VERSION "HNNBNNNYNNNNNNNNNNNNNNNNNNNNNNNNNNNNNNNNNN/4/%%%/4/'%**4NNN///"

NS_ :

BS_:

BU_: AFS Airbag Allrad BAP_Tester BMS_Hybrid Bremse_MK60EC Bremse_MK70MABS Bremse_TRW_EBC450M Bremse_TRW_ESP Daempfer EPB_TRW EPB_TRW_VW411CS FLA Gateway_PQ35 Gateway_Zusatz_EGolf Getriebe_AG6 Getriebe_DQ Getriebe_DQ_Hyb Getriebe_Sele Gurtmikro_PQ35 HCA Ladegeraet_EGolf LEH_Hybrid LH_EPS_APA LH_EPS_ZF_2G LH_EPS_ZF_3G LPG_Interface_Box LWR LWS Magne_Ride Motor_Diesel Motor_EGolf Motor_Hybrid Motor_Otto PDC_PLA Quersperre_VAQ RKA_Plus SAK Waehlhebel Waehlhebel_Sele

BO_ 1160 Motor_6: 8 Motor_Diesel
 SG_ MO6_Checksum : 0|8@1+ (1,0) [0|255] "" Vector__XXX
 SG_ MO6_SollM_Getr : 8|8@1+ (0.39,0) [0|99.06] "Unit_PerCent"  Getriebe_DQ,Getriebe_DQ_Hyb,Getriebe_Sele
 SG_ MO6_Ist_Moment : 16|8@1+ (0.39,0) [0|99.06] "Unit_PerCent"  Gateway_PQ35,Getriebe_AG6,Getriebe_DQ,Getriebe_DQ_Hyb,Getriebe_Sele
 SG_ MO6_Hoeheninfo : 24|8@1+ (0.0078125,0) [0|1.984375] ""  Getriebe_DQ,Getriebe_DQ_Hyb
 SG_ MO6_GRA_Soll : 32|8@1+ (0.024,-3.984) [-3.984|2.088] "Unit_MeterPerSeconSquar"  Getriebe_AG6,Getriebe_DQ,Getriebe_DQ_Hyb
 SG_ MO6_MomIntGeEing : 40|8@1+ (0.392156862745098,0) [0|100] "Unit_PerCent"  Getriebe_DQ,Getriebe_DQ_Hyb
 SG_ MO6_FF_Mux00 m0 : 48|8@1+ (0.392156862745098,0) [0|100] "Unit_PerCent"  BMS_Hybrid,Getriebe_DQ,Getriebe_DQ_Hyb,Getriebe_Sele,LEH_Hybrid
 SG_ MO6_FF_Mux01 m1 : 48|8@1+ (0.392156862745098,0) [0|100] "Unit_PerCent"  BMS_Hybrid,Getriebe_DQ,Getriebe_DQ_Hyb,Getriebe_Sele,LEH_Hybrid
 SG_ MO6_FF_Mux02 m2 : 48|8@1+ (1,-40) [-40|215] "Unit_DegreCelsi"  BMS_Hybrid,Getriebe_DQ,Getriebe_DQ_Hyb,Getriebe_Sele,LEH_Hybrid
 SG_ MO6_FF_Mux03 m3 : 48|8@1+ (3.13725490196078,0) [0|799.999999999999] "Unit_PerCent"  BMS_Hybrid,Getriebe_DQ,Getriebe_DQ_Hyb,Getriebe_Sele,LEH_Hybrid
 SG_ MO6_FF_Mux04 m4 : 48|8@1+ (0.392156862745098,0) [0|100] "Unit_PerCent"  BMS_Hybrid,Getriebe_DQ,Getriebe_DQ_Hyb,Getriebe_Sele,LEH_Hybrid
 SG_ MO6_FF_Mux05 m5 : 48|8@1+ (1,0) [0|255] "" Vector__XXX
 SG_ MO6_FF_Mux06 m6 : 48|8@1+ (1,0) [0|255] "" Vector__XXX
 SG_ MO6_FF_Mux07 m7 : 48|8@1+ (1,0) [0|255] "" Vector__XXX
 SG_ MO6_FF_Mux08 m8 : 48|8@1+ (1,0) [0|255] "" Vector__XXX
 SG_ MO6_FF_Mux09 m9 : 48|8@1+ (1,0) [0|255] "" Vector__XXX
 SG_ MO6_FF_Mux10 m10 : 48|8@1+ (1,0) [0|255] "" Vector__XXX
 SG_ MO6_FF_Mux11 m11 : 48|8@1+ (1,0) [0|255] "" Vector__XXX
 SG_ MO6_FF_Mux12 m12 : 48|8@1+ (1,0) [0|255] "" Vector__XXX
 SG_ MO6_FF_Mux13 m13 : 48|8@1+ (1,0) [0|255] "" Vector__XXX
 SG_ MO6_FF_Mux14 m14 : 48|8@1+ (1,0) [0|255] "" Vector__XXX
 SG_ MO6_FF_Mux15 m15 : 48|8@1+ (1,0) [0|255] "" Vector__XXX
 SG_ MO6_Freigabe_GRA : 56|1@1+ (1,0) [0|1] ""  Getriebe_DQ,Getriebe_DQ_Hyb
 SG_ MO6_Schutz_Toel : 57|1@1+ (1,0) [0|1] "" Vector__XXX
 SG_ MO6_Luftpfad_akt : 58|1@1+ (1,0) [0|1] "" Vector__XXX
 SG_ MO6_RegPartikel : 59|1@1+ (1,0) [0|1] ""  Getriebe_AG6,Getriebe_DQ,Getriebe_DQ_Hyb
 SG_ MO6_Zaehler M : 60|4@1+ (1,0) [0|15] ""  BMS_Hybrid,Getriebe_DQ,Getriebe_DQ_Hyb,LEH_Hybrid

BO_ 1416 Motor_7: 8 Motor_Diesel
 SG_ MO7_LL_Solldz : 0|1@1+ (1,0) [0|1] ""  Gateway_PQ35
 SG_ MO7_Fehler_VBegr : 1|1@1+ (1,0) [0|1] ""  Gateway_PQ35
 SG_ MO7_Sta_VBegr : 2|1@1+ (1,0) [0|1] ""  Gateway_PQ35,Getriebe_DQ,Getriebe_DQ_Hyb
 SG_ MO7_Fehlereintr : 3|1@1+ (1,0) [0|1] ""  Gateway_PQ35
 SG_ MO7_StaOeltemp : 4|1@1+ (1,0) [0|1] ""  Gateway_PQ35,Getriebe_DQ,Getriebe_DQ_Hyb
 SG_ MO7_Sta_PTC : 5|3@1+ (1,0) [0|7] ""  Gateway_PQ35
 SG_ MO7_DFM : 8|8@1+ (0.4,0) [0|101.6] "Unit_PerCent"  Gateway_PQ35
 SG_ MO7_Hoeheninfo : 16|8@1+ (0.0078125,0) [0|1.984375] ""  Bremse_MK60EC,Bremse_MK70MABS,Bremse_TRW_EBC450M,Bremse_TRW_ESP,Gateway_PQ35,Getriebe_DQ,Getriebe_DQ_Hyb,Getriebe_Sele
 SG_ MO7_Gradient_Dz : 24|7@1+ (1,0) [0|126] "Unit_MinutInver"  Gateway_PQ35
 SG_ MO7_GradientVorz : 31|1@1+ (1,0) [0|1] ""  Gateway_PQ35
 SG_ MO7_Ladedruckneu : 32|8@1+ (0.02,0) [0|5.08] "Unit_Bar"  Gateway_PQ35
 SG_ MO7_GenLdResp : 40|2@1+ (3,0) [0|9] "Unit_Secon"  Gateway_PQ35
 SG_ MO7_PTC_bereit : 42|2@1+ (1,0) [0|3] ""  Gateway_PQ35
 SG_ MO7_Mot_weckfaehig : 44|1@1+ (1,0) [0|1] ""  Gateway_PQ35
 SG_ MO7_Zus_Kuehl : 45|1@1+ (1,0) [0|1] ""  Gateway_PQ35
 SG_ MO7_SleepInd : 46|1@1+ (1,0) [0|1] ""  Gateway_PQ35
 SG_ MO7_RueckLLDz : 47|1@1+ (1,0) [0|1] ""  Gateway_PQ35
 SG_ MO7_Lastabwurf : 48|2@1+ (1,0) [0|3] ""  Gateway_PQ35
 SG_ MO7_Gen_ein : 50|1@1+ (1,0) [0|1] ""  Gateway_PQ35
 SG_ MO7_Lastabw_Heiz : 51|1@1+ (1,0) [0|1] ""  Gateway_PQ35
 SG_ MO7_StaGluehk : 52|4@1+ (8,0) [0|112] "Unit_PerCent"  Gateway_PQ35
 SG_ MO7_Oeltemp : 56|8@1+ (1,-60) [-58|194] "Unit_DegreCelsi"  Gateway_PQ35,Getriebe_DQ,Getriebe_DQ_Hyb,Getriebe_Sele

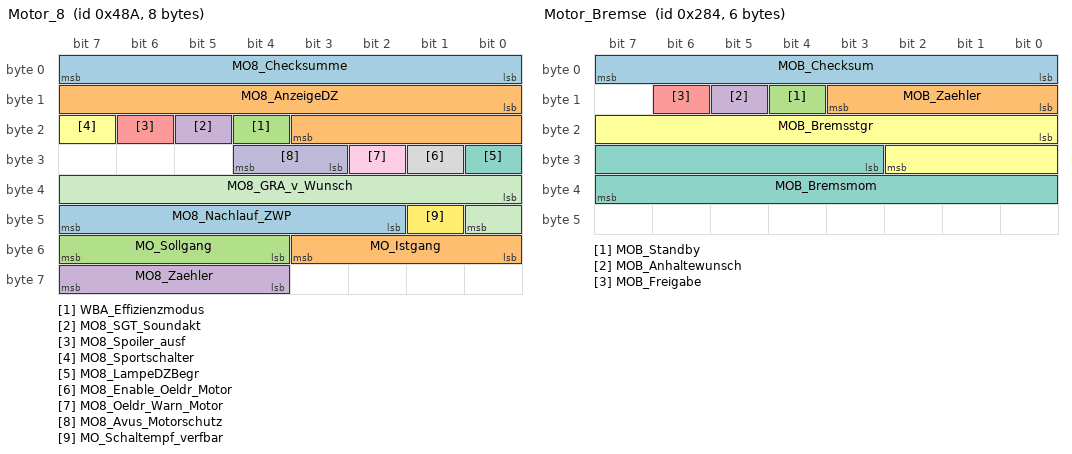
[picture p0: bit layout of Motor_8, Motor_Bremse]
BO_ 1162 Motor_8: 8 Motor_Diesel
 SG_ MO8_Checksumme : 0|8@1+ (1,0) [0|255] ""  Gateway_PQ35,Magne_Ride
 SG_ MO8_AnzeigeDZ : 8|12@1+ (3,0) [0|12282] "Unit_MinutInver"  Gateway_PQ35
 SG_ WBA_Effizienzmodus : 20|1@1+ (1,0) [0|1] ""  Gateway_PQ35
 SG_ MO8_SGT_Soundakt : 21|1@1+ (1,0) [0|1] ""  Gateway_PQ35,SAK
 SG_ MO8_Spoiler_ausf : 22|1@1+ (1,0) [0|1] ""  Gateway_PQ35
 SG_ MO8_Sportschalter : 23|1@1+ (1,0) [0|1] ""  Gateway_PQ35,Getriebe_Sele,Magne_Ride
 SG_ MO8_LampeDZBegr : 24|1@1+ (1,0) [0|1] ""  Gateway_PQ35,Getriebe_Sele
 SG_ MO8_Enable_Oeldr_Motor : 25|1@1+ (1,0) [0|1] ""  Gateway_PQ35
 SG_ MO8_Oeldr_Warn_Motor : 26|1@1+ (1,0) [0|1] ""  Gateway_PQ35
 SG_ MO8_Avus_Motorschutz : 27|2@1+ (1,0) [0|3] ""  Gateway_PQ35,Getriebe_Sele
 SG_ MO8_GRA_v_Wunsch : 32|9@1+ (1,0) [0|511] "Unit_KiloMeterPerHour"  Gateway_PQ35
 SG_ MO_Schaltempf_verfbar : 41|1@1+ (1,0) [0|1] ""  Gateway_PQ35
 SG_ MO8_Nachlauf_ZWP : 42|6@1+ (15,0) [0|945] "Unit_Secon"  Gateway_PQ35
 SG_ MO_Istgang : 48|4@1+ (1,0) [0|15] ""  Gateway_PQ35
 SG_ MO_Sollgang : 52|4@1+ (1,0) [0|15] ""  Gateway_PQ35
 SG_ MO8_Zaehler : 60|4@1+ (1,0) [0|15] ""  Gateway_PQ35,Magne_Ride

BO_ 644 Motor_Bremse: 6 Motor_Diesel
 SG_ MOB_Checksum : 0|8@1+ (1,0) [0|255] ""  Bremse_MK60EC,Bremse_TRW_EBC450M,Bremse_TRW_ESP
 SG_ MOB_Zaehler : 8|4@1+ (1,0) [0|15] ""  Bremse_MK60EC,Bremse_TRW_EBC450M,Bremse_TRW_ESP
 SG_ MOB_Standby : 12|1@1+ (1,0) [0|1] ""  Bremse_MK60EC,Bremse_TRW_EBC450M,Bremse_TRW_ESP
 SG_ MOB_Anhaltewunsch : 13|1@1+ (1,0) [0|1] ""  Bremse_TRW_EBC450M,Bremse_TRW_ESP,Getriebe_DQ
 SG_ MOB_Freigabe : 14|1@1+ (1,0) [0|1] ""  Bremse_MK60EC,Bremse_TRW_EBC450M,Bremse_TRW_ESP,Gateway_PQ35
 SG_ MOB_Bremsstgr : 16|11@1+ (0.0488519785051295,0) [0|100] "Unit_PerCent"  Bremse_TRW_EBC450M,Bremse_TRW_ESP
 SG_ MOB_Bremsmom : 27|13@1+ (4,0) [0|32760] "Unit_NewtoMeter"  Bremse_MK60EC

BO_ 1800 Motor_CNG_1: 5 Motor_Otto
 SG_ MC1_Anz_Betrieb : 0|1@1+ (1,0) [0|1] ""  Gateway_PQ35
 SG_ MC1_Schalter : 1|1@1+ (1,0) [0|1] ""  Gateway_PQ35
 SG_ MC1_akt_Betrieb : 2|1@1+ (1,0) [0|1] ""  Gateway_PQ35
 SG_ MC1_CNG_LPG M : 3|1@1+ (1,0) [0|1] ""  Gateway_PQ35
 SG_ MO_LPG_Tankstopp m1 : 4|1@1+ (1,0) [0|1] ""  Gateway_PQ35
 SG_ MO_Erdgasqualitaet : 5|3@1+ (1,0) [0|7] ""  Gateway_PQ35
 SG_ MC1_Fuellungsgrad : 8|8@1+ (0.4,0) [0|101.6] "Unit_PerCent"  Gateway_PQ35
 SG_ MC1_Verbrauch m0 : 16|15@1+ (1,0) [0|32767] "Unit_MilliGram"  Gateway_PQ35
 SG_ MC1_Verbrauch_LPG m1 : 16|15@1+ (1,0) [0|32767] "Unit_MicroLiter"  Gateway_PQ35
 SG_ MC1_Ueb_Verbr : 31|1@1+ (1,0) [0|1] ""  Gateway_PQ35
 SG_ MO_AnzeigeGasbetrieb : 32|4@1+ (1,0) [0|15] ""  Gateway_PQ35

BO_ 1408 Motor_Flexia_neu: 8 Motor_Diesel
 SG_ MFN_Zaehler M : 0|2@1+ (1,0) [0|3] ""  Bremse_TRW_EBC450M,Bremse_TRW_ESP,EPB_TRW,EPB_TRW_VW411CS,Gateway_PQ35,Gateway_Zusatz_EGolf
 SG_ MFN_Zaehler_ : 2|2@1+ (1,0) [0|3] ""  Bremse_TRW_EBC450M,Bremse_TRW_ESP,EPB_TRW,EPB_TRW_VW411CS,Gateway_PQ35,Gateway_Zusatz_EGolf
 SG_ MFN_Drive_Cycle : 4|1@1+ (1,0) [0|1] ""  BMS_Hybrid,Gateway_PQ35,Gateway_Zusatz_EGolf,Getriebe_AG6,Getriebe_DQ,Getriebe_DQ_Hyb,Getriebe_Sele,LEH_Hybrid
 SG_ MFN_Warmup_Cycle : 5|1@1+ (1,0) [0|1] ""  BMS_Hybrid,Bremse_TRW_ESP,Gateway_PQ35,Gateway_Zusatz_EGolf,Getriebe_AG6,Getriebe_DQ,Getriebe_DQ_Hyb,Getriebe_Sele,LEH_Hybrid
 SG_ MFN_NormedTrip : 6|1@1+ (1,0) [0|1] ""  BMS_Hybrid,Gateway_PQ35,Gateway_Zusatz_EGolf,Getriebe_AG6,Getriebe_DQ,Getriebe_DQ_Hyb,Getriebe_Sele,LEH_Hybrid
 SG_ MFN_Verbrenn_Typ : 7|1@1+ (1,0) [0|1] ""  Bremse_TRW_EBC450M,Bremse_TRW_ESP,EPB_TRW,EPB_TRW_VW411CS,Gateway_PQ35,Gateway_Zusatz_EGolf,Getriebe_DQ,Getriebe_DQ_Hyb
 SG_ MFN_Russindex m0 : 8|16@1+ (2E-008,0) [0|0.00131068] ""  Gateway_PQ35,Gateway_Zusatz_EGolf
 SG_ MFN_Verschl m1 : 8|16@1+ (2E-008,0) [0|0.00131068] ""  Gateway_PQ35,Gateway_Zusatz_EGolf
 SG_ MFN_Russindex_ m2 : 8|16@1+ (2E-008,0) [0|0.00131068] ""  Gateway_PQ35,Gateway_Zusatz_EGolf
 SG_ MFN_Verschl_ m3 : 8|16@1+ (2E-008,0) [0|0.00131068] ""  Gateway_PQ35,Gateway_Zusatz_EGolf
 SG_ MFN_Drz_max_Mo m0 : 24|8@1+ (100,0) [0|25500] "Unit_MinutInver"  Gateway_PQ35,Gateway_Zusatz_EGolf
 SG_ MFN_KurzzeitMW m1 : 24|8@1+ (15,-1905) [-1890|1905] "Unit_MilliLiter"  Gateway_PQ35,Gateway_Zusatz_EGolf
 SG_ MFN_Drz_max_Mo_ m2 : 24|8@1+ (100,0) [0|25500] "Unit_MinutInver"  Gateway_PQ35,Gateway_Zusatz_EGolf
 SG_ MFN_Interv_Wmin m3 : 24|7@1+ (1000,0) [0|127000] "Unit_KiloMeter"  Gateway_PQ35,Gateway_Zusatz_EGolf
 SG_ MFN_Fuell_Erk m3 : 31|1@1+ (1,0) [0|1] ""  Gateway_PQ35,Gateway_Zusatz_EGolf
 SG_ MFN_max_Moment m0 : 32|8@1+ (10,0) [0|2550] "Unit_NewtoMeter"  Gateway_PQ35,Gateway_Zusatz_EGolf
 SG_ MFN_Oelstand m1 : 32|6@1+ (1,0) [0|63] ""  Gateway_PQ35,Gateway_Zusatz_EGolf
 SG_ MFN_max_Moment_ m2 : 32|8@1+ (10,0) [0|2550] "Unit_NewtoMeter"  Gateway_PQ35,Gateway_Zusatz_EGolf
 SG_ MFN_Interv_Wmax m3 : 32|7@1+ (1000,0) [0|127000] "Unit_KiloMeter"  Gateway_PQ35,Gateway_Zusatz_EGolf
 SG_ MFN_Oelwarnung m1 : 38|1@1+ (1,0) [0|1] ""  Gateway_PQ35,Gateway_Zusatz_EGolf
 SG_ MFN_Sensorwarn m1 : 39|1@1+ (1,0) [0|1] ""  Gateway_PQ35,Gateway_Zusatz_EGolf
 SG_ MFN_MaxOelst m3 : 39|5@1+ (100,0) [0|3100] "Unit_MilliLiter"  Gateway_PQ35,Gateway_Zusatz_EGolf
 SG_ MFN_Motorleistung m0 : 40|9@1+ (1,0) [0|511] "Unit_KiloWatt"  Bremse_TRW_EBC450M,Bremse_TRW_ESP,EPB_TRW,Gateway_PQ35,Gateway_Zusatz_EGolf
 SG_ MFN_AnzMitOel m1 : 40|4@1+ (100,0) [0|1500] ""  Gateway_PQ35,Gateway_Zusatz_EGolf
 SG_ MFN_Motorleistung_ m2 : 40|9@1+ (1,0) [0|511] "Unit_KiloWatt"  Bremse_TRW_EBC450M,Bremse_TRW_ESP,EPB_TRW,Gateway_PQ35,Gateway_Zusatz_EGolf
 SG_ MFN_Max_Offset m1 : 44|4@1+ (50,0) [0|750] "Unit_MilliLiter"  Gateway_PQ35,Gateway_Zusatz_EGolf
 SG_ MFN_Anz_Mittel m3 : 44|4@1+ (500,0) [500|7500] ""  Gateway_PQ35,Gateway_Zusatz_EGolf
 SG_ MFN_Fuell_Hyst m1 : 48|4@1+ (50,0) [0|750] "Unit_MilliLiter"  Gateway_PQ35,Gateway_Zusatz_EGolf
 SG_ MFN_Interv_tmin m3 : 48|6@1+ (1,0) [0|63] "Unit_Month"  Gateway_PQ35,Gateway_Zusatz_EGolf
 SG_ MFN_Ventile m0 : 49|3@1+ (1,0) [0|7] ""  Gateway_PQ35,Gateway_Zusatz_EGolf
 SG_ MFN_Ventile_ m2 : 49|3@1+ (1,0) [0|7] ""  Gateway_PQ35,Gateway_Zusatz_EGolf
 SG_ MFN_Zylinder m0 : 52|4@1+ (1,0) [0|15] ""  EPB_TRW,Gateway_PQ35,Gateway_Zusatz_EGolf
 SG_ MFN_Offset_Nachf m1 : 52|6@1+ (10,0) [0|630] "Unit_MilliLiter"  Gateway_PQ35,Gateway_Zusatz_EGolf
 SG_ MFN_Zylinder_ m2 : 52|4@1+ (1,0) [0|15] ""  EPB_TRW,Gateway_PQ35,Gateway_Zusatz_EGolf
 SG_ MFN_Interv_tmax m3 : 54|6@1+ (1,0) [0|63] "Unit_Month"  Gateway_PQ35,Gateway_Zusatz_EGolf
 SG_ MFN_Hubraum m0 : 56|7@1+ (0.1,0) [0|12.7] "Unit_Liter"  Bremse_TRW_EBC450M,Bremse_TRW_ESP,EPB_TRW,Gateway_PQ35,Gateway_Zusatz_EGolf
 SG_ MFN_Hubraum_ m2 : 56|7@1+ (0.1,0) [0|12.7] "Unit_Liter"  Bremse_TRW_EBC450M,Bremse_TRW_ESP,EPB_TRW,Gateway_PQ35,Gateway_Zusatz_EGolf
 SG_ MFN_Tol_Oelwarn m1 : 58|6@1+ (10,0) [0|630] "Unit_MilliLiter"  Gateway_PQ35,Gateway_Zusatz_EGolf
 SG_ MFN_Str_Mittel m3 : 60|4@1+ (25,0) [25|375] "Unit_KiloMeter"  Gateway_PQ35,Gateway_Zusatz_EGolf
 SG_ MFN_Ansaugsys m0 : 63|1@1+ (1,0) [0|1] ""  Bremse_TRW_EBC450M,Bremse_TRW_ESP,Gateway_PQ35,Gateway_Zusatz_EGolf
 SG_ MFN_Ansaugsys_ m2 : 63|1@1+ (1,0) [0|1] ""  Bremse_TRW_EBC450M,Bremse_TRW_ESP,Gateway_PQ35,Gateway_Zusatz_EGolf

BO_ 1154 Motor_Hybrid_1: 8 Motor_Hybrid
 SG_ MH1_VM_Mom_oE : 0|8@1+ (0.8,-100) [-100|103.2] "Unit_PerCent"  Getriebe_DQ_Hyb
 SG_ MH1_IstStatusK0 : 8|2@1+ (1,0) [0|3] ""  Getriebe_DQ_Hyb
 SG_ MH1_Startmodus_PQ35 : 10|1@1+ (1,0) [0|1] ""  Getriebe_DQ_Hyb
 SG_ MH1_VM_aktiv : 11|1@1+ (1,0) [0|1] ""  Getriebe_DQ_Hyb
 SG_ MH1_Zielzustand_Hybrid : 12|3@1+ (1,0) [0|7] ""  Getriebe_DQ_Hyb
 SG_ MH1_Schaltverh : 15|1@1+ (1,0) [0|1] ""  Getriebe_DQ_Hyb
 SG_ MH1_VerlParam_Msum m1 : 16|2@1+ (1,0) [0|3] ""  Getriebe_DQ_Hyb
 SG_ MH1_MomVerlauf_EM m1 : 18|6@1+ (5,0) [0|315] "Unit_NewtoMeter"  Getriebe_DQ_Hyb
 SG_ MH1_E_Faktor m0 : 20|4@1+ (1,0) [0|15] ""  Getriebe_DQ_Hyb
 SG_ MH1_Drehzahl_VM : 24|16@1+ (0.25,0) [0|16256] "Unit_MinutInver"  Getriebe_DQ_Hyb
 SG_ MH1_max_ind_VM_Mom : 40|8@1+ (0.39,0) [0|99.06] "Unit_PerCent" Vector__XXX
 SG_ MH1_Startmodus_PL71 : 48|3@1+ (1,0) [0|7] "" Vector__XXX
 SG_ MH1_LowSpeedModus : 51|1@1+ (1,0) [0|1] ""  Getriebe_DQ_Hyb
 SG_ MH1_ACCGRA_aktiv M : 52|1@1+ (1,0) [0|1] ""  Getriebe_DQ_Hyb
 SG_ MH1_QB_Bremspedalwert : 55|1@1+ (1,0) [0|1] "" Vector__XXX
 SG_ MH1_Bremspedalwert : 56|8@1+ (0.4,0) [0|100] "Unit_PerCent"  Getriebe_DQ_Hyb

BO_ 399 mMotor_LPG_01: 8 Motor_Otto
 SG_ Motor_LPG_01_Reserve : 0|64@1+ (1,0) [0|1.84467440737096E+019] ""  LPG_Interface_Box

BO_ 1823 Motorslave_Istverbau: 1 Motor_Otto
 SG_ MSI_KD_Fehler : 0|1@1+ (1,0) [0|1] ""  Gateway_PQ35

BO_ 1428 Niveau_2: 8 Daempfer
 SG_ NI2_Checksum : 0|8@1+ (1,0) [0|255] ""  AFS,Gateway_PQ35,LWR
 SG_ NI2_Zaehler : 8|4@1+ (1,0) [0|15] ""  AFS,Gateway_PQ35,LWR
 SG_ NI2_Hoehenflag M : 12|1@1+ (1,0) [0|1] ""  AFS,Gateway_PQ35
 SG_ NI2_Hoehe_VL m0 : 16|8@1+ (1,-127) [-127|126] "Unit_MilliMeter"  AFS,Gateway_PQ35,LWR
 SG_ NI2_Hoehe_VL_Roh m1 : 16|8@1+ (0.4,0) [0|100] "Unit_PerCent"  AFS,Gateway_PQ35
 SG_ NI2_Hoehe_VR m0 : 24|8@1+ (1,-127) [-127|126] "Unit_MilliMeter"  AFS,Gateway_PQ35,LWR
 SG_ NI2_Hoehe_VR_Roh m1 : 24|8@1+ (0.4,0) [0|100] "Unit_PerCent"  AFS,Gateway_PQ35
 SG_ NI2_Hoehe_HL m0 : 32|8@1+ (1,-127) [-127|126] "Unit_MilliMeter"  AFS,Gateway_PQ35,LWR
 SG_ NI2_Hoehe_HL_Roh m1 : 32|8@1+ (0.4,0) [0|100] "Unit_PerCent"  AFS,Gateway_PQ35
 SG_ NI2_Hoehe_HR m0 : 40|8@1+ (1,-127) [-127|126] "Unit_MilliMeter"  AFS,Gateway_PQ35,LWR
 SG_ NI2_Hoehe_HR_Roh m1 : 40|8@1+ (0.4,0) [0|100] "Unit_PerCent"  AFS,Gateway_PQ35
 SG_ NI2_AufbBeschl_VL : 48|8@1+ (0.08,-10.08) [-10.08|10.08] "Unit_MeterPerSeconSquar"  AFS,Gateway_PQ35
 SG_ NI2_AufbBeschl_VR : 56|8@1+ (0.08,-10.08) [-10.08|10.08] "Unit_MeterPerSeconSquar"  AFS,Gateway_PQ35

BO_ 1349 Parkhilfe_3: 4 Vector__XXX
 SG_ PA3_System_codierung : 0|1@1+ (1,0) [0|1] ""  Gateway_PQ35
 SG_ PA3_Anlage_defekt : 1|1@1+ (1,0) [0|1] ""  Gateway_PQ35
 SG_ PA3_Taster_aktiviert : 2|1@1+ (1,0) [0|1] ""  Gateway_PQ35
 SG_ PA3_Rueckwaertsgang_aktiv : 3|1@1+ (1,0) [0|1] ""  Gateway_PQ35
 SG_ PA3_Geschwindigkeit_aus : 4|1@1+ (1,0) [0|1] ""  Gateway_PQ35
 SG_ PA3_Tongeber_v_defekt : 5|1@1+ (1,0) [0|1] ""  Gateway_PQ35
 SG_ PA3_Tongeber_h_defekt : 6|1@1+ (1,0) [0|1] ""  Gateway_PQ35
 SG_ PA3_Audioabsenkung_Anforderung : 7|1@1+ (1,0) [0|1] ""  Gateway_PQ35
 SG_ PA3_Eis_aus : 8|1@1+ (1,0) [0|1] ""  Gateway_PQ35
 SG_ PA3_Schlechtweg_aus : 9|1@1+ (1,0) [0|1] ""  Gateway_PQ35
 SG_ PA3_KD_Fehler : 15|1@1+ (1,0) [0|1] ""  Gateway_PQ35
 SG_ PA3_Sensor_hll_defekt : 16|1@1+ (1,0) [0|1] ""  Gateway_PQ35
 SG_ PA3_Sensor_hlm_defekt : 17|1@1+ (1,0) [0|1] ""  Gateway_PQ35
 SG_ PA3_Sensor_hrm_defekt : 18|1@1+ (1,0) [0|1] ""  Gateway_PQ35
 SG_ PA3_Sensor_hrr_defekt : 19|1@1+ (1,0) [0|1] ""  Gateway_PQ35
 SG_ PA3_Sensor_vll_defekt : 20|1@1+ (1,0) [0|1] ""  Gateway_PQ35
 SG_ PA3_Sensor_vlm_defekt : 21|1@1+ (1,0) [0|1] ""  Gateway_PQ35
 SG_ PA3_Sensor_vrm_defekt : 22|1@1+ (1,0) [0|1] ""  Gateway_PQ35
 SG_ PA3_Sensor_vrr_defekt : 23|1@1+ (1,0) [0|1] ""  Gateway_PQ35
 SG_ PA3_Bereit : 24|1@1+ (1,0) [0|1] ""  Gateway_PQ35
 SG_ PA3_Bereich_vo : 26|2@1+ (1,0) [0|3] ""  Gateway_PQ35
 SG_ PA3_Bereich_hi : 28|2@1+ (1,0) [0|3] ""  Gateway_PQ35
 SG_ PA3_Akust_aus : 30|1@1+ (1,0) [0|1] ""  Gateway_PQ35
 SG_ PA3_Aufbau_erk : 31|1@1+ (1,0) [0|1] ""  Gateway_PQ35

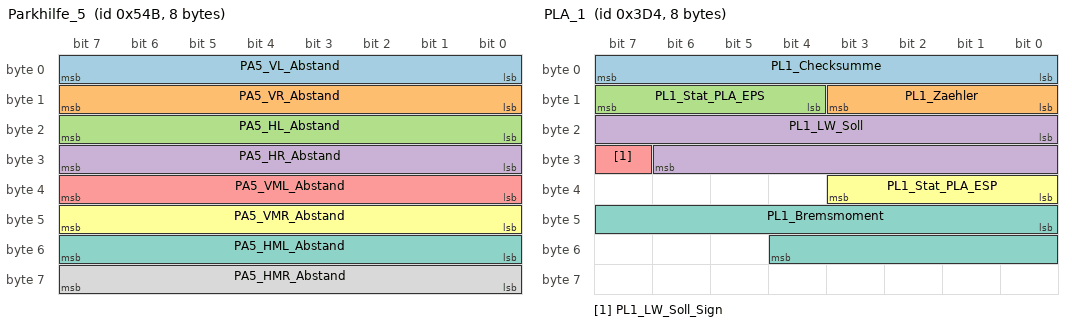
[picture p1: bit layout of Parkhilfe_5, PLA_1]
BO_ 1355 Parkhilfe_5: 8 PDC_PLA
 SG_ PA5_VL_Abstand : 0|8@1+ (1,0) [0|254] "Unit_CentiMeter"  Gateway_PQ35
 SG_ PA5_VR_Abstand : 8|8@1+ (1,0) [0|254] "Unit_CentiMeter"  Gateway_PQ35
 SG_ PA5_HL_Abstand : 16|8@1+ (1,0) [0|254] "Unit_CentiMeter"  Gateway_PQ35
 SG_ PA5_HR_Abstand : 24|8@1+ (1,0) [0|254] "Unit_CentiMeter"  Gateway_PQ35
 SG_ PA5_VML_Abstand : 32|8@1+ (1,0) [0|254] "Unit_CentiMeter"  Gateway_PQ35
 SG_ PA5_VMR_Abstand : 40|8@1+ (1,0) [0|254] "Unit_CentiMeter"  Gateway_PQ35
 SG_ PA5_HML_Abstand : 48|8@1+ (1,0) [0|254] "Unit_CentiMeter"  Gateway_PQ35
 SG_ PA5_HMR_Abstand : 56|8@1+ (1,0) [0|254] "Unit_CentiMeter"  Gateway_PQ35

BO_ 980 PLA_1: 8 PDC_PLA
 SG_ PL1_Checksumme : 0|8@1+ (1,0) [0|255] ""  Getriebe_DQ,Getriebe_DQ_Hyb,LH_EPS_APA,LH_EPS_ZF_2G,LH_EPS_ZF_3G
 SG_ PL1_Zaehler : 8|4@1+ (1,0) [0|15] ""  Bremse_TRW_EBC450M,Getriebe_DQ,Getriebe_DQ_Hyb,LH_EPS_APA,LH_EPS_ZF_2G,LH_EPS_ZF_3G
 SG_ PL1_Stat_PLA_EPS : 12|4@1+ (1,0) [0|15] ""  LH_EPS_APA,LH_EPS_ZF_2G,LH_EPS_ZF_3G
 SG_ PL1_LW_Soll : 16|15@1+ (0.04375,0) [0|1433.55625] "Unit_DegreOfArc"  LH_EPS_APA,LH_EPS_ZF_2G,LH_EPS_ZF_3G
 SG_ PL1_LW_Soll_Sign : 31|1@1+ (1,0) [0|1] ""  LH_EPS_APA,LH_EPS_ZF_2G,LH_EPS_ZF_3G
 SG_ PL1_Stat_PLA_ESP : 32|4@1+ (1,0) [0|15] ""  Bremse_MK60EC,Bremse_TRW_EBC450M,Bremse_TRW_ESP
 SG_ PL1_Bremsmoment : 40|13@1+ (4,0) [0|32760] "Unit_NewtoMeter"  Bremse_MK60EC,Bremse_TRW_EBC450M,Bremse_TRW_ESP,Getriebe_DQ,Getriebe_DQ_Hyb

BO_ 1494 PLA_Status: 5 PDC_PLA
 SG_ PLS_Anf_Anz : 0|1@1+ (1,0) [0|1] ""  Gateway_PQ35
 SG_ PLS_Akustik1 : 1|1@1+ (1,0) [0|1] ""  Gateway_PQ35
 SG_ PLS_PL_Exist : 2|1@1+ (1,0) [0|1] ""  Gateway_PQ35
 SG_ PLS_Akustik2 : 3|1@1+ (1,0) [0|1] ""  Gateway_PQ35
 SG_ PLS_Mehrzg_Aktiv : 4|1@1+ (1,0) [0|1] ""  Gateway_PQ35
 SG_ PLS_Pos_OK : 5|1@1+ (1,0) [0|1] ""  Gateway_PQ35
 SG_ PLS_PL_Seite : 6|1@1+ (1,0) [0|1] ""  Gateway_PQ35
 SG_ PLS_Lenk_Aktiv_Hinweis : 7|1@1+ (1,0) [0|1] ""  Gateway_PQ35
 SG_ PLS_Meldungen : 8|5@1+ (1,0) [0|31] ""  Gateway_PQ35
 SG_ PLS_Fahrtrichtg_Mehrzg : 13|1@1+ (1,0) [0|1] ""  Gateway_PQ35
 SG_ PLS_Text_Multiplexer : 14|2@1+ (1,0) [0|3] ""  Gateway_PQ35
 SG_ PLS_Schwellpfeil_rel : 16|4@1+ (1,0) [0|15] ""  Gateway_PQ35
 SG_ PLS_Anf_Anz_Schwellpfeil : 20|1@1+ (1,0) [0|1] ""  Gateway_PQ35
 SG_ PLS_Laengs_Querluecke : 21|1@1+ (1,0) [0|1] ""  Gateway_PQ35
 SG_ PLS_Standby : 22|1@1+ (1,0) [0|1] ""  Gateway_PQ35
 SG_ PLS_Bremssymbol : 23|1@1+ (1,0) [0|1] ""  Gateway_PQ35
 SG_ PLS_Kurze_Luecke : 24|1@1+ (1,0) [0|1] ""  Gateway_PQ35
 SG_ PLS_Schwellpfeil_abs : 25|2@1+ (1,0) [0|3] ""  Gateway_PQ35
 SG_ PLS_Akustik : 27|2@1+ (1,0) [0|3] ""  Gateway_PQ35
 SG_ PLS_Ausparken_Aktiv : 29|1@1+ (1,0) [0|1] ""  Gateway_PQ35
 SG_ PLS_Bremsleuchte : 30|1@1+ (1,0) [0|1] ""  Bremse_MK60EC,Bremse_TRW_ESP,Gateway_PQ35
 SG_ PLS_Texte : 31|7@1+ (1,0) [0|127] ""  Gateway_PQ35

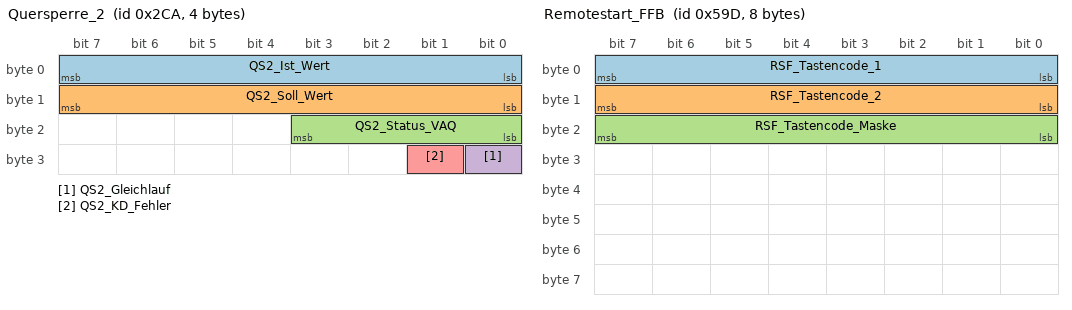
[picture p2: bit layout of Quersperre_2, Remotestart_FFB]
BO_ 714 Quersperre_2: 4 Quersperre_VAQ
 SG_ QS2_Ist_Wert : 0|8@1+ (10,0) [0|2540] "Unit_NewtoMeter"  Bremse_MK60EC
 SG_ QS2_Soll_Wert : 8|8@1+ (10,0) [0|2540] "Unit_NewtoMeter"  Bremse_MK60EC
 SG_ QS2_Status_VAQ : 16|4@1+ (1,0) [0|15] ""  Bremse_MK60EC
 SG_ QS2_Gleichlauf : 24|1@1+ (1,0) [0|1] ""  Bremse_MK60EC
 SG_ QS2_KD_Fehler : 25|1@1+ (1,0) [0|1] ""  Gateway_PQ35

BO_ 1437 Remotestart_FFB: 8 Gateway_PQ35
 SG_ RSF_Tastencode_1 : 0|8@1+ (1,0) [1|255] "Unit_None"  Motor_Diesel,Motor_Otto
 SG_ RSF_Tastencode_2 : 8|8@1+ (1,0) [1|255] "Unit_None"  Motor_Diesel,Motor_Otto
 SG_ RSF_Tastencode_Maske : 16|8@1+ (1,0) [1|255] "Unit_None"  Motor_Diesel,Motor_Otto

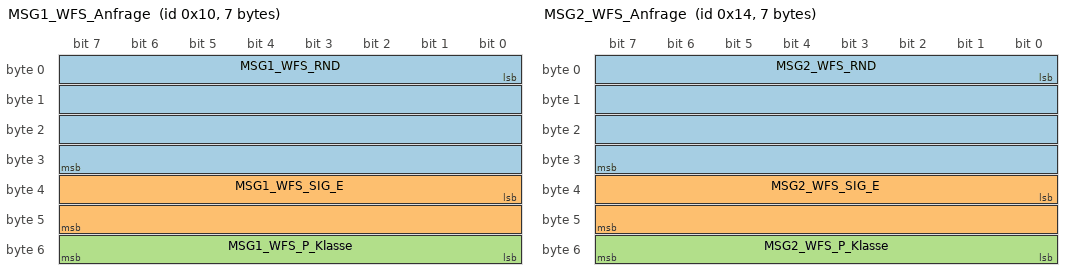
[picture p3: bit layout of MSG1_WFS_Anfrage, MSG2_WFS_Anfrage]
BO_ 16 MSG1_WFS_Anfrage: 7 Vector__XXX
 SG_ MSG1_WFS_RND : 0|32@1+ (1,0) [0|4294967295] ""  Gateway_PQ35
 SG_ MSG1_WFS_SIG_E : 32|16@1+ (1,0) [0|65535] ""  Gateway_PQ35
 SG_ MSG1_WFS_P_Klasse : 48|8@1+ (1,0) [0|255] ""  Gateway_PQ35

BO_ 20 MSG2_WFS_Anfrage: 7 Vector__XXX
 SG_ MSG2_WFS_RND : 0|32@1+ (1,0) [0|4294967295] ""  Gateway_PQ35
 SG_ MSG2_WFS_SIG_E : 32|16@1+ (1,0) [0|65535] ""  Gateway_PQ35
 SG_ MSG2_WFS_P_Klasse : 48|8@1+ (1,0) [0|255] ""  Gateway_PQ35

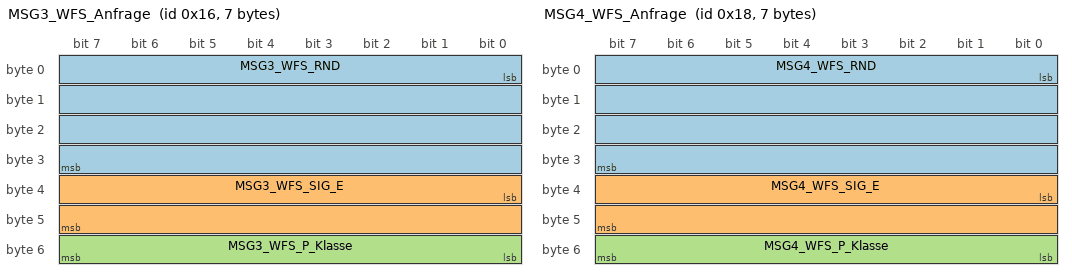
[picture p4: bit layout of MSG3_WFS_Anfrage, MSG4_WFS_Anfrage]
BO_ 22 MSG3_WFS_Anfrage: 7 Vector__XXX
 SG_ MSG3_WFS_RND : 0|32@1+ (1,0) [0|4294967295] ""  Gateway_PQ35
 SG_ MSG3_WFS_SIG_E : 32|16@1+ (1,0) [0|65535] ""  Gateway_PQ35
 SG_ MSG3_WFS_P_Klasse : 48|8@1+ (1,0) [0|255] ""  Gateway_PQ35

BO_ 24 MSG4_WFS_Anfrage: 7 Vector__XXX
 SG_ MSG4_WFS_RND : 0|32@1+ (1,0) [0|4294967295] ""  Gateway_PQ35
 SG_ MSG4_WFS_SIG_E : 32|16@1+ (1,0) [0|65535] ""  Gateway_PQ35
 SG_ MSG4_WFS_P_Klasse : 48|8@1+ (1,0) [0|255] ""  Gateway_PQ35

BO_ 1500 Soll_Verbauliste_neu: 8 Gateway_PQ35
 SG_ VL1_Motor_SG : 0|1@1+ (1,0) [0|1] ""  Bremse_TRW_EBC450M,Bremse_TRW_ESP
 SG_ VL1_Getr_SG : 1|1@1+ (1,0) [0|1] ""  Bremse_TRW_EBC450M,Bremse_TRW_ESP
 SG_ VL1_ABS : 2|1@1+ (1,0) [0|1] ""  Motor_Hybrid,Motor_Otto
 SG_ VL1_Kombi : 3|1@1+ (1,0) [0|1] "" Vector__XXX
 SG_ VL1_LSM : 4|1@1+ (1,0) [0|1] ""  Bremse_TRW_EBC450M,Bremse_TRW_ESP,Motor_Hybrid,Motor_Otto
 SG_ VL1_Airbag : 5|1@1+ (1,0) [0|1] ""  Bremse_TRW_EBC450M,Bremse_TRW_ESP,Motor_Hybrid,Motor_Otto
 SG_ VL1_Lenkhilfe : 6|1@1+ (1,0) [0|1] ""  Bremse_MK60EC
 SG_ VL1_dyn_LWR : 7|1@1+ (1,0) [0|1] "" Vector__XXX
 SG_ VL1_res_08 : 8|1@1+ (1,0) [0|1] "" Vector__XXX
 SG_ VL1_Allrad : 9|1@1+ (1,0) [0|1] ""  Bremse_MK60EC,Bremse_MK70MABS,Bremse_TRW_EBC450M,Bremse_TRW_ESP
 SG_ VL1_ADR : 10|1@1+ (1,0) [0|1] ""  Bremse_MK60EC,Bremse_TRW_EBC450M,Bremse_TRW_ESP
 SG_ VL1_ADR_getrennt : 11|1@1+ (1,0) [0|1] "" Vector__XXX
 SG_ VL1_EPB : 12|1@1+ (1,0) [0|1] "" Vector__XXX
 SG_ VL1_res_13 : 13|1@1+ (1,0) [0|1] "" Vector__XXX
 SG_ VL1_Daempfer : 14|1@1+ (1,0) [0|1] "" Vector__XXX
 SG_ VL1_Quersperre : 15|1@1+ (1,0) [0|1] "" Vector__XXX
 SG_ VL1_MotorSlave : 16|1@1+ (1,0) [0|1] "" Vector__XXX
 SG_ VL1_SWA : 17|1@1+ (1,0) [0|1] "" Vector__XXX
 SG_ VL1_HCA : 18|1@1+ (1,0) [0|1] ""  HCA
 SG_ VL1_RKA_Plus : 19|1@1+ (1,0) [0|1] "" Vector__XXX
 SG_ VL1_PLA : 20|1@1+ (1,0) [0|1] "" Vector__XXX
 SG_ VL1_WFS_KBI : 21|1@1+ (1,0) [0|1] "" Vector__XXX
 SG_ VL1_Kombi_KBI : 22|1@1+ (1,0) [0|1] "" Vector__XXX
 SG_ VL1_Soll_eq_Ist : 23|1@1+ (1,0) [0|1] ""  Bremse_MK60EC,Motor_Hybrid,Motor_Otto
 SG_ VL1_BSG_Komf : 24|1@1+ (1,0) [0|1] ""  Motor_Hybrid,Motor_Otto
 SG_ VL1_ZKE : 25|1@1+ (1,0) [0|1] "" Vector__XXX
 SG_ VL1_TSG_FT : 26|1@1+ (1,0) [0|1] "" Vector__XXX
 SG_ VL1_TSG_BT : 27|1@1+ (1,0) [0|1] "" Vector__XXX
 SG_ VL1_TSG_HL : 28|1@1+ (1,0) [0|1] "" Vector__XXX
 SG_ VL1_TSG_HR : 29|1@1+ (1,0) [0|1] "" Vector__XXX
 SG_ VL1_Memory : 30|1@1+ (1,0) [0|1] "" Vector__XXX
 SG_ VL1_Dachmodul_K : 31|1@1+ (1,0) [0|1] "" Vector__XXX
 SG_ VL1_Zentralelektrik_II : 32|1@1+ (1,0) [0|1] "" Vector__XXX
 SG_ VL1_RDK : 33|1@1+ (1,0) [0|1] "" Vector__XXX
 SG_ VL1_Lenksaeule : 34|1@1+ (1,0) [0|1] ""  Motor_Hybrid,Motor_Otto
 SG_ VL1_Gateway : 35|1@1+ (1,0) [0|1] ""  Motor_Hybrid,Motor_Otto
 SG_ VL1_Clima_Komf : 36|1@1+ (1,0) [0|1] ""  Motor_Diesel,Motor_Hybrid,Motor_Otto
 SG_ VL1_Einparkhilfe : 37|1@1+ (1,0) [0|1] "" Vector__XXX
 SG_ VL1_PTC_Heizung : 38|1@1+ (1,0) [0|1] "" Vector__XXX
 SG_ VL1_Standheiz : 39|1@1+ (1,0) [0|1] "" Vector__XXX
 SG_ VL1_Verdeck : 40|1@1+ (1,0) [0|1] "" Vector__XXX
 SG_ VL1_RSE_I : 41|1@1+ (1,0) [0|1] "" Vector__XXX
 SG_ VL1_res_42 : 42|1@1+ (1,0) [0|1] "" Vector__XXX
 SG_ VL1_MDI_I : 43|1@1+ (1,0) [0|1] "" Vector__XXX
 SG_ VL1_Anhaenger : 44|1@1+ (1,0) [0|1] ""  Bremse_TRW_EBC450M,Bremse_TRW_ESP
 SG_ VL1_Memory_BF : 45|1@1+ (1,0) [0|1] "" Vector__XXX
 SG_ VL1_Easy_Entry_VF : 46|1@1+ (1,0) [0|1] "" Vector__XXX
 SG_ VL1_Easy_Entry_VB : 47|1@1+ (1,0) [0|1] "" Vector__XXX
 SG_ VL1_Heckdeckel : 48|1@1+ (1,0) [0|1] "" Vector__XXX
 SG_ VL1_Rearview : 49|1@1+ (1,0) [0|1] "" Vector__XXX
 SG_ VL1_Sonderfzg_SG : 50|1@1+ (1,0) [0|1] "" Vector__XXX
 SG_ VL1_Tastenmodul : 51|1@1+ (1,0) [0|1] "" Vector__XXX
 SG_ VL1_Kompass : 52|1@1+ (1,0) [0|1] "" Vector__XXX
 SG_ VL1_WFS_K : 53|1@1+ (1,0) [0|1] "" Vector__XXX
 SG_ VL1_GSM_Pager : 54|1@1+ (1,0) [0|1] "" Vector__XXX
 SG_ VL1_InfoElektronik : 55|1@1+ (1,0) [0|1] "" Vector__XXX
 SG_ VL1_DSP : 56|1@1+ (1,0) [0|1] "" Vector__XXX
 SG_ VL1_DAB : 57|1@1+ (1,0) [0|1] "" Vector__XXX
 SG_ VL1_Telematik : 58|1@1+ (1,0) [0|1] "" Vector__XXX
 SG_ VL1_Navigation : 59|1@1+ (1,0) [0|1] "" Vector__XXX
 SG_ VL1_TV_Tuner : 60|1@1+ (1,0) [0|1] "" Vector__XXX
 SG_ VL1_Neigungsmodul_I : 61|1@1+ (1,0) [0|1] "" Vector__XXX
 SG_ VL1_Radio : 62|1@1+ (1,0) [0|1] "" Vector__XXX
 SG_ VL1_Telefon : 63|1@1+ (1,0) [0|1] "" Vector__XXX

BO_ 1488 Systeminfo_1: 8 Gateway_PQ35
 SG_ SY1_CAN_extern : 0|1@1+ (1,0) [0|1] "" Vector__XXX
 SG_ SY1_Diag_Ant : 1|1@1+ (1,0) [0|1] "" Vector__XXX
 SG_ SY1_Sleep_Komf : 2|1@1+ (1,0) [0|1] "" Vector__XXX
 SG_ SY1_Diag_Komf : 3|1@1+ (1,0) [0|1] "" Vector__XXX
 SG_ SY1_Sleep_Info : 4|1@1+ (1,0) [0|1] "" Vector__XXX
 SG_ SY1_Diag_Info : 5|1@1+ (1,0) [0|1] "" Vector__XXX
 SG_ SY1_CAN_Info : 6|1@1+ (1,0) [0|1] "" Vector__XXX
 SG_ SY1_Verbauinfo : 7|1@1+ (1,0) [0|1] ""  Motor_Diesel
 SG_ SY1_Fzg_Klasse : 8|4@1+ (1,0) [0|15] "" Vector__XXX
 SG_ SY1_Fzg_Marke : 12|4@1+ (1,0) [0|15] "" Vector__XXX
 SG_ SY1_Fzg_Derivat : 16|4@1+ (1,0) [0|15] ""  SAK
 SG_ SY1_Fzg_Gen : 20|4@1+ (1,0) [0|15] ""  SAK
 SG_ SY1_Fzg_Index : 24|4@1+ (1,0) [0|15] "" Vector__XXX
 SG_ SY1_Lenker : 28|1@1+ (1,0) [0|1] ""  Bremse_TRW_EBC450M,Bremse_TRW_ESP,Motor_Diesel
 SG_ SY1_Tueren : 29|1@1+ (1,0) [0|1] "" Vector__XXX
 SG_ SY1_Transportmode : 30|1@1+ (1,0) [0|1] ""  Daempfer,Motor_Diesel,Motor_EGolf,Motor_Hybrid,Motor_Otto
 SG_ SY1_Fehlereintr : 31|1@1+ (1,0) [0|1] "" Vector__XXX
 SG_ SY1_Komf_NV : 32|4@1+ (1,0) [0|9] "" Vector__XXX
 SG_ SY1_Komf_HV : 36|4@1+ (1,0) [0|9] "" Vector__XXX
 SG_ SY1_Ant_NV : 40|4@1+ (1,0) [0|9] "" Vector__XXX
 SG_ SY1_Ant_HV : 44|4@1+ (1,0) [0|9] "" Vector__XXX
 SG_ SY1_Relais_FAS_Zweig : 48|2@1+ (1,0) [0|3] ""  Bremse_TRW_EBC450M,Bremse_TRW_ESP,HCA
 SG_ SY1_ELV_Lock_Supply : 50|1@1+ (1,0) [0|1] "" Vector__XXX
 SG_ SY1_QRS_Messmodus : 51|1@1+ (1,0) [0|1] ""  Motor_Diesel,Motor_EGolf,Motor_Hybrid,Motor_Otto
 SG_ SY1_NWDF_gueltig : 54|1@1+ (1,0) [0|1] ""  AFS,FLA,LWR
 SG_ SY1_NWDF : 55|1@1+ (1,0) [0|1] ""  AFS,FLA,LWR
 SG_ SY1_Notbrems_Status : 56|1@1+ (1,0) [0|1] "" Vector__XXX

BO_ 1225 Tele_BMS: 8 BMS_Hybrid
 SG_ Tele_Data_BMS : 0|64@1+ (1,0) [0|1.84467440737096E+019] ""  Gateway_Zusatz_EGolf

BO_TX_BU_ 1160 : Motor_Diesel,Motor_EGolf,Motor_Hybrid,Motor_Otto;
BO_TX_BU_ 1416 : Motor_Diesel,Motor_EGolf,Motor_Hybrid,Motor_Otto;
BO_TX_BU_ 1162 : Motor_Diesel,Motor_EGolf,Motor_Hybrid,Motor_Otto;
BO_TX_BU_ 644 : Motor_Diesel,Motor_Otto;
BO_TX_BU_ 1408 : Motor_Diesel,Motor_EGolf,Motor_Hybrid,Motor_Otto;
BO_TX_BU_ 1428 : Daempfer,Magne_Ride;
CM_ SG_ 1160 MO6_Checksum "Prüfsumme mit Endwert 0x0, Definition im CAN Lastenheft (HS-CAN V4.2a, LS-CAN V1.42)";
CM_ SG_ 1160 MO6_SollM_Getr "Sollmoment ohne P und D Anteil des Leerlaufreglers, ohne Antiruckelfunktion und ohne Getriebeeingriff
(nicht PL71-Hybrid)
Sollmoment für Getriebe";
CM_ SG_ 1160 MO6_Ist_Moment "Istmoment ohne P und D Anteil des Leerlaufreglers, ohne Antiruckelfunktion und ohne Getriebeeingriff

Hybrid:
EM-Momente müssen berücksichtigt werden. Soll bei kleiner Dynamik und Abwesenheit langfristiger Eingriffe identisch sein zu innerem Moment oE ";
CM_ SG_ 1160 MO6_Hoeheninfo "Korrekturfaktor Höhe (1 entspricht 1013 mbar; 0,9 entspricht 1000m; 0,8 entspricht 2000m; 1,1 entspricht -1000m)
(Korrekturfaktor linear skaliert: delta Höhe 1000m entsprechen delta Druck 101,3 mbar)";
CM_ SG_ 1160 MO6_GRA_Soll "Die im Motor-SG integrierte GRA gibt hier eine 'gesteuerte' Soll-Beschleunigung aus
FEH = GRA aus
FFH = nicht erlaubt
GRA Sollbeschleunigung";
CM_ SG_ 1160 MO6_MomIntGeEing "Nur für Getriebe mit 'alter' Momentenschnittstelle:
100 % entspricht volle Verfügbarkeit aktuell vorhanden.
0 % entspricht Integral bis Limit gefüllt, erhöhender Eingriff kann aktuell nicht berücksichtigt werden oder erhöhender Eingriff ist in diesem Pr";
CM_ SG_ 1160 MO6_FF_Mux00 "Übertragung von Meßgrößen an das Getriebesteuergerät für Freeze Frame Abspeicherung bei Getriebefehlern (nur NAR)
Calculated Load Value (PID $04)";
CM_ SG_ 1160 MO6_FF_Mux01 "Übertragung von Meßgrößen an das Getriebesteuergerät für Freeze Frame Abspeicherung bei Getriebefehlern (nur NAR)
Absolute Throttle Position (PID $11)";
CM_ SG_ 1160 MO6_FF_Mux02 "Übertragung von Meßgrößen an das Getriebesteuergerät für Freeze Frame Abspeicherung bei Getriebefehlern (nur NAR)
Engine Coolant Temperature (PID $05)";
CM_ SG_ 1160 MO6_FF_Mux03 "Übertragung von Meßgrößen an das Getriebesteuergerät für Freeze Frame Abspeicherung bei Getriebefehlern (nur NAR)
Absolute Load Value (PID $43)";
CM_ SG_ 1160 MO6_FF_Mux04 "Übertragung von Meßgrößen an das Getriebesteuergerät für Freeze Frame Abspeicherung bei Getriebefehlern (nur NAR)
Accelerator Pedal Position D (PID $49)";
CM_ SG_ 1160 MO6_FF_Mux05 "Übertragung von Meßgrößen an das Getriebesteuergerät für Freeze Frame Abspeicherung bei Getriebefehlern (nur NAR)";
CM_ SG_ 1160 MO6_FF_Mux06 "Übertragung von Meßgrößen an das Getriebesteuergerät für Freeze Frame Abspeicherung bei Getriebefehlern (nur NAR)";
CM_ SG_ 1160 MO6_FF_Mux07 "Übertragung von Meßgrößen an das Getriebesteuergerät für Freeze Frame Abspeicherung bei Getriebefehlern (nur NAR)";
CM_ SG_ 1160 MO6_FF_Mux08 "Übertragung von Meßgrößen an das Getriebesteuergerät für Freeze Frame Abspeicherung bei Getriebefehlern (nur NAR)";
CM_ SG_ 1160 MO6_FF_Mux09 "Übertragung von Meßgrößen an das Getriebesteuergerät für Freeze Frame Abspeicherung bei Getriebefehlern (nur NAR)";
CM_ SG_ 1160 MO6_FF_Mux10 "Übertragung von Meßgrößen an das Getriebesteuergerät für Freeze Frame Abspeicherung bei Getriebefehlern (nur NAR)";
CM_ SG_ 1160 MO6_FF_Mux11 "Übertragung von Meßgrößen an das Getriebesteuergerät für Freeze Frame Abspeicherung bei Getriebefehlern (nur NAR)";
CM_ SG_ 1160 MO6_FF_Mux12 "Übertragung von Meßgrößen an das Getriebesteuergerät für Freeze Frame Abspeicherung bei Getriebefehlern (nur NAR)";
CM_ SG_ 1160 MO6_FF_Mux13 "Übertragung von Meßgrößen an das Getriebesteuergerät für Freeze Frame Abspeicherung bei Getriebefehlern (nur NAR)";
CM_ SG_ 1160 MO6_FF_Mux14 "Übertragung von Meßgrößen an das Getriebesteuergerät für Freeze Frame Abspeicherung bei Getriebefehlern (nur NAR)";
CM_ SG_ 1160 MO6_FF_Mux15 "Übertragung von Meßgrößen an das Getriebesteuergerät für Freeze Frame Abspeicherung bei Getriebefehlern (nur NAR)";
CM_ SG_ 1160 MO6_Freigabe_GRA "Sollbeschleunigung bzw. Bremseeingriff in Byte 5 freigegeben (zukünftig Entfall geplant)
GRA-Bremseingriff-Freigabe";
CM_ SG_ 1160 MO6_Schutz_Toel "Bei einer Töl > 150°C wird das Übertemperaturschutzbit dann gesetzt und das Getriebe schaltet vom 4. Gang in den 5. Gang bei Vmax. Bei einer Töl < 125°C wird dieses Bit zurück gesetzt und das Getriebe schaltet dann bei Vmax vom 5. Gang wieder in den 4. Ga";
CM_ SG_ 1160 MO6_Luftpfad_akt "Getriebeeingriff wird zusätzlich zum Zündungspfad auch über den Luftpfad umgesetzt (nur VW D1)
Luftpfad aktiv";
CM_ SG_ 1160 MO6_RegPartikel "Für die Partikelfilterregeneration wird das Getriebe aufgefordert, ein drehzahlintensiveres Schaltprogramm zu aktivieren (Nur EDC16C Audi D3 / Audi C6!) / VW D1/Colorado/ PQ35/46)
(Z. Zt.: Mindestdrehzahl im Getriebe appliziert; Zuk. geplant: Übertragung";
CM_ SG_ 1160 MO6_Zaehler "Botschaftszähler zur Erkennung fehlender und veraltetet Botschaften, Definition im CAN-Lastenheft";
CM_ BO_ 1416 "CAN-Antrieb 20 ms";
CM_ SG_ 1416 MO7_LL_Solldz "Leerlauf-Solldrehzahl wurde angehoben, weil BSG_Last, Byte 2, Bit 0 oder Energiemananager 1, Byte 1, Bit 0 gesetzt war oder eine Klimaanforderung vorlag
Rückmeldung Leerlauf-Solldrehzahl 1 für Lastmanagement";
CM_ SG_ 1416 MO7_Fehler_VBegr "Fehlerbit wird vom Motor-SG gesetzt, wenn dieses nicht in die Geschwindigkeits-begrenzung gehen kann, ein Fehler während der v-Begrenzung auftritt oder v > v(begr.) - v(delta)
Geschwindigkeitsbegrenzung aktivierbar";
CM_ SG_ 1416 MO7_Sta_VBegr "Motor begrenzt aktuell die Geschwindigkeit des Fahrzeugs; Reaktion auf externe oder interne Anforderung
Statusbit Geschwindigkeitsbegrenzung aktiv";
CM_ SG_ 1416 MO7_Fehlereintr "Bei gesetztem Bit ist mindestens ein Kundendienstfehler eingetragen";
CM_ SG_ 1416 MO7_StaOeltemp "n.i.O. steht für Fehlerwert, außerhalb des Meßbereichs (ungenau), nicht verbaut oder noch kein aktueller Wert
Info aus Aufbereitung der TOG-Botschaft (nicht VW D1/Colorado, aber im Touareg GP/ D1 GP)
* Initwert 1 bei nicht verbautem Sensor oder nicht ve";
CM_ SG_ 1416 MO7_Sta_PTC "Rückmeldung für das Lastmanagement, daß die PTC / Glühstifte ausgeschaltet wurden
z. Zt nur beim Diesel gefordert (nur VW)
PTC/Glühstifte ausgeschaltet";
CM_ SG_ 1416 MO7_DFM "Meßwert Tastverhältnis DFM-Signal
(Nicht Audi D3 / C6!) (bei umgesetzter neuer Generatorschnittstelle wird das Signal im Colorado GP, D1GP/BY61x und Phaeton ab MJ07 nicht mehr bedient (abhängig vom Motor-Projekt))
Klemme_DFM";
CM_ SG_ 1416 MO7_Hoeheninfo "Korrekturfaktor Höhe (1 entspricht 1013 mbar; 0,9 entspricht 1000m; 0,8 entspricht 2000m; 1,1 entspricht -1000m)
(Korrekturfaktor linear skaliert: delta Höhe 1000m entsprechen delta Druck 101,3 mbar)";
CM_ SG_ 1416 MO7_Gradient_Dz "Differenz der Motordrehzahlen n(t) - n(t-20msec) aus der CAN-Botschaft 'Motor 1'
Motordrehzahlgradient";
CM_ SG_ 1416 MO7_GradientVorz "Positiv steht für steigende Drehzahl; Negativ für fallende Drehzahl
Vorzeichen Motordrehzahlgradient";
CM_ SG_ 1416 MO7_Ladedruckneu "Zur Anzeige im Kombi (z.Zt. nur Porsche Colorado, PQ35 Bi-Turbo, Audi RS6, TT-R)
Kombi im PQ35-Bi-Turbo und Audi RS6 und TT-R interpretiert die normierten CAN-Werte (0-254) als 0-100% der Anzeigeskala
(Änderung Wertebereich für PQ35/46 mit V5.1.6 und Ne";
CM_ SG_ 1416 MO7_GenLdResp "Dient der Vermeidung der vom Generator erzeugten, mechanischen Lastsprüngen und Leerlaufschwankungen durch trägere Ausregelung. Diese Massnahme darf nur kurzfristig bzw. als Notlauf wirksam sein (nicht VW D1/Colorado und PQ35/46).
Generator_Load_Response";
CM_ SG_ 1416 MO7_PTC_bereit "Bereitschaft dreistufiges PTC !!! (im AU716 und C6 ab 22/08)
Bereitschaft PTC-Heizung
00 kein dreistufiges PTC verbaut
0x 2x 300 W PTC-Stufe soll nicht eingeschaltet werden bzw. ist defekt (Diagnose)
1x 2x 300 W PTC-Stufe soll eingeschaltet werden und";
CM_ SG_ 1416 MO7_Mot_weckfaehig "Anhand dieses Signals lernt das BSG, ob es zukünftig bei bestimmten Ereignissen (Türkontakt, Anforderung Standheizung) über das Gateway das Wecken des Antriebs-CANs initieren soll. (nicht Audi)
Motor weckfähig über CAN";
CM_ SG_ 1416 MO7_Zus_Kuehl "Zur Unterstützung der Motorkühlung fordert Motor von Klima oder Zusatzheizung die Schaltung des Heizwasserkreislauf-Bypasses an (z. Zt. nur im Colorado V10 TDI)
Zusätzliche Kühlung";
CM_ SG_ 1416 MO7_SleepInd "Die Sleep-Bereitschaft wird nach Klemme 15 aus durch Setzen dieses Bits signalisiert
NMHigh-Teilnehmer der PQ35/46 müssen das Signal nach Kl.-15 aus weiterhin bedienen oder dauerhaft auf 1 = 'Sleep bereit' setzen!";
CM_ SG_ 1416 MO7_RueckLLDz "Leerlauf-Solldrehzahl wurde aufgrund einer Lastmanagement-Anforderung (BSG_Last Byte 1, Bit 5 oder Energiemanager 1, Byte 1, Bit 1) auf die zweite Stufe angehoben
(nicht VW D1/Colorado)
Rueckmeldung_Leerlauf-Solldrehzahl 2";
CM_ SG_ 1416 MO7_Lastabwurf "Anforderung eines Lastabwurfs (für Notlauf):
Stufe 0: Keine Reduktion der Generatorspannung
Stufe 1: Generatorspannung = 13,3V
Stufe 2: Generatorspannung = 12,6V
Stufe 3: Generatorspannung = 11,8V
Anmerkung: Stufe 3 nur für äußersten Notfall!
Schalt";
CM_ SG_ 1416 MO7_Gen_ein "Einschalten des Generators nach Motorstart. Einschalten evtl. mit Load-Response.
Anmerkung: Solange der Generator ausgeschaltet ist, bleiben auch die Hochleistungsheizsysteme deaktiviert. Spätestens 5 s nach Motorstart wird der Generator zugeschaltet una";
CM_ SG_ 1416 MO7_Lastabw_Heiz "Lastabwurf der Hochleistungsheizsysteme (z.B. Abschaltung von Frontscheibenheizung, PTC-Heizung und Heckscheibenheizung nach Motorstart und im Notfall).
Anmerkung: Der Lastabwurf der Hochleistungs-heizsysteme wird auch bei reduzierter Generatorspannung d";
CM_ SG_ 1416 MO7_StaGluehk "Einschaltzustand der Gluehkerzenheizung in Prozent (nicht VW D1/Colorado)
Gluehkerzen_Brennraum";
CM_ SG_ 1416 MO7_Oeltemp "realer Meßbereich ca. -40..150 Grad
0 für nicht verbaut
Info aus Aufbereitung der TOG-Botschaft (nicht VW D1/Colorado, aber im Touareg GP/D1 GP)
Öltemperatur";
CM_ BO_ 1162 "CAN-Antrieb";
CM_ SG_ 1162 MO8_Checksumme "Prüfsumme mit Endwert 0x0, Definition im CAN Lastenheft (HS-CAN V4.2a, LS-CAN V1.42)";
CM_ SG_ 1162 MO8_AnzeigeDZ "Optimierte Anzeigedrehzahl";
CM_ SG_ 1162 WBA_Effizienzmodus "Bei Handschaltern wird  das Fahrprogramm Effizienz signalisiert. ";
CM_ SG_ 1162 MO8_SGT_Soundakt "Ansteuerung des Stellgliedtest Soundaktuator (AU716, TTNF)";
CM_ SG_ 1162 MO8_Spoiler_ausf "Spoiler ausfahren";
CM_ SG_ 1162 MO8_Sportschalter "nur AU714
Sportschalter";
CM_ SG_ 1162 MO8_LampeDZBegr "Im Audi RS/4 und AU714
Lampe Drehzahlbegrenzung";
CM_ SG_ 1162 MO8_Enable_Oeldr_Motor "Schaltet die interne Öldruckauswertung im Kombiinstrument ab und aktiviert die Auswertung des Bits 'Oeldr_Warn_Motor'";
CM_ SG_ 1162 MO8_Oeldr_Warn_Motor "Löst im Kombiinstrument die rote Prio1-Öldruckwarnung (inkl. 3xBeep) aus; die Warnauslösung erfolgt nur bei gleichzeitig gesetztem 'Enable_Oeldr_Motor'";
CM_ SG_ 1162 MO8_Avus_Motorschutz "Warntexte zum Kombi für den Fall des Avus-Notlauf. Priowarnung, kann parallel mit anderen Warnungen im Mitteldisplay angezeigt werden.";
CM_ SG_ 1162 MO8_GRA_v_Wunsch "Wunschgeschwindigkeit GRA vom Motor an Kombi zur Anzeige im Mitteldisplay (nicht AU714)";
CM_ SG_ 1162 MO_Schaltempf_verfbar "Info, ob Schaltempfehlung im Fzg. in mMotor_8 verfügbar. Statischer Wert, ändert sich für ein Fzg. nicht!";
CM_ SG_ 1162 MO8_Nachlauf_ZWP "Die Zusatzwasserpumpe soll bei Kl. 15 aus (Nachlauf) die erhöhte Temperatur im Motorraum bei Bedarf noch abführen können. (nur Audi)";
CM_ SG_ 1162 MO_Istgang "Aktueller Gang für Anzeige Hochschaltempfehlung (gültig, wenn MO_Schaltempf_verfbar = 1).

Anzeige im Kombi:
Sollgang == Istgang         ==> Anzeige Istgang
Sollgang !=   Istgang         ==> Schaltempfehlung
Sollgang == Istgang == 0 ==> keine Anzeige";
CM_ SG_ 1162 MO_Sollgang "Motor sendet den Sollgang in den der Fahrer schalten soll. Wird im Kombi als Hochschaltempfehlung hervorgehoben (gültig, wenn MO_Schaltempf_verfbar = 1).

Anzeige im Kombi:
Sollgang == Istgang         ==> Anzeige Istgang
Sollgang !=   Istgang         ";
CM_ SG_ 1162 MO8_Zaehler "Definition nach CAN-Lastenheft";
CM_ SG_ 644 MOB_Checksum "Prüfsumme mit Endwert 0x0, Definition im CAN Lastenheft (HS-CAN V4.2a, LS-CAN V1.42)";
CM_ SG_ 644 MOB_Zaehler "Freilaufender Botschaftszähler gem. CAN-Lastenheft";
CM_ SG_ 644 MOB_Standby "Veranlaßt Bremsbooster / die Bremse den Leerweg zu überfahren, bevor Bremsdruck erzeugt wird.";
CM_ SG_ 644 MOB_Anhaltewunsch "Erweiterung für ACC Follow to Stop
Anhaltewunsch";
CM_ SG_ 644 MOB_Freigabe "Anforderung Bremsstellgröße (mMotor_Bremse: Byte 4,3) bzw. Summenradbremsmoment (mMotor_Bremse: Byte 5,4) wird freigegeben (Vorhalt)
Bremslicht wird angesteuert
Freigabe Bremsanforderung";
CM_ SG_ 644 MOB_Bremsstgr "Byte 3 LSB, Byte 4(2..0) MSB
 Angeforderte (normierte) radbremsmomenten-proportionale Stellgröße (im PQ46)
Anforderung Bremsstellgröße";
CM_ SG_ 644 MOB_Bremsmom "13 Bit, in Byte 4 stehen die niederwertigsten 5 Bit, in Byte 5 die höherwertigen Bits
Alternativ zu Bremsdruckanforderung. Ältere Systeme hören nur auf Bremsdruck, neue Systeme auf Radbremsmoment (im Touareg GP, D1GP, Golf GP, T5GP)
Anforderung Summenra";
CM_ SG_ 1800 MC1_Anz_Betrieb "Kombiinstrument zeigt die Gasbetriebsart an
Motor steuert die Anzeige mit diesem Bit
Blinken der Anzeige wird durch Setzen und Löschen des Bits nachgebildet (z.B. wenn der Fahrer auf leeren Gastank schalten will)
Betriebsart für Anzeige";
CM_ SG_ 1800 MC1_Schalter "In diesem Bit wird die Schalterstellung ausgegeben (nicht für die Anzeige im Kombi !)
Anmerkung: die aktuelle Betriebsart kann von der eingestellten abweichen
Betriebsart Schalterstellung";
CM_ SG_ 1800 MC1_akt_Betrieb "Motor fährt mit Benzin oder Gas
Aktuelle Betriebsart";
CM_ SG_ 1800 MC1_CNG_LPG "0  Es gilt MC1_Verbrauch
1  Es gilt MC1_Verbrauch_LPG und MO_LPG_Tankstopp";
CM_ SG_ 1800 MO_LPG_Tankstopp "Der im LPG-SG integrierte Tankalgorithmus hat einen Tankstopp (LPG-Tank) erkannt.
";
CM_ SG_ 1800 MO_Erdgasqualitaet "Erdgas-Qualität abgestuft in 70%, 80%, 90% und 100% (bei CNG bezogen auf 100% Methan).
Berechnung erfolgt einmalig nach jeder Betankungserkennung.";
CM_ SG_ 1800 MC1_Fuellungsgrad "Gefilterter temperaturkompensierter Gasdruckwert als Prozentwert vom Maximalwert wird im Kombi als Zeiger dargestellt
Füllungsgrad Erdgas";
CM_ SG_ 1800 MC1_Verbrauch "Motor-Steuergerät interner Verbrauchszähler, der vom Kombi zyklisch ausgelesen wird, um die Gasmenge zur Verbrauchsberechnung aufzusummieren; aus diesem Zählerstand werden Momentan- und Durchschnitts-verbrauch berechnet; das Überlauf-Bit (Byte 4, Bit 7) i";
CM_ SG_ 1800 MC1_Verbrauch_LPG "Motor-Steuergerät interner Verbrauchszähler, der vom Kombi zyklisch ausgelesen wird, um die Gasmenge zur Verbrauchsberechnung aufzusummieren; aus diesem Zählerstand werden Momentan- und Durchschnitts-verbrauch berechnet; das Überlauf-Bit (Byte 4, Bit 7) i";
CM_ SG_ 1800 MC1_Ueb_Verbr "Der Motor-Steuergerät interne Verbrauchszähler ist mindestens einmal übergelaufen. Dieses Bit wird genutzt, um erkennen zu können, das das Motorsteuergerät aus dem Reset-Zustand hochläuft
Erdgasverbrauch-Überlauf";
CM_ SG_ 1800 MO_AnzeigeGasbetrieb "Anzeige des Betriebszustands bei Umschaltung zwischen Gas- und Benzinbetrieb";
CM_ SG_ 1408 MFN_Zaehler "überlaufender Botschaftszähler, die Bits 0 und 1 werden zum Multiplexen der Bytes 2..8 benutzt
(Hinweis: Im dbc-File nur wg. Nutzung als Multiplexor auf zwei Signale aufgetrennt, Bit 3..0 ist aber als ein Signal (Zähler) umzusetzen)";
CM_ SG_ 1408 MFN_Zaehler_ "überlaufender Botschaftszähler, die Bits 0 und 1 werden zum Multiplexen der Bytes 2..8 benutzt
(Hinweis: Im dbc-File nur wg. Nutzung als Multiplexor auf zwei Signale aufgetrennt, Bit 3..0 ist aber als ein Signal (Zähler) umzusetzen)";
CM_ SG_ 1408 MFN_Drive_Cycle "Driving Cycle";
CM_ SG_ 1408 MFN_Warmup_Cycle "Mit dem WarmUp Cycle wird der Verlernzähler im Gateway inkrementiert";
CM_ SG_ 1408 MFN_NormedTrip "gesetzlich definierte 'Normed Condition' erfüllt; 'General Denominator' darf erhöht werden";
CM_ SG_ 1408 MFN_Verbrenn_Typ "Unterscheidung otto oder dieselspezifische Größen
Verbrennungsart";
CM_ SG_ 1408 MFN_Russindex "Byte 1 Bit 0 = 0, d.h. bei Zählerstand 0,2,4,6,8,10,12,14 Wiederholrate 2 sec
Ist beim Dieselmotor ein von Motordrehzahl und der Einspritzmenge abhängiger Rußwert, beim Ottomotor ist der Wert 0
0000H Motor aus
FFFFH .. unplausibler/fehlerhafter Wert
R";
CM_ SG_ 1408 MFN_Verschl "Byte 1 Bit 0 = 1, d.h. bei Zählerstand 1,3,5,7,9,11,13,15 Wiederholrate 2 sec
Ist beim Dieselmotor ein von der Motordrehzahl und der Öltemperatur abhängiger Verschleißwert, beim Ottomotor ein Verbrauchsäquivalent , das von der Öltemperatur, dem Füllstand";
CM_ SG_ 1408 MFN_Russindex_ "Byte 1 Bit 0 = 0, d.h. bei Zählerstand 0,2,4,6,8,10,12,14 Wiederholrate 2 sec
Ist beim Dieselmotor ein von Motordrehzahl und der Einspritzmenge abhängiger Rußwert, beim Ottomotor ist der Wert 0
0000H Motor aus
FFFFH .. unplausibler/fehlerhafter Wert
R";
CM_ SG_ 1408 MFN_Verschl_ "Byte 1 Bit 0 = 1, d.h. bei Zählerstand 1,3,5,7,9,11,13,15 Wiederholrate 2 sec
Ist beim Dieselmotor ein von der Motordrehzahl und der Öltemperatur abhängiger Verschleißwert, beim Ottomotor ein Verbrauchsäquivalent , das von der Öltemperatur, dem Füllstand";
CM_ SG_ 1408 MFN_Drz_max_Mo "Byte 1 Bit 0 = 0, d.h. bei Zählerstand 0,2,4,6,8,10,12,14 Wiederholrate 2 sec
Drehzahl für maximales Moment";
CM_ SG_ 1408 MFN_KurzzeitMW "Byte 1 Bit 0 = 1 und Bit 1 = 0, d.h. bei Zählerstand 1,5,9,13 Wiederholrate 4 sec
gemittelte Ölstandsdifferenz (Differenz aus aktuellen Füllstandswerte und kompensierter Ölniveauschwelle) bezogen auf Ölwarnschwelle
Kurzzeitmittelwert";
CM_ SG_ 1408 MFN_Drz_max_Mo_ "Byte 1 Bit 0 = 0, d.h. bei Zählerstand 0,2,4,6,8,10,12,14 Wiederholrate 2 sec
Drehzahl für maximales Moment";
CM_ SG_ 1408 MFN_Interv_Wmin "Byte 1 Bit 0 = 1 und Bit 1 = 1, d.h. bei Zählerstand 3,7,11,15 Wiederholrate 4 sec
Minimale Kilometeranzahl bis zum Service";
CM_ SG_ 1408 MFN_Fuell_Erk "Überfüllungserkennung aktiviert nur für WIV 3.1 im Audi C6";
CM_ SG_ 1408 MFN_max_Moment "Byte 1 Bit 0 = 0, d.h. bei Zählerstand 0,2,4,6,8,10,12,14 Wiederholrate 2 sec
Maximales Drehmoment";
CM_ SG_ 1408 MFN_Oelstand "Byte 1 Bit 0 = 1 und Bit 1 = 0, d.h. bei Zählerstand 1,5,9,13 Wiederholrate 4 sec
Anzahl der in die gemittelte Ölstandsdifferenz eingeflossenen Differenzen
Ölstandszähler";
CM_ SG_ 1408 MFN_max_Moment_ "Byte 1 Bit 0 = 0, d.h. bei Zählerstand 0,2,4,6,8,10,12,14 Wiederholrate 2 sec
Maximales Drehmoment";
CM_ SG_ 1408 MFN_Interv_Wmax "Byte 1 Bit 0 = 1 und Bit 1 = 1, d.h. bei Zählerstand 3,7,11,15 Wiederholrate 4 sec
Maximale Kilometeranzahl bis zum Service";
CM_ SG_ 1408 MFN_Oelwarnung "Byte 1 Bit 0 = 1 und Bit 1 = 0, d.h. bei Zählerstand 1,5,9,13 Wiederholrate 4 sec
aktive Warnmöglichkeit vom Motor (Vorhalt)";
CM_ SG_ 1408 MFN_Sensorwarn "Byte 1 Bit 0 = 1 und Bit 1 = 0, d.h. bei Zählerstand 1,5,9,13 Wiederholrate 4 sec
Sensorwarnung bei unplausiblen oder fehlendem Signal";
CM_ SG_ 1408 MFN_MaxOelst "Byte 1 Bit 0 = 1 und Bit 1 = 1, d.h. bei Zählerstand 3,7,11,15 Wiederholrate 4 sec
Schwellwert für Maximum-Ölstand (entspricht der oberen Markierung am Peilstab) (nur für WIV 3.1 im Audi C6)";
CM_ SG_ 1408 MFN_Motorleistung "Byte 1 Bit 0 = 0, d.h. bei Zählerstand 0,2,4,6,8,10,12,14 Wiederholrate 2 sec
maximale Motorleistung (Byte 6 + MSB in Byte 7 Bit 0)";
CM_ SG_ 1408 MFN_AnzMitOel "Byte 1 Bit 0 = 1 und Bit 1 = 0, d.h. bei Zählerstand 1,5,9,13 Wiederholrate 4 sec
Geforderte Anzahl Ölstandsdifferenzen für die Auswertung des schnellen Ölfüllstandsmittelwertes (nur für WIV 3.1 im Audi C6)";
CM_ SG_ 1408 MFN_Motorleistung_ "Byte 1 Bit 0 = 0, d.h. bei Zählerstand 0,2,4,6,8,10,12,14 Wiederholrate 2 sec
maximale Motorleistung (Byte 6 + MSB in Byte 7 Bit 0)";
CM_ SG_ 1408 MFN_Max_Offset "Byte 1 Bit 0 = 1 und Bit 1 = 0, d.h. bei Zählerstand 1,5,9,13 Wiederholrate 4 sec
Offset auf den Maximum-Ölstand, ab dem Überfüllung erkannt werden soll (nur für WIV 3.1 im Audi C6)";
CM_ SG_ 1408 MFN_Anz_Mittel "Byte 1 Bit 0 = 1 und Bit 1 = 1, d.h. bei Zählerstand 3,7,11,15 Wiederholrate 4 sec
Minimale geforderte Anzahl der Ölstandsdifferenzen für Auswertung
Anzahl Mittelung / Anzahl Mittelung genauer Ölstandsmittelwert";
CM_ SG_ 1408 MFN_Fuell_Hyst "Byte 1 Bit 0 = 1 und Bit 1 = 0, d.h. bei Zählerstand 1,5,9,13 Wiederholrate 4 sec
Nach erfolgter Überfüllungserkennung muß der nachfolgende Ölstand-Kurzzeitmittelwert diese Hysterese unterschreiten, damit das Überfüllungsbit zurückgesetzt wird (nur für W";
CM_ SG_ 1408 MFN_Interv_tmin "Byte 1 Bit 0 = 1 und Bit 1 = 1, d.h. bei Zählerstand 3,7,11,15 Wiederholrate 4 sec
Minimales Zeitintervall bis zum Service";
CM_ SG_ 1408 MFN_Ventile "Byte 1 Bit 0 = 0, d.h. bei Zählerstand 0,2,4,6,8,10,12,14 Wiederholrate 2 sec
Anzahl der Ventile pro Zylinder";
CM_ SG_ 1408 MFN_Ventile_ "Byte 1 Bit 0 = 0, d.h. bei Zählerstand 0,2,4,6,8,10,12,14 Wiederholrate 2 sec
Anzahl der Ventile pro Zylinder";
CM_ SG_ 1408 MFN_Zylinder "Byte 1 Bit 0 = 0, d.h. bei Zählerstand 0,2,4,6,8,10,12,14 Wiederholrate 2 sec
Anzahl der Zylinder (1xWert bis 12 Zyl.,13 = 15 Zyl., 14 = 16 Zyl., 15 = 18 Zyl.)";
CM_ SG_ 1408 MFN_Offset_Nachf "Byte 1 Bit 0 = 1 und Bit 1 = 0, d.h. bei Zählerstand 1,5,9,13 Wiederholrate 4 sec
Offset für Nachfüllerkennung
Ölwarnschwellen-Offset";
CM_ SG_ 1408 MFN_Zylinder_ "Byte 1 Bit 0 = 0, d.h. bei Zählerstand 0,2,4,6,8,10,12,14 Wiederholrate 2 sec
Anzahl der Zylinder (1xWert bis 12 Zyl.,13 = 15 Zyl., 14 = 16 Zyl., 15 = 18 Zyl.)";
CM_ SG_ 1408 MFN_Interv_tmax "Byte 1 Bit 0 = 1 und Bit 1 = 1, d.h. bei Zählerstand 3,7,11,15 Wiederholrate 4 sec
Maximales Zeitintervall bis zum Service";
CM_ SG_ 1408 MFN_Hubraum "Byte 1 Bit 0 = 0, d.h. bei Zählerstand 0,2,4,6,8,10,12,14 Wiederholrate 2 sec
Hubraum";
CM_ SG_ 1408 MFN_Hubraum_ "Byte 1 Bit 0 = 0, d.h. bei Zählerstand 0,2,4,6,8,10,12,14 Wiederholrate 2 sec
Hubraum";
CM_ SG_ 1408 MFN_Tol_Oelwarn "Byte 1 Bit 0 = 1 und Bit 1 = 0, d.h. bei Zählerstand 1,5,9,13 Wiederholrate 4 sec
Toleranz für Ölwarnschwelle bei geringer Restlaufstrecke";
CM_ SG_ 1408 MFN_Str_Mittel "Byte 1 Bit 0 = 1 und Bit 1 = 1, d.h. bei Zählerstand 3,7,11,15 Wiederholrate 4 sec
Minimal geforderte Fahrstrecke für Ölstandsauswertung";
CM_ SG_ 1408 MFN_Ansaugsys "Byte 1 Bit 0 = 0, d.h. bei Zählerstand 0,2,4,6,8,10,12,14 Wiederholrate 2 sec
Ansaugsystem";
CM_ SG_ 1408 MFN_Ansaugsys_ "Byte 1 Bit 0 = 0, d.h. bei Zählerstand 0,2,4,6,8,10,12,14 Wiederholrate 2 sec
Ansaugsystem";
CM_ SG_ 1154 MH1_VM_Mom_oE "Verbrenner-Fahrmoment abzüglich Verbrenner-Verlustmoment. Vorzeichenbehaftet.
Für Benutzung in Getriebe-Schaltstrategie
Verbrenner-Moment ohne Eingriff";
CM_ SG_ 1154 MH1_IstStatusK0 "Status 'offen' muss eine voll geöffnete Kupplung sicherstellen.
Ist-Status K0";
CM_ SG_ 1154 MH1_Startmodus_PQ35 "Hybridsteuerung (MSG) zeigt an, auf welche Weise gestartet werden soll (nur PQ35 Hybrid)
Startmodus Impuls / Direkt PQ35";
CM_ SG_ 1154 MH1_VM_aktiv "0 = VMotor wird nicht aktiv gehalten (nVM < n_min und keine LL-Regelung aktiv)
1 = VMotor aktiv (ab der ersten Einspritzung; gilt auch für Schubbetrieb, wenn VMotor spätestens durch LL-Regelung befeuert würde)
Verwendung zur Bestimmung des Ist-Zustandes";
CM_ SG_ 1154 MH1_Zielzustand_Hybrid "Ziel - Hybrid-Betriebszustände";
CM_ SG_ 1154 MH1_Schaltverh "Schaltungen werden an den DZ-Grenzen (Nullgas-Schaltdrehzahl und Kickdown-Schaltdrehzahl) ausgeführt
Schaltverhinderung";
CM_ SG_ 1154 MH1_VerlParam_Msum "Wenn Byte 7, Bit 4 = 1 (GRA/ACC aktiv), erhalten in Abhängigkeit von den Bits 1, 0 (Byte 3) die Bits 7..2 (Byte 3) folgende Bedeutung:
Bit 1,0 =00: max. umsetzbares langfr. Rekup-Moment
Bit 1,0 =01: Knickdrehzahl d. langfr. Rekup-Kurve
Bit 1,0 =10: max";
CM_ SG_ 1154 MH1_MomVerlauf_EM "Wenn Byte 7, Bit 4 = 1 (GRA/ACC aktiv):
Momentenverlaufsinformation EM
Umrechnung:
M = 315/63 * i Nm (i = unsigned int der 6 Bits), wenn Byte 3, Bit 1,0 = 0 oder 2
N = 3150/63 * i min-1 (i = unsigned int der 6 Bits) , wenn Byte 3, Bit 1,0 = 1 oder 3";
CM_ SG_ 1154 MH1_E_Faktor "Wenn Byte 7, Bit 4 = 0 (GRA/ACC nicht aktiv): E-Faktor.
Signed Nibble (Zweierkomplement), verwendet vom GSG zur Interpolation zwischen VM-Kennfeld und dem Rekuperations-Grenzkennfeld (negative Werte des E-Faktors) bzw. dem Boost-Grenzkennfeld (positive W";
CM_ SG_ 1154 MH1_Drehzahl_VM "für OBD freeze frame
Drehzahl Verbrennungsmotor";
CM_ SG_ 1154 MH1_max_ind_VM_Mom "inneres maximal mögliches VM-Moment bei einer Drehzahl (z. B. Rauchbegrenzung oder Fehlerfall).
Verwendet von GSG bei GRA/ACC-Betrieb
Max. mögliches indiziertes VM-Moment";
CM_ SG_ 1154 MH1_Startmodus_PL71 "Hybridsteuerung (MSG) zeigt an, auf welche Weise gestartet werden soll. (nur PL71 Hybrid)
Startmodus PL71";
CM_ SG_ 1154 MH1_LowSpeedModus "MSG legt fest:
0 = klassisches Ausrollen/Anfahren mit N_mot >= N_Leerlauf_VM
1 = elektr. Ausrollen/Anfahren mit geschl. Triebstrang mit N_mot < N_Leerlauf_VM
Low-Speed-Modus";
CM_ SG_ 1154 MH1_ACCGRA_aktiv "Zeigt an, ob GRA/ACC aktiv ist.
Wird zusammen mit Byte 3 / Bits 1..0 als Selektor für die Bedeutung der Bits 7..2 (Byte 3) benutzt";
CM_ SG_ 1154 MH1_QB_Bremspedalwert "Qualifizierungsbit nach CAN-LH";
CM_ SG_ 1154 MH1_Bremspedalwert "Bremspedalwegsensor vom Motor eingelesen";
CM_ SG_ 1823 MSI_KD_Fehler "Info für Diagnose; bei gesetztem Bit befindet sich mindestens ein Kundendienstfehler im Fehlerspeicher des Motorslave";
CM_ SG_ 1428 NI2_Checksum "Prüfsumme mit Endwert 0x0, Definition im CAN Lastenheft (HS-CAN V4.2a, LS-CAN V1.42)";
CM_ SG_ 1428 NI2_Zaehler "Freilaufender Botschaftszähler";
CM_ SG_ 1428 NI2_Hoehenflag "legt fest, wie die Höhenwerte in Byte 3-6 interpretiert werden müssen";
CM_ SG_ 1428 NI2_Hoehe_VL "aktueller Höhensensorwert vorne links
0x7F entspricht NN
im Audi C6, VW D1 ungefiltertes Signal";
CM_ SG_ 1428 NI2_Hoehe_VL_Roh "aktueller Höhensensorwert vorne links, ungefiltert, Rohwert";
CM_ SG_ 1428 NI2_Hoehe_VR "aktueller Höhensensorwert vorne rechts
0x7F entspricht NN
im Audi C6, VW D1 ungefiltertes Signal";
CM_ SG_ 1428 NI2_Hoehe_VR_Roh "aktueller Höhensensorwert vorne rechts, ungefiltert, Rohwert";
CM_ SG_ 1428 NI2_Hoehe_HL "aktueller Höhensensorwert hinten links
0x7F entspricht NN
im Audi C6, VW D1 ungefiltertes Signal";
CM_ SG_ 1428 NI2_Hoehe_HL_Roh "aktueller Höhensensorwert hinten links, ungefiltert, Rohwert";
CM_ SG_ 1428 NI2_Hoehe_HR "aktueller Höhensensorwert hinten rechts
0x7F entspricht NN
im Audi C6, VW D1 ungefiltertes Signal";
CM_ SG_ 1428 NI2_Hoehe_HR_Roh "aktueller Höhensensorwert hinten rechts, ungefiltert, Rohwert";
CM_ SG_ 1428 NI2_AufbBeschl_VL "Aufbaubeschleunigung VL
(für aktive Wankstabilisierung)";
CM_ SG_ 1428 NI2_AufbBeschl_VR "Aufbaubeschleunigung VR
(für aktive Wankstabilisierung)";
CM_ SG_ 1349 PA3_System_codierung "0 = 4 Kanal PDC
1 = 8 Kanal PDC

Bei VW:
0 = hinten
1 = Vorn und Hinten

8/4-Kanal-Anlage";
CM_ SG_ 1349 PA3_Anlage_defekt "1 = PDC wurde aufgrund eines Defektes deaktiviert
Anlage defekt";
CM_ SG_ 1349 PA3_Taster_aktiviert "1 = Anlage wurde manuell ueber Einschalttaster aktiviert
Aktivierung durch Taster (Nur 8-Kanal)";
CM_ SG_ 1349 PA3_Rueckwaertsgang_aktiv "1 = Anlage wurde durch Einlegen des Rueckwaertsgangs aktiviert";
CM_ SG_ 1349 PA3_Geschwindigkeit_aus "1 = Durch Erreichen von vMax PDC wurde die PDC abgeschaltet";
CM_ SG_ 1349 PA3_Tongeber_v_defekt "1 = Tongeber Vorne ist defekt";
CM_ SG_ 1349 PA3_Tongeber_h_defekt "1 = Tongeber Hinten ist defekt";
CM_ SG_ 1349 PA3_Audioabsenkung_Anforderung "1= Anforderung an das Audiosystem fuer Absenkung der Lautstaerke";
CM_ SG_ 1349 PA3_Eis_aus "1 = Wegen erkanntem Eis auf den Sensoren wurde die PDC abgeschaltet";
CM_ SG_ 1349 PA3_Schlechtweg_aus "1 = Aufgrund von signalisierten Schlechtweginformationen wurde die PDC abgeschaltet";
CM_ SG_ 1349 PA3_KD_Fehler "1 = mindestens ein Fehler ist im Kundendienstfehlerspeicher eingetragen";
CM_ SG_ 1349 PA3_Sensor_hll_defekt "0 = Sensor OK / 1 = Sensor defekt
Sensor hinten links links defekt";
CM_ SG_ 1349 PA3_Sensor_hlm_defekt "0 = Sensor OK / 1 = Sensor defekt
Sensor hinten links mitte defekt";
CM_ SG_ 1349 PA3_Sensor_hrm_defekt "0 = Sensor OK / 1 = Sensor defekt
Sensor hinten rechts mitte defekt";
CM_ SG_ 1349 PA3_Sensor_hrr_defekt "0 = Sensor OK / 1 = Sensor defekt
Sensor hinten rechts rechts defekt";
CM_ SG_ 1349 PA3_Sensor_vll_defekt "0 = Sensor OK / 1 = Sensor defekt
Sensor vorn links links defekt";
CM_ SG_ 1349 PA3_Sensor_vlm_defekt "0 = Sensor OK / 1 = Sensor defekt
Sensor vorn links mitte defekt";
CM_ SG_ 1349 PA3_Sensor_vrm_defekt "0 = Sensor OK / 1 = Sensor defekt
Sensor vorn rechts mitte defekt";
CM_ SG_ 1349 PA3_Sensor_vrr_defekt "0 = Sensor OK / 1 = Sensor defekt
Sensor vorn rechts rechts defekt";
CM_ SG_ 1349 PA3_Bereit "1 = PDC ist Betriebsbereit und kann aktiviert werden";
CM_ SG_ 1349 PA3_Bereich_vo "0 = Initwert (Ausserhalb Gefahrenbereich)
1 = Vorwarnbereich nur NFZ
2 = Hauptwarnbereich
3 = Kollisionsbereich
Bereichserkennung vorn";
CM_ SG_ 1349 PA3_Bereich_hi "0 = Initwert (Ausserhalb Gefahrenbereich)
1 = Vorwarnbereich nur NFZ
2 = Hauptwarnbereich
3 = Kollisionsbereich
Bereichserkennung hinten";
CM_ SG_ 1349 PA3_Akust_aus "1 = Tonausgabe der ParkDistanceControll manuell abgeschaltet
Akustische Ausgabe der PDC abschalten";
CM_ SG_ 1349 PA3_Aufbau_erk "Aufbauten erkannt";
CM_ SG_ 1355 PA5_VL_Abstand "FFh = kein Hindernis im Erfassungsbereich
Abstand vorne links";
CM_ SG_ 1355 PA5_VR_Abstand "FFh = kein Hindernis im Erfassungsbereich
Abstand vorne rechts";
CM_ SG_ 1355 PA5_HL_Abstand "FFh = kein Hindernis im Erfassungsbereich
Abstand hinten links";
CM_ SG_ 1355 PA5_HR_Abstand "FFh = kein Hindernis im Erfassungsbereich
Abstand hinten rechts";
CM_ SG_ 1355 PA5_VML_Abstand "FFh = kein Hindernis im Erfassungsbereich
Abstand vorne mitte links";
CM_ SG_ 1355 PA5_VMR_Abstand "FFh = kein Hindernis im Erfassungsbereich
Abstand vorne mitte rechts";
CM_ SG_ 1355 PA5_HML_Abstand "FFh = kein Hindernis im Erfassungsbereich
Abstand hinten mitte links";
CM_ SG_ 1355 PA5_HMR_Abstand "FFh = kein Hindernis im Erfassungsbereich
Abstand hinten mitte rechts";
CM_ BO_ 980 "DLC 8 für PLA 2.0
alter DLC 4 (bis PLA 1.5)";
CM_ SG_ 980 PL1_Checksumme "Prüfsumme mit Endwert 0x0, Definition im CAN Lastenheft (HS-CAN V4.2a, LS-CAN V1.42)
Achtung! Prüfsumme wird nur über Bytes 2-4 gebildet!";
CM_ SG_ 980 PL1_Zaehler "Überlaufender Botschaftszähler, zur Lebenderkennung";
CM_ SG_ 980 PL1_Stat_PLA_EPS "16 Statuswerte (siehe LH PLA)
Status PLA EPS";
CM_ SG_ 980 PL1_LW_Soll "positiver Lenkradwinkel: nach links; negativer Lenkradwinkel: nach rechts
Solllenkwinkel";
CM_ SG_ 980 PL1_LW_Soll_Sign "Vorzeichen Solllenkwinkel";
CM_ SG_ 980 PL1_Stat_PLA_ESP "Zustand der Statusmaschine des PLA für die korrespondierende Statusmaschine in der Bremse.";
CM_ SG_ 980 PL1_Bremsmoment "Anforderung eines Summenradbremsmomentes";
CM_ BO_ 1494 "DLC 5 für PLA 2.0
alter DLC 2 (bis PLA 1.5)";
CM_ SG_ 1494 PLS_Anf_Anz "Anforderung der Anzeige entsprechender Symbolik gem. HMI-Spezifikation im Kombiinstrument in Abhängigkeit des Signals 'Parklücke links/rechts', nachdem die PLA-Funktion über Tastendruck aktiviert wurde.
Alle weiteren Signale des Bytes 1 werden nur zur An";
CM_ SG_ 1494 PLS_Akustik1 "Ausgabe bei Funktionsdeaktivierung oder Systemstörung";
CM_ SG_ 1494 PLS_PL_Exist "Anzeige entsprechender Symbolik gem. HMI-Spezifikation im Kombiinstrument";
CM_ SG_ 1494 PLS_Akustik2 "Nur Audi: Das Signal dient der akustischen Signalisierung von PLA-Fehlerinformationen";
CM_ SG_ 1494 PLS_Mehrzg_Aktiv "Anzeige der Bedienbildschirme 'Mehrzügiges Einparken'
Mehrzügiges Einparken aktiv";
CM_ SG_ 1494 PLS_Pos_OK "Anzeige der Parklückeninformationen gemäß HMI-Spezifikation.
Position Egofahrzeug";
CM_ SG_ 1494 PLS_PL_Seite "Anzeige der Parklückeninformationen gemäß HMI-Spezifikation.
Parklücke links/rechts";
CM_ SG_ 1494 PLS_Lenk_Aktiv_Hinweis "Anzeige des Symbols, das für Aktiv-Lenkung verwendet wird. Das Signal steuert den Anzeigebildschirm für den Hinweis und liegt nicht während des gesammten aktiven automatischen Lenkeigriffs an.";
CM_ SG_ 1494 PLS_Meldungen "Anzeige gemäß HMI-Spezifikation
Meldungen PLA. Textmeldung ist abhängig vom Text-Multiplexer-Bit.";
CM_ SG_ 1494 PLS_Fahrtrichtg_Mehrzg "In Kombination mit Bit 'Mehrzügiges Einparken aktiv' und Bit 'Parklücke links/rechts'
Auswahl des Bildschirms
Fahrtrichtung mehrzügig";
CM_ SG_ 1494 PLS_Text_Multiplexer "Dient als Multiplexer-Bit für zusätzliche Textmeldungen gemäß HMI-Spezifikation (PLS_Meldungen).

Anmerkung: Jeder Anzeigewunsch eines Piktogramms oder einer Meldung ist mit diesem Bit verknüpft. Bei Wert gleich 0 ist keine Anzeige einer Textmeldung mög";
CM_ SG_ 1494 PLS_Schwellpfeil_rel "Anzeige eines Schwellpfeils während Vorwärts- oder Rückwärtsfahrt in einer Parklücke, der den relativen Abstand in gewünschter Richtung bis zum tatsächlichen Wendepunkt anzeigt. Der Pfeil läuft bis zur Aufforderung zum Fahrtrichtungswechsel leer.";
CM_ SG_ 1494 PLS_Anf_Anz_Schwellpfeil "Schalter, mit dem die Anzeige eines Schwellpfeiles ein- bzw. ausgeschaltet wird.";
CM_ SG_ 1494 PLS_Laengs_Querluecke "Anzeige gemäß Auswahl der Parkfunktion für Längs- oder Querparklücke.";
CM_ SG_ 1494 PLS_Standby "Anzeige des Symbols, das für Standby-Anzeige verwendet wird. Standby-Zustand zeigt an, dass die Fzg.-Geschwindigkeit zu hoch zum Vermessen von Parklücken ist, das System sich bei Unterschreiten einer Geschwindigkeitsschwelle wieder selbständig zur Anzeige";
CM_ SG_ 1494 PLS_Bremssymbol "Dient der Anzeige zur Aufforderung, das Bremspedal getreten zu halten, solange im Stillstand die Räder eingelenkt werden.";
CM_ SG_ 1494 PLS_Kurze_Luecke "Schalter, mit dem eine kurze Lücke erkannt wird, damit die Anzeige eines Schwellpfeiles ein- bzw. ausgeschaltet wird.";
CM_ SG_ 1494 PLS_Schwellpfeil_abs "Anzeige eines Schwellpfeils während Vorwärts- oder Rückwärtsfahrt in einer Parklücke, der den absoluten Abstand in gewünschter Richtung bis zum tatsächlichen Wendepunkt anzeigt. (Pfeil läuft leer).";
CM_ SG_ 1494 PLS_Akustik "Dient der akustischen Signalisierung von PLA-Funktionsdeaktivierungen oder Funktionsstörungen";
CM_ SG_ 1494 PLS_Ausparken_Aktiv "Vorhalt für mögliche Unterscheidungen in der Anzeige. Kennzeichnet einen aktiven Ausparkvorgang und dient der Anzeige geeigneter Informationen im Kombiinstrument, die sich von der Anzeige währende des Einparkvorganges unterscheiden.";
CM_ SG_ 1494 PLS_Bremsleuchte "Bei einer durch PLA initiierten Bremsung des Fahrzeugs muss Bremsleuchte angesteuert werden. Dieses Signal ist der Befehl, die Bremsleuchte einzuschalten, an dasjenige Steuergerät, das sie schaltet.";
CM_ SG_ 1494 PLS_Texte "Anzeige gemäß HMI-Spezifikation
Nur Audi: neue Texte ersetzen Textmultiplexer und Meldungen";
CM_ SG_ 714 QS2_Ist_Wert "Aktuell eingestelltes Kupplungs-(Sperr-)Moment";
CM_ SG_ 714 QS2_Soll_Wert "Bei Fremdsteuerung durch ESP erscheint hier der Wunschsperrgrat, den die Sperre ohne ESP einstellen würde.
Im unbeeinflussten Fall sind Ist- und Sollwert identisch";
CM_ SG_ 714 QS2_Status_VAQ "Statusmaschine: VAQ Status";
CM_ SG_ 714 QS2_Gleichlauf "Dient der Qualifizierung des Ist-Sperrmoments, da dieses nicht während Gleichlauf berechnet werden kann";
CM_ SG_ 714 QS2_KD_Fehler "Bei gesetztem Bit ist mindestens ein Kundendienstfehler eingetragen";
CM_ SG_ 1437 RSF_Tastencode_1 "Übertragung des FFB-Tastencode Remotestart zum MSG, damit MSG unabhängig vom BCM den Remotestart-Befehl auswerten kann.";
CM_ SG_ 1437 RSF_Tastencode_2 "Übertragung des FFB-Tastencode Remotestart zum MSG, damit MSG unabhängig vom BCM den Remotestart-Befehl auswerten kann.";
CM_ SG_ 1437 RSF_Tastencode_Maske "Übertragung des FFB-Tastencode Remotestart zum MSG, damit MSG unabhängig vom BCM den Remotestart-Befehl auswerten kann.";
CM_ SG_ 16 MSG1_WFS_RND "Zufallszahl Anfrage";
CM_ SG_ 16 MSG1_WFS_SIG_E "Signatur Anfrage";
CM_ SG_ 16 MSG1_WFS_P_Klasse "Leistungsklasse";
CM_ SG_ 20 MSG2_WFS_RND "Zufallszahl Anfrage";
CM_ SG_ 20 MSG2_WFS_SIG_E "Signatur Anfrage";
CM_ SG_ 20 MSG2_WFS_P_Klasse "Leistungsklasse";
CM_ SG_ 22 MSG3_WFS_RND "Zufallszahl Anfrage";
CM_ SG_ 22 MSG3_WFS_SIG_E "Signatur Anfrage";
CM_ SG_ 22 MSG3_WFS_P_Klasse "Leistungsklasse";
CM_ SG_ 24 MSG4_WFS_RND "Zufallszahl Anfrage";
CM_ SG_ 24 MSG4_WFS_SIG_E "Signatur Anfrage";
CM_ SG_ 24 MSG4_WFS_P_Klasse "Leistungsklasse";
CM_ BO_ 1500 "CAN-Antrieb";
CM_ SG_ 1500 VL1_Motor_SG "immer 1! (Motorsteuergeraet immer verbaut)";
CM_ SG_ 1500 VL1_Getr_SG "Sollverbau Getriebesteuergeraet";
CM_ SG_ 1500 VL1_ABS "Sollverbau ABS fuer Schlechtweginformation";
CM_ SG_ 1500 VL1_Kombi "1 = Kombi am Antriebs-CAN verbaut";
CM_ SG_ 1500 VL1_LSM "Sollverbau Lenkwinkel";
CM_ SG_ 1500 VL1_Airbag "Airbag-Steuergerät im CAN-Antrieb-Netzwerk
Anmerkungen: Bit auf 0 heißt nicht verbaut (Sollzustand)
Initwert 'const' bedeutet, daß der kodierte Zustand gesendet wird";
CM_ SG_ 1500 VL1_Lenkhilfe "Lenkhilfe (Elektrohydraulische Servolenkung) im CAN-Antrieb-Netzwerk
Anmerkungen: Bit auf 0 heißt nicht verbaut (Sollzustand)
Initwert 'alt' bedeutet, daß der letzte erkannte Zustand gesendet wird (ggfs. 0 nach Klemme 30 Reset)
Clima_VW: Zur Unterschei";
CM_ SG_ 1500 VL1_dyn_LWR "Dynamische Leuchtweitenregulierung / AFS";
CM_ SG_ 1500 VL1_res_08 "Niveauregulierung am CAN Antrieb";
CM_ SG_ 1500 VL1_Allrad "Sollverbau Allrad
";
CM_ SG_ 1500 VL1_ADR "Sollverbau ADR-Steuergeraet";
CM_ SG_ 1500 VL1_ADR_getrennt "ADR-Sensor kann vom CAN-Antrieb abgetrennt werden:
aktueller Zustand dieses Relais wird übertragen
T5 GP mit Rekuperation / Start-Stopp: Bei einmal erkanntem Bus Off wird das Bit gesetzt u. nach 5 Sek stabilem Bus wieder zurückgesetzt.
Initwert 0: Hard";
CM_ SG_ 1500 VL1_EPB "Parkbremse am CAN-Antrieb, bzw. Bremsen-SUB-CAN";
CM_ SG_ 1500 VL1_res_13 "EZS Steuergeraet";
CM_ SG_ 1500 VL1_Daempfer "Daempfer-SG am CAN Antrieb";
CM_ SG_ 1500 VL1_Quersperre "Quersperre im CAN-Antrieb-Netzwerk";
CM_ SG_ 1500 VL1_MotorSlave "Motor Slave im CAN-Antrieb-Netzwerk";
CM_ SG_ 1500 VL1_SWA "SWA Spurwechselassistent";
CM_ SG_ 1500 VL1_HCA "LDW / Heading Control am Antriebs-CAN oder Kamera am Extended-CAN verbaut";
CM_ SG_ 1500 VL1_RKA_Plus "RKA-SG (RKA_Plus) am CAN Antrieb
oder RKA-Plus-Funktion (Senden der CAN-ID 0x443 durch die Bremse!) im Bremsen-SG umgesetzt.";
CM_ SG_ 1500 VL1_PLA "PDC / Park Lenk Assistent am Antiebsstrang";
CM_ SG_ 1500 VL1_WFS_KBI "1 = Wegfahrsperre am Kombi-CAN oder Antriebs-CAN";
CM_ SG_ 1500 VL1_Kombi_KBI "1 = Kombi am Kombi-CAN verbaut";
CM_ SG_ 1500 VL1_Soll_eq_Ist "1 = Sollverbau = Istverbau
0 = Sollverbau ungleich Istverbau";
CM_ SG_ 1500 VL1_BSG_Komf "Sollverbau BSG_Komfort bzw. ILM_Komfort";
CM_ SG_ 1500 VL1_ZKE "Sollverbau ZKE";
CM_ SG_ 1500 VL1_TSG_FT "Sollverbau TSG_FT";
CM_ SG_ 1500 VL1_TSG_BT "Sollverbau TSG_BT";
CM_ SG_ 1500 VL1_TSG_HL "Sollverbau TSG_HL, in der PQ25/T5GP elektrische Schiebetuer HL";
CM_ SG_ 1500 VL1_TSG_HR "Sollverbau TSG_HR, in der PQ25/T5GP elektrische Schiebetuer HR";
CM_ SG_ 1500 VL1_Memory "Sollverbau Memory";
CM_ SG_ 1500 VL1_Dachmodul_K "Reserviert für Dachmodul / Dachdisplay im CAN-Komfort-Netzwerk
Anmerkungen: Bit auf 0 heißt nicht verbaut (Sollzustand)
Initwert 'const' bedeutet, daß der kodierte Zustand gesendet wird";
CM_ SG_ 1500 VL1_Zentralelektrik_II "Sollverbau Zentralelektrik 2 am CAN-Komfort";
CM_ SG_ 1500 VL1_RDK "Sollverbau Reifendruck";
CM_ SG_ 1500 VL1_Lenksaeule "Sollverbau Lenksaeulenmodul/Multifunktionslenkrad";
CM_ SG_ 1500 VL1_Gateway "Sollverbau Gatewaymodul am CAN-Komfort";
CM_ SG_ 1500 VL1_Clima_Komf "Sollverbau Climasteuerung am CAN-Komfort";
CM_ SG_ 1500 VL1_Einparkhilfe "Sollverbau Einparkhilfe";
CM_ SG_ 1500 VL1_PTC_Heizung "1 = PTC-Heizung verbaut";
CM_ SG_ 1500 VL1_Standheiz "Sollverbau, Standheizung am Komfort oder Infotainment";
CM_ SG_ 1500 VL1_Verdeck "Sollverbau Verdecksteuergeraet";
CM_ SG_ 1500 VL1_RSE_I "Sollverbau Rearseatentertainment";
CM_ SG_ 1500 VL1_res_42 "Reserviert für Wischermodul im CAN-Komfort / CAN-Infotainment-Netzwerk
Anmerkungen: Bit auf 0 heißt nicht verbaut (Sollzustand)
Initwert 'const' bedeutet, daß der kodierte Zustand gesendet wird";
CM_ SG_ 1500 VL1_MDI_I "Sollverbau Mobil Device Interface";
CM_ SG_ 1500 VL1_Anhaenger "Sollverbau Anhaengermodul";
CM_ SG_ 1500 VL1_Memory_BF "Sollverbau Sitzmemory_BF";
CM_ SG_ 1500 VL1_Easy_Entry_VF "Sollverbau Easy Entry Fahrer";
CM_ SG_ 1500 VL1_Easy_Entry_VB "Easy Entry Beifahrer";
CM_ SG_ 1500 VL1_Heckdeckel "Verbau des Heckdeckel-Steuergeraetes";
CM_ SG_ 1500 VL1_Rearview "Sollverbau, Rearview am Infotainment";
CM_ SG_ 1500 VL1_Sonderfzg_SG "Sonderfahrzeug-SG";
CM_ SG_ 1500 VL1_Tastenmodul "Sollverbau 10-er Tastatur am CAN-Infotainment";
CM_ SG_ 1500 VL1_Kompass "Sollverbau Kompass am CAN-Infotainment";
CM_ SG_ 1500 VL1_WFS_K "1 = Wegfahrsperre am CAN-Komfort verbaut";
CM_ SG_ 1500 VL1_GSM_Pager "Sollverbau GSM-Pager am CAN-Infotainment";
CM_ SG_ 1500 VL1_InfoElektronik "Sollverbau Infotainment Cockpit am CAN-Komfort";
CM_ SG_ 1500 VL1_DSP "Sollverbau DSP am CAN-Infotainment";
CM_ SG_ 1500 VL1_DAB "Sollverbau auch fuer SDARS Tuner";
CM_ SG_ 1500 VL1_Telematik "Sollverbau Telematik am CAN-Infotainment";
CM_ SG_ 1500 VL1_Navigation "Sollverbau; Fuer RNS werden die BITs Radio und Navigation gesetzt (Logische Komponenten)
Navigation am CAN-Infotainment";
CM_ SG_ 1500 VL1_TV_Tuner "Sollverbau TV_Tuner am CAN-Infotainment";
CM_ SG_ 1500 VL1_Neigungsmodul_I "Sollverbau Neigungsmodul am CAN-Infotainment";
CM_ SG_ 1500 VL1_Radio "Sollverbau; Fuer RNS werden die BITs Radio und Navigation gesetzt (Logische Komponenten)
Radio am CAN-Infotainment";
CM_ SG_ 1500 VL1_Telefon "Sollverbau Telefon am CAN-Infotainment";
CM_ BO_ 1488 "CAN-Antrieb CAN-Dashboard";
CM_ SG_ 1488 SY1_CAN_extern "zweipoliger Schalter, der den CAN-Antrieb auf den Diagnosestecker legt, ist geschlossen oder es werden Nutzdaten des CAN-Antrieb auf den Diagnose-CAN gespiegelt
CAN-Extern zugeschaltet";
CM_ SG_ 1488 SY1_Diag_Ant "mindestens ein Teilnehmer hat die Diagnoseeröffnung auf dem CAN bestätigt; im PQ35/46 derzeit nicht unterstützt
CAN-Antrieb in Diagnose";
CM_ SG_ 1488 SY1_Sleep_Komf "CAN-Komfort-Netzwerk schläft";
CM_ SG_ 1488 SY1_Diag_Komf "mindestens ein Teilnehmer hat die Diagnoseeröffnung auf dem Komfort-CAN bestätigt; im PQ35/46 derzeit nicht unterstützt
CAN-Komfort in Diagnose";
CM_ SG_ 1488 SY1_Sleep_Info "CAN-Infotainment-Netzwerk schläft";
CM_ SG_ 1488 SY1_Diag_Info "mindestens ein Teilnehmer hat die Diagnoseeröffnung auf dem Infotainment-CAN bestätigt; im PQ35/46 derzeit nicht unterstützt
CAN-Infotainment in Diagnose";
CM_ SG_ 1488 SY1_CAN_Info "der CAN-Infotainment ist vom CAN-Komfort physikalisch getrennt";
CM_ SG_ 1488 SY1_Verbauinfo "ungültig bedeutet: Verbauinformation ist noch nicht vollständig: Gateway nicht kodiert";
CM_ SG_ 1488 SY1_Fzg_Klasse "bei PQ24 wird z.Zt. A0-Klasse ausgegeben
Fahrzeug-Klasse";
CM_ SG_ 1488 SY1_Fzg_Marke "Marke wird im Gateway-SG kodiert: Unkodierte PQ35-Gateway-SG geben '1' aus
Fahrzeug-Marke";
CM_ SG_ 1488 SY1_Fzg_Derivat "Achtung: Derivate, die sich im Bordnetz nicht unterscheiden, werden ggfs. zusammengefaßt
Derivat wird im Gateway-SG kodiert
Unkodierte PQ35/46-Gateway-SG geben 15d aus
0 = Kurzheck oder Multivan
1 = Stufenheck oder Nutzfzg.
2 = Variant
3 = Fliesshec";
CM_ SG_ 1488 SY1_Fzg_Gen "z.B. 5 für PQ35
Fahrzeug-Generation";
CM_ SG_ 1488 SY1_Fzg_Index "Im PQ35/46 derzeit nicht unterstützt: 15d für 'nicht bekannt' wird ausgegeben";
CM_ SG_ 1488 SY1_Lenker "Info wird im Gateway-SG kodiert
Unkodierte PQ35/46-Gateway-SG geben 0 aus";
CM_ SG_ 1488 SY1_Tueren "Info wird im Gateway-SG kodiert
Unkodierte PQ35/46-Gateway-SG geben 0 aus";
CM_ SG_ 1488 SY1_Transportmode "1 = Transportmodus aktiv, funktionale Einschränkungen bzw. Änderungen für den Fzg.-Transport";
CM_ SG_ 1488 SY1_Fehlereintr "Bei gesetztem Bit ist mindestens ein KD-Fehler unter der Gateway Adresse abgelegt";
CM_ SG_ 1488 SY1_Komf_NV "Anmerkung: das Gateway-Steuergerät erfüllt die Funktionalität dieser CAN-Version
CAN-Stand Komfort-Daten-Nebenversion";
CM_ SG_ 1488 SY1_Komf_HV "Anmerkung: das Gateway-Steuergerät erfüllt die Funktionalität dieser CAN-Version
CAN-Stand Komfort-Daten-Hauptversion";
CM_ SG_ 1488 SY1_Ant_NV "Anmerkung: das Gateway-Steuergerät erfüllt die Funktionalität dieser CAN-Version
CAN-Stand Antrieb-Daten-Nebenversion";
CM_ SG_ 1488 SY1_Ant_HV "Anmerkung: das Gateway-Steuergerät erfüllt die Funktionalität dieser CAN-Version
CAN-Stand Antrieb-Daten-Hauptversion";
CM_ SG_ 1488 SY1_Relais_FAS_Zweig "FAS-Zweig (mit ACC, SWA,...) wird vom CAN-Antrieb über ein Relais abgetrennt:
01: gewolltes Abschalten (zu schützende Kommunikation, z. B. im Hochlauf)
10: nach zweimaligem BusOff bis 'Kl. 15' aus abgetrennt
(im PQ46 und Touareg GP, D1GP/BY61x)
Hinwei";
CM_ SG_ 1488 SY1_ELV_Lock_Supply "Gateway gibt eine zusätzliche Freigabe für die ELV (elektrische Lenkradverriegelung) (z. Zt. nur PQ46)";
CM_ SG_ 1488 SY1_QRS_Messmodus "1 = Quick-Ruhestrommessmodus (früher: Fabrikmodus), Fzg geht innerhalb 1min in Ruhestrom
siehe auch Lastenheft LH_TRM_QRS";
CM_ SG_ 1488 SY1_NWDF_gueltig "Gültigkeit der Netzwerk-Diagnose Freigabe (Byte 7, Bit 7)";
CM_ SG_ 1488 SY1_NWDF "Netzwerk-Diagnose Freigabe zur zentralen Aktivierung der Netzwerkdiagnose";
CM_ SG_ 1488 SY1_Notbrems_Status "Gateway erkennt Notbremssituation (z. Zt. nur PQ46, PQ35 ab MJ07)
Notbremsstatus";
CM_ SG_ 1225 Tele_Data_BMS "Telemetriedaten von BMS für GSM-Modul (Entwicklerbotschaften)";
BA_DEF_ BO_  "GenMsgAutoGenDsp" ENUM  "No","Yes";
BA_DEF_ BO_  "GenMsgAutoGenSnd" ENUM  "No","Yes";
BA_DEF_ BO_  "GenMsgCycleTime" INT 0 65535;
BA_DEF_ BO_  "GenMsgCycleTimeFast" INT 0 65535;
BA_DEF_ BO_  "GenMsgDelayTime" INT 0 100000;
BA_DEF_ BO_  "GenMsgILSupport" ENUM  "No","Yes";
BA_DEF_ BO_  "GenMsgSendType" ENUM  "Cyclic","not_used","not_used","not_used","not_used","not_used","not_used","IfActive","NoMsgSendType";
BA_DEF_ BO_  "GenMsgStartDelayTime" INT 0 100000;
BA_DEF_ BO_  "NmMessage" ENUM  "No","Yes";
BA_DEF_ BO_  "NmhMessage" ENUM  "No","Yes";
BA_DEF_ BO_  "VAGTP20_API" HEX 0 255;
BA_DEF_ BO_  "VAGTP20_DynConnection" ENUM  "No","Yes";
BA_DEF_ BO_  "VAGTP20_DynSetup" ENUM  "No","Yes";
BA_DEF_ BO_  "VAGTP20_StatConnection" ENUM  "No","Yes";
BA_DEF_ BO_  "Timeoutzeit" INT 0 1000000;
BA_DEF_ BO_  "DiagRequest" ENUM  "No","Yes";
BA_DEF_ BO_  "DiagResponse" ENUM  "No","Yes";
BA_DEF_ BO_  "DiagState" ENUM  "No","Yes";
BA_DEF_ BO_  "GenMsgChkConstant" HEX 0 4095;
BA_DEF_ SG_  "GenSigAutoGenDsp" ENUM  "No","Yes";
BA_DEF_ SG_  "GenSigAutoGenSnd" ENUM  "No","Yes";
BA_DEF_ SG_  "GenSigEnvVarType" ENUM  "int","float","undef";
BA_DEF_ SG_  "GenSigInactiveValue" INT -2147483648 2147483647;
BA_DEF_ SG_  "GenSigSendType" ENUM  "Cyclic","OnWrite","OnWriteWithRepetition","OnChange","OnChangeWithRepetition","IfActive","IfActiveWithRepetition","NoSigSendType","OnChangeAndIfActive","OnChangeAndIfActiveWithRepetition";
BA_DEF_ SG_  "GenSigStartValue" INT -2147483648 2147483647;
BA_DEF_ SG_  "NWM-WakeupAllowed" ENUM  "No","Yes";
BA_DEF_ SG_  "GenSigFuncType" ENUM  "NoFunction","MsgCounter","CRC-8","XOR","XOR-2","DatedBit","SW-Kl15","CHK","Constant","Protocol";
BA_DEF_ SG_  "GenSigSwitchedByIgnition" ENUM  "No","Yes";
BA_DEF_ SG_  "Fehlerwert" HEX 0 2147483647;
BA_DEF_ SG_  "GenSigMissingSourceValue" HEX 0 2147483647;
BA_DEF_REL_ BU_SG_REL_  "GenSigTimeoutTime" INT 0 65535;
BA_DEF_DEF_REL_ "GenSigTimeoutTime" 0;
BA_DEF_DEF_  "GenMsgAutoGenDsp" "Yes";
BA_DEF_DEF_  "GenMsgAutoGenSnd" "Yes";
BA_DEF_DEF_  "GenMsgCycleTime" 0;
BA_DEF_DEF_  "GenMsgCycleTimeFast" 0;
BA_DEF_DEF_  "GenMsgDelayTime" 0;
BA_DEF_DEF_  "GenMsgILSupport" "No";
BA_DEF_DEF_  "GenMsgSendType" "NoMsgSendType";
BA_DEF_DEF_  "GenMsgStartDelayTime" 0;
BA_DEF_DEF_  "NmMessage" "No";
BA_DEF_DEF_  "NmhMessage" "No";
BA_DEF_DEF_  "VAGTP20_API" 0;
BA_DEF_DEF_  "VAGTP20_DynConnection" "No";
BA_DEF_DEF_  "VAGTP20_DynSetup" "No";
BA_DEF_DEF_  "VAGTP20_StatConnection" "No";
BA_DEF_DEF_  "Timeoutzeit" 0;
BA_DEF_DEF_  "DiagRequest" "No";
BA_DEF_DEF_  "DiagResponse" "No";
BA_DEF_DEF_  "DiagState" "No";
BA_DEF_DEF_  "GenMsgChkConstant" 0;
BA_DEF_DEF_  "GenSigAutoGenDsp" "No";
BA_DEF_DEF_  "GenSigAutoGenSnd" "No";
BA_DEF_DEF_  "GenSigEnvVarType" "undef";
BA_DEF_DEF_  "GenSigInactiveValue" 0;
BA_DEF_DEF_  "GenSigSendType" "NoSigSendType";
BA_DEF_DEF_  "GenSigStartValue" 0;
BA_DEF_DEF_  "NWM-WakeupAllowed" "No";
BA_DEF_DEF_  "GenSigFuncType" "NoFunction";
BA_DEF_DEF_  "GenSigSwitchedByIgnition" "Yes";
BA_DEF_DEF_  "Fehlerwert" 0;
BA_DEF_DEF_  "GenSigMissingSourceValue" 0;
BA_ "GenMsgSendType" BO_ 1160 0;
BA_ "GenMsgILSupport" BO_ 1160 1;
BA_ "GenMsgCycleTime" BO_ 1160 10;
BA_ "GenMsgSendType" BO_ 1416 0;
BA_ "GenMsgILSupport" BO_ 1416 1;
BA_ "GenMsgCycleTime" BO_ 1416 20;
BA_ "GenMsgSendType" BO_ 1162 0;
BA_ "GenMsgILSupport" BO_ 1162 1;
BA_ "GenMsgCycleTime" BO_ 1162 20;
BA_ "GenMsgSendType" BO_ 644 0;
BA_ "GenMsgILSupport" BO_ 644 1;
BA_ "GenMsgCycleTime" BO_ 644 20;
BA_ "GenMsgSendType" BO_ 1800 0;
BA_ "GenMsgILSupport" BO_ 1800 1;
BA_ "GenMsgCycleTime" BO_ 1800 200;
BA_ "GenMsgSendType" BO_ 1408 0;
BA_ "GenMsgILSupport" BO_ 1408 1;
BA_ "GenMsgCycleTime" BO_ 1408 1000;
BA_ "GenMsgSendType" BO_ 1154 0;
BA_ "GenMsgILSupport" BO_ 1154 1;
BA_ "GenMsgCycleTime" BO_ 1154 20;
BA_ "GenMsgSendType" BO_ 399 0;
BA_ "GenMsgILSupport" BO_ 399 1;
BA_ "GenMsgCycleTime" BO_ 399 10;
BA_ "GenMsgSendType" BO_ 1823 0;
BA_ "GenMsgILSupport" BO_ 1823 1;
BA_ "GenMsgCycleTime" BO_ 1823 100;
BA_ "GenMsgSendType" BO_ 1428 0;
BA_ "GenMsgILSupport" BO_ 1428 1;
BA_ "GenMsgCycleTime" BO_ 1428 25;
BA_ "GenMsgSendType" BO_ 1349 0;
BA_ "GenMsgILSupport" BO_ 1349 1;
BA_ "GenMsgDelayTime" BO_ 1349 50;
BA_ "GenMsgCycleTime" BO_ 1349 500;
BA_ "GenMsgSendType" BO_ 1355 7;
BA_ "GenMsgILSupport" BO_ 1355 1;
BA_ "GenMsgCycleTimeFast" BO_ 1355 100;
BA_ "GenMsgSendType" BO_ 980 0;
BA_ "GenMsgILSupport" BO_ 980 1;
BA_ "GenMsgCycleTime" BO_ 980 20;
BA_ "GenMsgSendType" BO_ 1494 0;
BA_ "GenMsgILSupport" BO_ 1494 1;
BA_ "GenMsgCycleTime" BO_ 1494 100;
BA_ "GenMsgSendType" BO_ 714 0;
BA_ "GenMsgILSupport" BO_ 714 1;
BA_ "GenMsgCycleTime" BO_ 714 10;
BA_ "GenMsgSendType" BO_ 1437 7;
BA_ "GenMsgILSupport" BO_ 1437 1;
BA_ "GenMsgCycleTimeFast" BO_ 1437 500;
BA_ "GenMsgSendType" BO_ 16 7;
BA_ "GenMsgSendType" BO_ 20 7;
BA_ "GenMsgSendType" BO_ 22 7;
BA_ "GenMsgSendType" BO_ 24 7;
BA_ "GenMsgSendType" BO_ 1500 0;
BA_ "GenMsgILSupport" BO_ 1500 1;
BA_ "GenMsgCycleTime" BO_ 1500 100;
BA_ "GenMsgSendType" BO_ 1488 0;
BA_ "GenMsgILSupport" BO_ 1488 1;
BA_ "GenMsgDelayTime" BO_ 1488 10;
BA_ "GenMsgCycleTime" BO_ 1488 100;
BA_ "GenMsgSendType" BO_ 1225 0;
BA_ "GenMsgCycleTime" BO_ 1225 200;
BA_ "GenSigSwitchedByIgnition" SG_ 1160 MO6_Checksum 0;
BA_ "GenSigFuncType" SG_ 1160 MO6_Checksum 4;
BA_ "GenSigSendType" SG_ 1160 MO6_Checksum 0;
BA_ "GenSigAutoGenSnd" SG_ 1160 MO6_Checksum 1;
BA_ "GenSigAutoGenDsp" SG_ 1160 MO6_Checksum 1;
BA_ "Fehlerwert" SG_ 1160 MO6_SollM_Getr 255;
BA_ "GenSigSwitchedByIgnition" SG_ 1160 MO6_SollM_Getr 0;
BA_ "GenSigSendType" SG_ 1160 MO6_SollM_Getr 0;
BA_ "GenSigAutoGenSnd" SG_ 1160 MO6_SollM_Getr 1;
BA_ "GenSigAutoGenDsp" SG_ 1160 MO6_SollM_Getr 1;
BA_ "Fehlerwert" SG_ 1160 MO6_Ist_Moment 255;
BA_ "GenSigSwitchedByIgnition" SG_ 1160 MO6_Ist_Moment 0;
BA_ "GenSigSendType" SG_ 1160 MO6_Ist_Moment 0;
BA_ "GenSigAutoGenSnd" SG_ 1160 MO6_Ist_Moment 1;
BA_ "GenSigAutoGenDsp" SG_ 1160 MO6_Ist_Moment 1;
BA_ "Fehlerwert" SG_ 1160 MO6_Hoeheninfo 255;
BA_ "GenSigSwitchedByIgnition" SG_ 1160 MO6_Hoeheninfo 0;
BA_ "GenSigSendType" SG_ 1160 MO6_Hoeheninfo 0;
BA_ "GenSigAutoGenSnd" SG_ 1160 MO6_Hoeheninfo 1;
BA_ "GenSigAutoGenDsp" SG_ 1160 MO6_Hoeheninfo 1;
BA_ "GenSigSwitchedByIgnition" SG_ 1160 MO6_GRA_Soll 0;
BA_ "GenSigStartValue" SG_ 1160 MO6_GRA_Soll 166;
BA_ "GenSigSendType" SG_ 1160 MO6_GRA_Soll 0;
BA_ "GenSigAutoGenSnd" SG_ 1160 MO6_GRA_Soll 1;
BA_ "GenSigAutoGenDsp" SG_ 1160 MO6_GRA_Soll 1;
BA_ "GenSigSwitchedByIgnition" SG_ 1160 MO6_MomIntGeEing 0;
BA_ "GenSigSendType" SG_ 1160 MO6_MomIntGeEing 0;
BA_ "GenSigAutoGenSnd" SG_ 1160 MO6_MomIntGeEing 1;
BA_ "GenSigAutoGenDsp" SG_ 1160 MO6_MomIntGeEing 1;
BA_ "GenSigSwitchedByIgnition" SG_ 1160 MO6_FF_Mux00 0;
BA_ "GenSigStartValue" SG_ 1160 MO6_FF_Mux00 255;
BA_ "GenSigAutoGenSnd" SG_ 1160 MO6_FF_Mux00 1;
BA_ "GenSigAutoGenDsp" SG_ 1160 MO6_FF_Mux00 1;
BA_ "GenSigSwitchedByIgnition" SG_ 1160 MO6_FF_Mux01 0;
BA_ "GenSigStartValue" SG_ 1160 MO6_FF_Mux01 255;
BA_ "GenSigAutoGenSnd" SG_ 1160 MO6_FF_Mux01 1;
BA_ "GenSigAutoGenDsp" SG_ 1160 MO6_FF_Mux01 1;
BA_ "GenSigSwitchedByIgnition" SG_ 1160 MO6_FF_Mux02 0;
BA_ "GenSigStartValue" SG_ 1160 MO6_FF_Mux02 255;
BA_ "GenSigAutoGenSnd" SG_ 1160 MO6_FF_Mux02 1;
BA_ "GenSigAutoGenDsp" SG_ 1160 MO6_FF_Mux02 1;
BA_ "GenSigSwitchedByIgnition" SG_ 1160 MO6_FF_Mux03 0;
BA_ "GenSigStartValue" SG_ 1160 MO6_FF_Mux03 255;
BA_ "GenSigAutoGenSnd" SG_ 1160 MO6_FF_Mux03 1;
BA_ "GenSigAutoGenDsp" SG_ 1160 MO6_FF_Mux03 1;
BA_ "GenSigSwitchedByIgnition" SG_ 1160 MO6_FF_Mux04 0;
BA_ "GenSigStartValue" SG_ 1160 MO6_FF_Mux04 255;
BA_ "GenSigAutoGenSnd" SG_ 1160 MO6_FF_Mux04 1;
BA_ "GenSigAutoGenDsp" SG_ 1160 MO6_FF_Mux04 1;
BA_ "GenSigSwitchedByIgnition" SG_ 1160 MO6_FF_Mux05 0;
BA_ "GenSigStartValue" SG_ 1160 MO6_FF_Mux05 255;
BA_ "GenSigAutoGenSnd" SG_ 1160 MO6_FF_Mux05 1;
BA_ "GenSigAutoGenDsp" SG_ 1160 MO6_FF_Mux05 1;
BA_ "GenSigSwitchedByIgnition" SG_ 1160 MO6_FF_Mux06 0;
BA_ "GenSigStartValue" SG_ 1160 MO6_FF_Mux06 255;
BA_ "GenSigAutoGenSnd" SG_ 1160 MO6_FF_Mux06 1;
BA_ "GenSigAutoGenDsp" SG_ 1160 MO6_FF_Mux06 1;
BA_ "GenSigSwitchedByIgnition" SG_ 1160 MO6_FF_Mux07 0;
BA_ "GenSigStartValue" SG_ 1160 MO6_FF_Mux07 255;
BA_ "GenSigAutoGenSnd" SG_ 1160 MO6_FF_Mux07 1;
BA_ "GenSigAutoGenDsp" SG_ 1160 MO6_FF_Mux07 1;
BA_ "GenSigSwitchedByIgnition" SG_ 1160 MO6_FF_Mux08 0;
BA_ "GenSigStartValue" SG_ 1160 MO6_FF_Mux08 255;
BA_ "GenSigAutoGenSnd" SG_ 1160 MO6_FF_Mux08 1;
BA_ "GenSigAutoGenDsp" SG_ 1160 MO6_FF_Mux08 1;
BA_ "GenSigSwitchedByIgnition" SG_ 1160 MO6_FF_Mux09 0;
BA_ "GenSigStartValue" SG_ 1160 MO6_FF_Mux09 255;
BA_ "GenSigAutoGenSnd" SG_ 1160 MO6_FF_Mux09 1;
BA_ "GenSigAutoGenDsp" SG_ 1160 MO6_FF_Mux09 1;
BA_ "GenSigSwitchedByIgnition" SG_ 1160 MO6_FF_Mux10 0;
BA_ "GenSigStartValue" SG_ 1160 MO6_FF_Mux10 255;
BA_ "GenSigAutoGenSnd" SG_ 1160 MO6_FF_Mux10 1;
BA_ "GenSigAutoGenDsp" SG_ 1160 MO6_FF_Mux10 1;
BA_ "GenSigSwitchedByIgnition" SG_ 1160 MO6_FF_Mux11 0;
BA_ "GenSigStartValue" SG_ 1160 MO6_FF_Mux11 255;
BA_ "GenSigAutoGenSnd" SG_ 1160 MO6_FF_Mux11 1;
BA_ "GenSigAutoGenDsp" SG_ 1160 MO6_FF_Mux11 1;
BA_ "GenSigSwitchedByIgnition" SG_ 1160 MO6_FF_Mux12 0;
BA_ "GenSigStartValue" SG_ 1160 MO6_FF_Mux12 255;
BA_ "GenSigAutoGenSnd" SG_ 1160 MO6_FF_Mux12 1;
BA_ "GenSigAutoGenDsp" SG_ 1160 MO6_FF_Mux12 1;
BA_ "GenSigSwitchedByIgnition" SG_ 1160 MO6_FF_Mux13 0;
BA_ "GenSigStartValue" SG_ 1160 MO6_FF_Mux13 255;
BA_ "GenSigAutoGenSnd" SG_ 1160 MO6_FF_Mux13 1;
BA_ "GenSigAutoGenDsp" SG_ 1160 MO6_FF_Mux13 1;
BA_ "GenSigSwitchedByIgnition" SG_ 1160 MO6_FF_Mux14 0;
BA_ "GenSigStartValue" SG_ 1160 MO6_FF_Mux14 255;
BA_ "GenSigAutoGenSnd" SG_ 1160 MO6_FF_Mux14 1;
BA_ "GenSigAutoGenDsp" SG_ 1160 MO6_FF_Mux14 1;
BA_ "GenSigSwitchedByIgnition" SG_ 1160 MO6_FF_Mux15 0;
BA_ "GenSigStartValue" SG_ 1160 MO6_FF_Mux15 255;
BA_ "GenSigAutoGenSnd" SG_ 1160 MO6_FF_Mux15 1;
BA_ "GenSigAutoGenDsp" SG_ 1160 MO6_FF_Mux15 1;
BA_ "GenSigSwitchedByIgnition" SG_ 1160 MO6_Freigabe_GRA 0;
BA_ "GenSigSendType" SG_ 1160 MO6_Freigabe_GRA 0;
BA_ "GenSigAutoGenSnd" SG_ 1160 MO6_Freigabe_GRA 1;
BA_ "GenSigAutoGenDsp" SG_ 1160 MO6_Freigabe_GRA 1;
BA_ "GenSigSwitchedByIgnition" SG_ 1160 MO6_Schutz_Toel 0;
BA_ "GenSigSendType" SG_ 1160 MO6_Schutz_Toel 0;
BA_ "GenSigAutoGenSnd" SG_ 1160 MO6_Schutz_Toel 1;
BA_ "GenSigAutoGenDsp" SG_ 1160 MO6_Schutz_Toel 1;
BA_ "GenSigSwitchedByIgnition" SG_ 1160 MO6_Luftpfad_akt 0;
BA_ "GenSigSendType" SG_ 1160 MO6_Luftpfad_akt 0;
BA_ "GenSigAutoGenSnd" SG_ 1160 MO6_Luftpfad_akt 1;
BA_ "GenSigAutoGenDsp" SG_ 1160 MO6_Luftpfad_akt 1;
BA_ "GenSigSwitchedByIgnition" SG_ 1160 MO6_RegPartikel 0;
BA_ "GenSigSendType" SG_ 1160 MO6_RegPartikel 0;
BA_ "GenSigAutoGenSnd" SG_ 1160 MO6_RegPartikel 1;
BA_ "GenSigAutoGenDsp" SG_ 1160 MO6_RegPartikel 1;
BA_ "GenSigSwitchedByIgnition" SG_ 1160 MO6_Zaehler 0;
BA_ "GenSigFuncType" SG_ 1160 MO6_Zaehler 1;
BA_ "GenSigSendType" SG_ 1160 MO6_Zaehler 0;
BA_ "GenSigAutoGenSnd" SG_ 1160 MO6_Zaehler 1;
BA_ "GenSigAutoGenDsp" SG_ 1160 MO6_Zaehler 1;
BA_ "GenSigSwitchedByIgnition" SG_ 1416 MO7_LL_Solldz 0;
BA_ "GenSigSendType" SG_ 1416 MO7_LL_Solldz 0;
BA_ "GenSigAutoGenSnd" SG_ 1416 MO7_LL_Solldz 1;
BA_ "GenSigAutoGenDsp" SG_ 1416 MO7_LL_Solldz 1;
BA_ "GenSigSwitchedByIgnition" SG_ 1416 MO7_Fehler_VBegr 0;
BA_ "GenSigSendType" SG_ 1416 MO7_Fehler_VBegr 0;
BA_ "GenSigAutoGenSnd" SG_ 1416 MO7_Fehler_VBegr 1;
BA_ "GenSigAutoGenDsp" SG_ 1416 MO7_Fehler_VBegr 1;
BA_ "GenSigSwitchedByIgnition" SG_ 1416 MO7_Sta_VBegr 0;
BA_ "GenSigSendType" SG_ 1416 MO7_Sta_VBegr 0;
BA_ "GenSigAutoGenSnd" SG_ 1416 MO7_Sta_VBegr 1;
BA_ "GenSigAutoGenDsp" SG_ 1416 MO7_Sta_VBegr 1;
BA_ "GenSigSwitchedByIgnition" SG_ 1416 MO7_Fehlereintr 0;
BA_ "GenSigSendType" SG_ 1416 MO7_Fehlereintr 0;
BA_ "GenSigAutoGenSnd" SG_ 1416 MO7_Fehlereintr 1;
BA_ "GenSigAutoGenDsp" SG_ 1416 MO7_Fehlereintr 1;
BA_ "GenSigSwitchedByIgnition" SG_ 1416 MO7_StaOeltemp 0;
BA_ "GenSigStartValue" SG_ 1416 MO7_StaOeltemp 1;
BA_ "GenSigSendType" SG_ 1416 MO7_StaOeltemp 0;
BA_ "GenSigAutoGenSnd" SG_ 1416 MO7_StaOeltemp 1;
BA_ "GenSigAutoGenDsp" SG_ 1416 MO7_StaOeltemp 1;
BA_ "GenSigSwitchedByIgnition" SG_ 1416 MO7_Sta_PTC 0;
BA_ "GenSigStartValue" SG_ 1416 MO7_Sta_PTC 7;
BA_ "GenSigSendType" SG_ 1416 MO7_Sta_PTC 0;
BA_ "GenSigAutoGenSnd" SG_ 1416 MO7_Sta_PTC 1;
BA_ "GenSigAutoGenDsp" SG_ 1416 MO7_Sta_PTC 1;
BA_ "Fehlerwert" SG_ 1416 MO7_DFM 255;
BA_ "GenSigSwitchedByIgnition" SG_ 1416 MO7_DFM 0;
BA_ "GenSigSendType" SG_ 1416 MO7_DFM 0;
BA_ "GenSigAutoGenSnd" SG_ 1416 MO7_DFM 1;
BA_ "GenSigAutoGenDsp" SG_ 1416 MO7_DFM 1;
BA_ "Fehlerwert" SG_ 1416 MO7_Hoeheninfo 255;
BA_ "GenSigSwitchedByIgnition" SG_ 1416 MO7_Hoeheninfo 0;
BA_ "GenSigSendType" SG_ 1416 MO7_Hoeheninfo 0;
BA_ "GenSigAutoGenSnd" SG_ 1416 MO7_Hoeheninfo 1;
BA_ "GenSigAutoGenDsp" SG_ 1416 MO7_Hoeheninfo 1;
BA_ "GenSigSwitchedByIgnition" SG_ 1416 MO7_Gradient_Dz 0;
BA_ "GenSigSendType" SG_ 1416 MO7_Gradient_Dz 0;
BA_ "GenSigAutoGenSnd" SG_ 1416 MO7_Gradient_Dz 1;
BA_ "GenSigAutoGenDsp" SG_ 1416 MO7_Gradient_Dz 1;
BA_ "GenSigSwitchedByIgnition" SG_ 1416 MO7_GradientVorz 0;
BA_ "GenSigSendType" SG_ 1416 MO7_GradientVorz 0;
BA_ "GenSigAutoGenSnd" SG_ 1416 MO7_GradientVorz 1;
BA_ "GenSigAutoGenDsp" SG_ 1416 MO7_GradientVorz 1;
BA_ "Fehlerwert" SG_ 1416 MO7_Ladedruckneu 255;
BA_ "GenSigSwitchedByIgnition" SG_ 1416 MO7_Ladedruckneu 0;
BA_ "GenSigSendType" SG_ 1416 MO7_Ladedruckneu 0;
BA_ "GenSigAutoGenSnd" SG_ 1416 MO7_Ladedruckneu 1;
BA_ "GenSigAutoGenDsp" SG_ 1416 MO7_Ladedruckneu 1;
BA_ "GenSigSwitchedByIgnition" SG_ 1416 MO7_GenLdResp 0;
BA_ "GenSigSendType" SG_ 1416 MO7_GenLdResp 0;
BA_ "GenSigAutoGenSnd" SG_ 1416 MO7_GenLdResp 1;
BA_ "GenSigAutoGenDsp" SG_ 1416 MO7_GenLdResp 1;
BA_ "GenSigSwitchedByIgnition" SG_ 1416 MO7_PTC_bereit 0;
BA_ "GenSigSendType" SG_ 1416 MO7_PTC_bereit 0;
BA_ "GenSigAutoGenSnd" SG_ 1416 MO7_PTC_bereit 1;
BA_ "GenSigAutoGenDsp" SG_ 1416 MO7_PTC_bereit 1;
BA_ "GenSigSwitchedByIgnition" SG_ 1416 MO7_Mot_weckfaehig 0;
BA_ "GenSigSendType" SG_ 1416 MO7_Mot_weckfaehig 0;
BA_ "GenSigAutoGenSnd" SG_ 1416 MO7_Mot_weckfaehig 1;
BA_ "GenSigAutoGenDsp" SG_ 1416 MO7_Mot_weckfaehig 1;
BA_ "GenSigSwitchedByIgnition" SG_ 1416 MO7_Zus_Kuehl 0;
BA_ "GenSigSendType" SG_ 1416 MO7_Zus_Kuehl 0;
BA_ "GenSigAutoGenSnd" SG_ 1416 MO7_Zus_Kuehl 1;
BA_ "GenSigAutoGenDsp" SG_ 1416 MO7_Zus_Kuehl 1;
BA_ "GenSigSwitchedByIgnition" SG_ 1416 MO7_SleepInd 0;
BA_ "GenSigSendType" SG_ 1416 MO7_SleepInd 0;
BA_ "GenSigAutoGenSnd" SG_ 1416 MO7_SleepInd 1;
BA_ "GenSigAutoGenDsp" SG_ 1416 MO7_SleepInd 1;
BA_ "GenSigSwitchedByIgnition" SG_ 1416 MO7_RueckLLDz 0;
BA_ "GenSigSendType" SG_ 1416 MO7_RueckLLDz 0;
BA_ "GenSigAutoGenSnd" SG_ 1416 MO7_RueckLLDz 1;
BA_ "GenSigAutoGenDsp" SG_ 1416 MO7_RueckLLDz 1;
BA_ "GenSigSwitchedByIgnition" SG_ 1416 MO7_Lastabwurf 0;
BA_ "GenSigSendType" SG_ 1416 MO7_Lastabwurf 0;
BA_ "GenSigAutoGenSnd" SG_ 1416 MO7_Lastabwurf 1;
BA_ "GenSigAutoGenDsp" SG_ 1416 MO7_Lastabwurf 1;
BA_ "GenSigSwitchedByIgnition" SG_ 1416 MO7_Gen_ein 0;
BA_ "GenSigSendType" SG_ 1416 MO7_Gen_ein 0;
BA_ "GenSigAutoGenSnd" SG_ 1416 MO7_Gen_ein 1;
BA_ "GenSigAutoGenDsp" SG_ 1416 MO7_Gen_ein 1;
BA_ "GenSigSwitchedByIgnition" SG_ 1416 MO7_Lastabw_Heiz 0;
BA_ "GenSigSendType" SG_ 1416 MO7_Lastabw_Heiz 0;
BA_ "GenSigAutoGenSnd" SG_ 1416 MO7_Lastabw_Heiz 1;
BA_ "GenSigAutoGenDsp" SG_ 1416 MO7_Lastabw_Heiz 1;
BA_ "Fehlerwert" SG_ 1416 MO7_StaGluehk 15;
BA_ "GenSigSwitchedByIgnition" SG_ 1416 MO7_StaGluehk 0;
BA_ "GenSigSendType" SG_ 1416 MO7_StaGluehk 0;
BA_ "GenSigAutoGenSnd" SG_ 1416 MO7_StaGluehk 1;
BA_ "GenSigAutoGenDsp" SG_ 1416 MO7_StaGluehk 1;
BA_ "Fehlerwert" SG_ 1416 MO7_Oeltemp 255;
BA_ "GenSigSwitchedByIgnition" SG_ 1416 MO7_Oeltemp 0;
BA_ "GenSigStartValue" SG_ 1416 MO7_Oeltemp 1;
BA_ "GenSigSendType" SG_ 1416 MO7_Oeltemp 0;
BA_ "GenSigAutoGenSnd" SG_ 1416 MO7_Oeltemp 1;
BA_ "GenSigAutoGenDsp" SG_ 1416 MO7_Oeltemp 1;
BA_ "GenSigSwitchedByIgnition" SG_ 1162 MO8_Checksumme 0;
BA_ "GenSigFuncType" SG_ 1162 MO8_Checksumme 4;
BA_ "GenSigSendType" SG_ 1162 MO8_Checksumme 0;
BA_ "GenSigAutoGenSnd" SG_ 1162 MO8_Checksumme 1;
BA_ "GenSigAutoGenDsp" SG_ 1162 MO8_Checksumme 1;
BA_ "Fehlerwert" SG_ 1162 MO8_AnzeigeDZ 4095;
BA_ "GenSigSwitchedByIgnition" SG_ 1162 MO8_AnzeigeDZ 0;
BA_ "GenSigSendType" SG_ 1162 MO8_AnzeigeDZ 0;
BA_ "GenSigAutoGenSnd" SG_ 1162 MO8_AnzeigeDZ 1;
BA_ "GenSigAutoGenDsp" SG_ 1162 MO8_AnzeigeDZ 1;
BA_ "GenSigSwitchedByIgnition" SG_ 1162 WBA_Effizienzmodus 0;
BA_ "GenSigSendType" SG_ 1162 WBA_Effizienzmodus 0;
BA_ "GenSigSwitchedByIgnition" SG_ 1162 MO8_SGT_Soundakt 0;
BA_ "GenSigSendType" SG_ 1162 MO8_SGT_Soundakt 0;
BA_ "GenSigAutoGenSnd" SG_ 1162 MO8_SGT_Soundakt 1;
BA_ "GenSigAutoGenDsp" SG_ 1162 MO8_SGT_Soundakt 1;
BA_ "GenSigSwitchedByIgnition" SG_ 1162 MO8_Spoiler_ausf 0;
BA_ "GenSigSendType" SG_ 1162 MO8_Spoiler_ausf 0;
BA_ "GenSigAutoGenSnd" SG_ 1162 MO8_Spoiler_ausf 1;
BA_ "GenSigAutoGenDsp" SG_ 1162 MO8_Spoiler_ausf 1;
BA_ "GenSigSwitchedByIgnition" SG_ 1162 MO8_Sportschalter 0;
BA_ "GenSigSendType" SG_ 1162 MO8_Sportschalter 0;
BA_ "GenSigAutoGenSnd" SG_ 1162 MO8_Sportschalter 1;
BA_ "GenSigAutoGenDsp" SG_ 1162 MO8_Sportschalter 1;
BA_ "GenSigSwitchedByIgnition" SG_ 1162 MO8_LampeDZBegr 0;
BA_ "GenSigSendType" SG_ 1162 MO8_LampeDZBegr 0;
BA_ "GenSigAutoGenSnd" SG_ 1162 MO8_LampeDZBegr 1;
BA_ "GenSigAutoGenDsp" SG_ 1162 MO8_LampeDZBegr 1;
BA_ "GenSigSwitchedByIgnition" SG_ 1162 MO8_Enable_Oeldr_Motor 0;
BA_ "GenSigSendType" SG_ 1162 MO8_Enable_Oeldr_Motor 0;
BA_ "GenSigAutoGenSnd" SG_ 1162 MO8_Enable_Oeldr_Motor 1;
BA_ "GenSigAutoGenDsp" SG_ 1162 MO8_Enable_Oeldr_Motor 1;
BA_ "GenSigSwitchedByIgnition" SG_ 1162 MO8_Oeldr_Warn_Motor 0;
BA_ "GenSigSendType" SG_ 1162 MO8_Oeldr_Warn_Motor 0;
BA_ "GenSigAutoGenSnd" SG_ 1162 MO8_Oeldr_Warn_Motor 1;
BA_ "GenSigAutoGenDsp" SG_ 1162 MO8_Oeldr_Warn_Motor 1;
BA_ "GenSigSwitchedByIgnition" SG_ 1162 MO8_Avus_Motorschutz 0;
BA_ "GenSigSendType" SG_ 1162 MO8_Avus_Motorschutz 0;
BA_ "GenSigAutoGenSnd" SG_ 1162 MO8_Avus_Motorschutz 1;
BA_ "GenSigAutoGenDsp" SG_ 1162 MO8_Avus_Motorschutz 1;
BA_ "GenSigSwitchedByIgnition" SG_ 1162 MO8_GRA_v_Wunsch 0;
BA_ "GenSigSendType" SG_ 1162 MO8_GRA_v_Wunsch 0;
BA_ "GenSigAutoGenSnd" SG_ 1162 MO8_GRA_v_Wunsch 1;
BA_ "GenSigAutoGenDsp" SG_ 1162 MO8_GRA_v_Wunsch 1;
BA_ "GenSigSwitchedByIgnition" SG_ 1162 MO_Schaltempf_verfbar 0;
BA_ "GenSigFuncType" SG_ 1162 MO_Schaltempf_verfbar 8;
BA_ "GenSigSendType" SG_ 1162 MO_Schaltempf_verfbar 0;
BA_ "GenSigSwitchedByIgnition" SG_ 1162 MO8_Nachlauf_ZWP 0;
BA_ "GenSigSendType" SG_ 1162 MO8_Nachlauf_ZWP 0;
BA_ "GenSigAutoGenSnd" SG_ 1162 MO8_Nachlauf_ZWP 1;
BA_ "GenSigAutoGenDsp" SG_ 1162 MO8_Nachlauf_ZWP 1;
BA_ "GenSigSwitchedByIgnition" SG_ 1162 MO_Istgang 0;
BA_ "GenSigSendType" SG_ 1162 MO_Istgang 0;
BA_ "GenSigSwitchedByIgnition" SG_ 1162 MO_Sollgang 0;
BA_ "GenSigSendType" SG_ 1162 MO_Sollgang 0;
BA_ "GenSigSwitchedByIgnition" SG_ 1162 MO8_Zaehler 0;
BA_ "GenSigFuncType" SG_ 1162 MO8_Zaehler 1;
BA_ "GenSigSendType" SG_ 1162 MO8_Zaehler 0;
BA_ "GenSigAutoGenSnd" SG_ 1162 MO8_Zaehler 1;
BA_ "GenSigAutoGenDsp" SG_ 1162 MO8_Zaehler 1;
BA_ "GenSigSwitchedByIgnition" SG_ 644 MOB_Checksum 0;
BA_ "GenSigFuncType" SG_ 644 MOB_Checksum 4;
BA_ "GenSigSendType" SG_ 644 MOB_Checksum 0;
BA_ "GenSigAutoGenSnd" SG_ 644 MOB_Checksum 1;
BA_ "GenSigAutoGenDsp" SG_ 644 MOB_Checksum 1;
BA_ "GenSigSwitchedByIgnition" SG_ 644 MOB_Zaehler 0;
BA_ "GenSigFuncType" SG_ 644 MOB_Zaehler 1;
BA_ "GenSigSendType" SG_ 644 MOB_Zaehler 0;
BA_ "GenSigAutoGenSnd" SG_ 644 MOB_Zaehler 1;
BA_ "GenSigAutoGenDsp" SG_ 644 MOB_Zaehler 1;
BA_ "GenSigSwitchedByIgnition" SG_ 644 MOB_Standby 0;
BA_ "GenSigSendType" SG_ 644 MOB_Standby 0;
BA_ "GenSigAutoGenSnd" SG_ 644 MOB_Standby 1;
BA_ "GenSigAutoGenDsp" SG_ 644 MOB_Standby 1;
BA_ "GenSigSwitchedByIgnition" SG_ 644 MOB_Anhaltewunsch 0;
BA_ "GenSigSendType" SG_ 644 MOB_Anhaltewunsch 0;
BA_ "GenSigAutoGenSnd" SG_ 644 MOB_Anhaltewunsch 1;
BA_ "GenSigAutoGenDsp" SG_ 644 MOB_Anhaltewunsch 1;
BA_ "GenSigSwitchedByIgnition" SG_ 644 MOB_Freigabe 0;
BA_ "GenSigSendType" SG_ 644 MOB_Freigabe 0;
BA_ "GenSigAutoGenSnd" SG_ 644 MOB_Freigabe 1;
BA_ "GenSigAutoGenDsp" SG_ 644 MOB_Freigabe 1;
BA_ "GenSigSwitchedByIgnition" SG_ 644 MOB_Bremsstgr 0;
BA_ "GenSigSendType" SG_ 644 MOB_Bremsstgr 0;
BA_ "GenSigAutoGenSnd" SG_ 644 MOB_Bremsstgr 1;
BA_ "GenSigAutoGenDsp" SG_ 644 MOB_Bremsstgr 1;
BA_ "Fehlerwert" SG_ 644 MOB_Bremsmom 8191;
BA_ "GenSigSwitchedByIgnition" SG_ 644 MOB_Bremsmom 0;
BA_ "GenSigSendType" SG_ 644 MOB_Bremsmom 0;
BA_ "GenSigAutoGenSnd" SG_ 644 MOB_Bremsmom 1;
BA_ "GenSigAutoGenDsp" SG_ 644 MOB_Bremsmom 1;
BA_ "GenSigSwitchedByIgnition" SG_ 1800 MC1_Anz_Betrieb 0;
BA_ "GenSigSendType" SG_ 1800 MC1_Anz_Betrieb 0;
BA_ "GenSigAutoGenSnd" SG_ 1800 MC1_Anz_Betrieb 1;
BA_ "GenSigAutoGenDsp" SG_ 1800 MC1_Anz_Betrieb 1;
BA_ "GenSigSwitchedByIgnition" SG_ 1800 MC1_Schalter 0;
BA_ "GenSigSendType" SG_ 1800 MC1_Schalter 0;
BA_ "GenSigAutoGenSnd" SG_ 1800 MC1_Schalter 1;
BA_ "GenSigAutoGenDsp" SG_ 1800 MC1_Schalter 1;
BA_ "GenSigSwitchedByIgnition" SG_ 1800 MC1_akt_Betrieb 0;
BA_ "GenSigSendType" SG_ 1800 MC1_akt_Betrieb 0;
BA_ "GenSigAutoGenSnd" SG_ 1800 MC1_akt_Betrieb 1;
BA_ "GenSigAutoGenDsp" SG_ 1800 MC1_akt_Betrieb 1;
BA_ "GenSigSwitchedByIgnition" SG_ 1800 MC1_CNG_LPG 0;
BA_ "GenSigSendType" SG_ 1800 MC1_CNG_LPG 0;
BA_ "GenSigAutoGenSnd" SG_ 1800 MC1_CNG_LPG 1;
BA_ "GenSigAutoGenDsp" SG_ 1800 MC1_CNG_LPG 1;
BA_ "GenSigSwitchedByIgnition" SG_ 1800 MO_LPG_Tankstopp 0;
BA_ "GenSigAutoGenSnd" SG_ 1800 MO_LPG_Tankstopp 1;
BA_ "GenSigAutoGenDsp" SG_ 1800 MO_LPG_Tankstopp 1;
BA_ "GenSigSwitchedByIgnition" SG_ 1800 MO_Erdgasqualitaet 0;
BA_ "GenSigSendType" SG_ 1800 MO_Erdgasqualitaet 0;
BA_ "Fehlerwert" SG_ 1800 MC1_Fuellungsgrad 255;
BA_ "GenSigSwitchedByIgnition" SG_ 1800 MC1_Fuellungsgrad 0;
BA_ "GenSigSendType" SG_ 1800 MC1_Fuellungsgrad 0;
BA_ "GenSigAutoGenSnd" SG_ 1800 MC1_Fuellungsgrad 1;
BA_ "GenSigAutoGenDsp" SG_ 1800 MC1_Fuellungsgrad 1;
BA_ "GenSigSwitchedByIgnition" SG_ 1800 MC1_Verbrauch 0;
BA_ "GenSigAutoGenSnd" SG_ 1800 MC1_Verbrauch 1;
BA_ "GenSigAutoGenDsp" SG_ 1800 MC1_Verbrauch 1;
BA_ "GenSigSwitchedByIgnition" SG_ 1800 MC1_Verbrauch_LPG 0;
BA_ "GenSigAutoGenSnd" SG_ 1800 MC1_Verbrauch_LPG 1;
BA_ "GenSigAutoGenDsp" SG_ 1800 MC1_Verbrauch_LPG 1;
BA_ "GenSigSwitchedByIgnition" SG_ 1800 MC1_Ueb_Verbr 0;
BA_ "GenSigSendType" SG_ 1800 MC1_Ueb_Verbr 0;
BA_ "GenSigAutoGenSnd" SG_ 1800 MC1_Ueb_Verbr 1;
BA_ "GenSigAutoGenDsp" SG_ 1800 MC1_Ueb_Verbr 1;
BA_ "GenSigSwitchedByIgnition" SG_ 1800 MO_AnzeigeGasbetrieb 0;
BA_ "GenSigSendType" SG_ 1800 MO_AnzeigeGasbetrieb 0;
BA_ "GenSigSwitchedByIgnition" SG_ 1408 MFN_Zaehler 0;
BA_ "GenSigSendType" SG_ 1408 MFN_Zaehler 0;
BA_ "GenSigAutoGenSnd" SG_ 1408 MFN_Zaehler 1;
BA_ "GenSigAutoGenDsp" SG_ 1408 MFN_Zaehler 1;
BA_ "GenSigSwitchedByIgnition" SG_ 1408 MFN_Zaehler_ 0;
BA_ "GenSigSendType" SG_ 1408 MFN_Zaehler_ 0;
BA_ "GenSigAutoGenSnd" SG_ 1408 MFN_Zaehler_ 1;
BA_ "GenSigAutoGenDsp" SG_ 1408 MFN_Zaehler_ 1;
BA_ "GenSigSwitchedByIgnition" SG_ 1408 MFN_Drive_Cycle 0;
BA_ "GenSigSendType" SG_ 1408 MFN_Drive_Cycle 0;
BA_ "GenSigAutoGenSnd" SG_ 1408 MFN_Drive_Cycle 1;
BA_ "GenSigAutoGenDsp" SG_ 1408 MFN_Drive_Cycle 1;
BA_ "GenSigSwitchedByIgnition" SG_ 1408 MFN_Warmup_Cycle 0;
BA_ "GenSigSendType" SG_ 1408 MFN_Warmup_Cycle 0;
BA_ "GenSigAutoGenSnd" SG_ 1408 MFN_Warmup_Cycle 1;
BA_ "GenSigAutoGenDsp" SG_ 1408 MFN_Warmup_Cycle 1;
BA_ "GenSigSwitchedByIgnition" SG_ 1408 MFN_NormedTrip 0;
BA_ "GenSigSendType" SG_ 1408 MFN_NormedTrip 0;
BA_ "GenSigAutoGenSnd" SG_ 1408 MFN_NormedTrip 1;
BA_ "GenSigAutoGenDsp" SG_ 1408 MFN_NormedTrip 1;
BA_ "GenSigSwitchedByIgnition" SG_ 1408 MFN_Verbrenn_Typ 0;
BA_ "GenSigSendType" SG_ 1408 MFN_Verbrenn_Typ 0;
BA_ "GenSigAutoGenSnd" SG_ 1408 MFN_Verbrenn_Typ 1;
BA_ "GenSigAutoGenDsp" SG_ 1408 MFN_Verbrenn_Typ 1;
BA_ "Fehlerwert" SG_ 1408 MFN_Russindex 65535;
BA_ "GenSigSwitchedByIgnition" SG_ 1408 MFN_Russindex 0;
BA_ "GenSigAutoGenSnd" SG_ 1408 MFN_Russindex 1;
BA_ "GenSigAutoGenDsp" SG_ 1408 MFN_Russindex 1;
BA_ "Fehlerwert" SG_ 1408 MFN_Verschl 65535;
BA_ "GenSigSwitchedByIgnition" SG_ 1408 MFN_Verschl 0;
BA_ "GenSigAutoGenSnd" SG_ 1408 MFN_Verschl 1;
BA_ "GenSigAutoGenDsp" SG_ 1408 MFN_Verschl 1;
BA_ "Fehlerwert" SG_ 1408 MFN_Russindex_ 65535;
BA_ "GenSigSwitchedByIgnition" SG_ 1408 MFN_Russindex_ 0;
BA_ "GenSigAutoGenSnd" SG_ 1408 MFN_Russindex_ 1;
BA_ "GenSigAutoGenDsp" SG_ 1408 MFN_Russindex_ 1;
BA_ "Fehlerwert" SG_ 1408 MFN_Verschl_ 65535;
BA_ "GenSigSwitchedByIgnition" SG_ 1408 MFN_Verschl_ 0;
BA_ "GenSigAutoGenSnd" SG_ 1408 MFN_Verschl_ 1;
BA_ "GenSigAutoGenDsp" SG_ 1408 MFN_Verschl_ 1;
BA_ "GenSigSwitchedByIgnition" SG_ 1408 MFN_Drz_max_Mo 0;
BA_ "GenSigAutoGenSnd" SG_ 1408 MFN_Drz_max_Mo 1;
BA_ "GenSigAutoGenDsp" SG_ 1408 MFN_Drz_max_Mo 1;
BA_ "Fehlerwert" SG_ 1408 MFN_KurzzeitMW 255;
BA_ "GenSigSwitchedByIgnition" SG_ 1408 MFN_KurzzeitMW 0;
BA_ "GenSigAutoGenSnd" SG_ 1408 MFN_KurzzeitMW 1;
BA_ "GenSigAutoGenDsp" SG_ 1408 MFN_KurzzeitMW 1;
BA_ "GenSigSwitchedByIgnition" SG_ 1408 MFN_Drz_max_Mo_ 0;
BA_ "GenSigAutoGenSnd" SG_ 1408 MFN_Drz_max_Mo_ 1;
BA_ "GenSigAutoGenDsp" SG_ 1408 MFN_Drz_max_Mo_ 1;
BA_ "GenSigSwitchedByIgnition" SG_ 1408 MFN_Interv_Wmin 0;
BA_ "GenSigAutoGenSnd" SG_ 1408 MFN_Interv_Wmin 1;
BA_ "GenSigAutoGenDsp" SG_ 1408 MFN_Interv_Wmin 1;
BA_ "GenSigSwitchedByIgnition" SG_ 1408 MFN_Fuell_Erk 0;
BA_ "GenSigAutoGenSnd" SG_ 1408 MFN_Fuell_Erk 1;
BA_ "GenSigAutoGenDsp" SG_ 1408 MFN_Fuell_Erk 1;
BA_ "GenSigSwitchedByIgnition" SG_ 1408 MFN_max_Moment 0;
BA_ "GenSigAutoGenSnd" SG_ 1408 MFN_max_Moment 1;
BA_ "GenSigAutoGenDsp" SG_ 1408 MFN_max_Moment 1;
BA_ "GenSigSwitchedByIgnition" SG_ 1408 MFN_Oelstand 0;
BA_ "GenSigAutoGenSnd" SG_ 1408 MFN_Oelstand 1;
BA_ "GenSigAutoGenDsp" SG_ 1408 MFN_Oelstand 1;
BA_ "GenSigSwitchedByIgnition" SG_ 1408 MFN_max_Moment_ 0;
BA_ "GenSigAutoGenSnd" SG_ 1408 MFN_max_Moment_ 1;
BA_ "GenSigAutoGenDsp" SG_ 1408 MFN_max_Moment_ 1;
BA_ "GenSigSwitchedByIgnition" SG_ 1408 MFN_Interv_Wmax 0;
BA_ "GenSigAutoGenSnd" SG_ 1408 MFN_Interv_Wmax 1;
BA_ "GenSigAutoGenDsp" SG_ 1408 MFN_Interv_Wmax 1;
BA_ "GenSigSwitchedByIgnition" SG_ 1408 MFN_Oelwarnung 0;
BA_ "GenSigAutoGenSnd" SG_ 1408 MFN_Oelwarnung 1;
BA_ "GenSigAutoGenDsp" SG_ 1408 MFN_Oelwarnung 1;
BA_ "GenSigSwitchedByIgnition" SG_ 1408 MFN_Sensorwarn 0;
BA_ "GenSigAutoGenSnd" SG_ 1408 MFN_Sensorwarn 1;
BA_ "GenSigAutoGenDsp" SG_ 1408 MFN_Sensorwarn 1;
BA_ "GenSigSwitchedByIgnition" SG_ 1408 MFN_MaxOelst 0;
BA_ "GenSigAutoGenSnd" SG_ 1408 MFN_MaxOelst 1;
BA_ "GenSigAutoGenDsp" SG_ 1408 MFN_MaxOelst 1;
BA_ "GenSigSwitchedByIgnition" SG_ 1408 MFN_Motorleistung 0;
BA_ "GenSigAutoGenSnd" SG_ 1408 MFN_Motorleistung 1;
BA_ "GenSigAutoGenDsp" SG_ 1408 MFN_Motorleistung 1;
BA_ "GenSigSwitchedByIgnition" SG_ 1408 MFN_AnzMitOel 0;
BA_ "GenSigAutoGenSnd" SG_ 1408 MFN_AnzMitOel 1;
BA_ "GenSigAutoGenDsp" SG_ 1408 MFN_AnzMitOel 1;
BA_ "GenSigSwitchedByIgnition" SG_ 1408 MFN_Motorleistung_ 0;
BA_ "GenSigAutoGenSnd" SG_ 1408 MFN_Motorleistung_ 1;
BA_ "GenSigAutoGenDsp" SG_ 1408 MFN_Motorleistung_ 1;
BA_ "GenSigSwitchedByIgnition" SG_ 1408 MFN_Max_Offset 0;
BA_ "GenSigAutoGenSnd" SG_ 1408 MFN_Max_Offset 1;
BA_ "GenSigAutoGenDsp" SG_ 1408 MFN_Max_Offset 1;
BA_ "GenSigSwitchedByIgnition" SG_ 1408 MFN_Anz_Mittel 0;
BA_ "GenSigAutoGenSnd" SG_ 1408 MFN_Anz_Mittel 1;
BA_ "GenSigAutoGenDsp" SG_ 1408 MFN_Anz_Mittel 1;
BA_ "GenSigSwitchedByIgnition" SG_ 1408 MFN_Fuell_Hyst 0;
BA_ "GenSigAutoGenSnd" SG_ 1408 MFN_Fuell_Hyst 1;
BA_ "GenSigAutoGenDsp" SG_ 1408 MFN_Fuell_Hyst 1;
BA_ "GenSigSwitchedByIgnition" SG_ 1408 MFN_Interv_tmin 0;
BA_ "GenSigAutoGenSnd" SG_ 1408 MFN_Interv_tmin 1;
BA_ "GenSigAutoGenDsp" SG_ 1408 MFN_Interv_tmin 1;
BA_ "GenSigSwitchedByIgnition" SG_ 1408 MFN_Ventile 0;
BA_ "GenSigAutoGenSnd" SG_ 1408 MFN_Ventile 1;
BA_ "GenSigAutoGenDsp" SG_ 1408 MFN_Ventile 1;
BA_ "GenSigSwitchedByIgnition" SG_ 1408 MFN_Ventile_ 0;
BA_ "GenSigAutoGenSnd" SG_ 1408 MFN_Ventile_ 1;
BA_ "GenSigAutoGenDsp" SG_ 1408 MFN_Ventile_ 1;
BA_ "GenSigSwitchedByIgnition" SG_ 1408 MFN_Zylinder 0;
BA_ "GenSigAutoGenSnd" SG_ 1408 MFN_Zylinder 1;
BA_ "GenSigAutoGenDsp" SG_ 1408 MFN_Zylinder 1;
BA_ "GenSigSwitchedByIgnition" SG_ 1408 MFN_Offset_Nachf 0;
BA_ "GenSigAutoGenSnd" SG_ 1408 MFN_Offset_Nachf 1;
BA_ "GenSigAutoGenDsp" SG_ 1408 MFN_Offset_Nachf 1;
BA_ "GenSigSwitchedByIgnition" SG_ 1408 MFN_Zylinder_ 0;
BA_ "GenSigAutoGenSnd" SG_ 1408 MFN_Zylinder_ 1;
BA_ "GenSigAutoGenDsp" SG_ 1408 MFN_Zylinder_ 1;
BA_ "GenSigSwitchedByIgnition" SG_ 1408 MFN_Interv_tmax 0;
BA_ "GenSigAutoGenSnd" SG_ 1408 MFN_Interv_tmax 1;
BA_ "GenSigAutoGenDsp" SG_ 1408 MFN_Interv_tmax 1;
BA_ "GenSigSwitchedByIgnition" SG_ 1408 MFN_Hubraum 0;
BA_ "GenSigAutoGenSnd" SG_ 1408 MFN_Hubraum 1;
BA_ "GenSigAutoGenDsp" SG_ 1408 MFN_Hubraum 1;
BA_ "GenSigSwitchedByIgnition" SG_ 1408 MFN_Hubraum_ 0;
BA_ "GenSigAutoGenSnd" SG_ 1408 MFN_Hubraum_ 1;
BA_ "GenSigAutoGenDsp" SG_ 1408 MFN_Hubraum_ 1;
BA_ "GenSigSwitchedByIgnition" SG_ 1408 MFN_Tol_Oelwarn 0;
BA_ "GenSigAutoGenSnd" SG_ 1408 MFN_Tol_Oelwarn 1;
BA_ "GenSigAutoGenDsp" SG_ 1408 MFN_Tol_Oelwarn 1;
BA_ "GenSigSwitchedByIgnition" SG_ 1408 MFN_Str_Mittel 0;
BA_ "GenSigAutoGenSnd" SG_ 1408 MFN_Str_Mittel 1;
BA_ "GenSigAutoGenDsp" SG_ 1408 MFN_Str_Mittel 1;
BA_ "GenSigSwitchedByIgnition" SG_ 1408 MFN_Ansaugsys 0;
BA_ "GenSigAutoGenSnd" SG_ 1408 MFN_Ansaugsys 1;
BA_ "GenSigAutoGenDsp" SG_ 1408 MFN_Ansaugsys 1;
BA_ "GenSigSwitchedByIgnition" SG_ 1408 MFN_Ansaugsys_ 0;
BA_ "GenSigAutoGenSnd" SG_ 1408 MFN_Ansaugsys_ 1;
BA_ "GenSigAutoGenDsp" SG_ 1408 MFN_Ansaugsys_ 1;
BA_ "Fehlerwert" SG_ 1154 MH1_VM_Mom_oE 255;
BA_ "GenSigSwitchedByIgnition" SG_ 1154 MH1_VM_Mom_oE 0;
BA_ "GenSigStartValue" SG_ 1154 MH1_VM_Mom_oE 125;
BA_ "GenSigSendType" SG_ 1154 MH1_VM_Mom_oE 0;
BA_ "GenSigAutoGenSnd" SG_ 1154 MH1_VM_Mom_oE 1;
BA_ "GenSigAutoGenDsp" SG_ 1154 MH1_VM_Mom_oE 1;
BA_ "Fehlerwert" SG_ 1154 MH1_IstStatusK0 3;
BA_ "GenSigSendType" SG_ 1154 MH1_IstStatusK0 0;
BA_ "GenSigAutoGenSnd" SG_ 1154 MH1_IstStatusK0 1;
BA_ "GenSigAutoGenDsp" SG_ 1154 MH1_IstStatusK0 1;
BA_ "GenSigSendType" SG_ 1154 MH1_Startmodus_PQ35 0;
BA_ "GenSigAutoGenSnd" SG_ 1154 MH1_Startmodus_PQ35 1;
BA_ "GenSigAutoGenDsp" SG_ 1154 MH1_Startmodus_PQ35 1;
BA_ "GenSigSendType" SG_ 1154 MH1_VM_aktiv 0;
BA_ "GenSigAutoGenSnd" SG_ 1154 MH1_VM_aktiv 1;
BA_ "GenSigAutoGenDsp" SG_ 1154 MH1_VM_aktiv 1;
BA_ "Fehlerwert" SG_ 1154 MH1_Zielzustand_Hybrid 7;
BA_ "GenSigSendType" SG_ 1154 MH1_Zielzustand_Hybrid 0;
BA_ "GenSigAutoGenSnd" SG_ 1154 MH1_Zielzustand_Hybrid 1;
BA_ "GenSigAutoGenDsp" SG_ 1154 MH1_Zielzustand_Hybrid 1;
BA_ "GenSigSendType" SG_ 1154 MH1_Schaltverh 0;
BA_ "GenSigAutoGenSnd" SG_ 1154 MH1_Schaltverh 1;
BA_ "GenSigAutoGenDsp" SG_ 1154 MH1_Schaltverh 1;
BA_ "GenSigAutoGenSnd" SG_ 1154 MH1_VerlParam_Msum 1;
BA_ "GenSigAutoGenDsp" SG_ 1154 MH1_VerlParam_Msum 1;
BA_ "GenSigAutoGenSnd" SG_ 1154 MH1_MomVerlauf_EM 1;
BA_ "GenSigAutoGenDsp" SG_ 1154 MH1_MomVerlauf_EM 1;
BA_ "GenSigAutoGenSnd" SG_ 1154 MH1_E_Faktor 1;
BA_ "GenSigAutoGenDsp" SG_ 1154 MH1_E_Faktor 1;
BA_ "Fehlerwert" SG_ 1154 MH1_Drehzahl_VM 65280;
BA_ "GenSigSendType" SG_ 1154 MH1_Drehzahl_VM 0;
BA_ "GenSigAutoGenSnd" SG_ 1154 MH1_Drehzahl_VM 1;
BA_ "GenSigAutoGenDsp" SG_ 1154 MH1_Drehzahl_VM 1;
BA_ "Fehlerwert" SG_ 1154 MH1_max_ind_VM_Mom 255;
BA_ "GenSigStartValue" SG_ 1154 MH1_max_ind_VM_Mom 254;
BA_ "GenSigSendType" SG_ 1154 MH1_max_ind_VM_Mom 0;
BA_ "GenSigAutoGenSnd" SG_ 1154 MH1_max_ind_VM_Mom 1;
BA_ "GenSigAutoGenDsp" SG_ 1154 MH1_max_ind_VM_Mom 1;
BA_ "GenSigSendType" SG_ 1154 MH1_Startmodus_PL71 0;
BA_ "GenSigAutoGenSnd" SG_ 1154 MH1_Startmodus_PL71 1;
BA_ "GenSigAutoGenDsp" SG_ 1154 MH1_Startmodus_PL71 1;
BA_ "GenSigSendType" SG_ 1154 MH1_LowSpeedModus 0;
BA_ "GenSigAutoGenSnd" SG_ 1154 MH1_LowSpeedModus 1;
BA_ "GenSigAutoGenDsp" SG_ 1154 MH1_LowSpeedModus 1;
BA_ "GenSigSendType" SG_ 1154 MH1_ACCGRA_aktiv 0;
BA_ "GenSigAutoGenSnd" SG_ 1154 MH1_ACCGRA_aktiv 1;
BA_ "GenSigAutoGenDsp" SG_ 1154 MH1_ACCGRA_aktiv 1;
BA_ "GenSigStartValue" SG_ 1154 MH1_QB_Bremspedalwert 1;
BA_ "GenSigSendType" SG_ 1154 MH1_QB_Bremspedalwert 0;
BA_ "GenSigAutoGenSnd" SG_ 1154 MH1_QB_Bremspedalwert 1;
BA_ "GenSigAutoGenDsp" SG_ 1154 MH1_QB_Bremspedalwert 1;
BA_ "Fehlerwert" SG_ 1154 MH1_Bremspedalwert 255;
BA_ "GenSigSendType" SG_ 1154 MH1_Bremspedalwert 0;
BA_ "GenSigAutoGenSnd" SG_ 1154 MH1_Bremspedalwert 1;
BA_ "GenSigAutoGenDsp" SG_ 1154 MH1_Bremspedalwert 1;
BA_ "GenSigSwitchedByIgnition" SG_ 399 Motor_LPG_01_Reserve 0;
BA_ "GenSigSendType" SG_ 399 Motor_LPG_01_Reserve 0;
BA_ "GenSigSwitchedByIgnition" SG_ 1823 MSI_KD_Fehler 0;
BA_ "GenSigSendType" SG_ 1823 MSI_KD_Fehler 0;
BA_ "GenSigAutoGenSnd" SG_ 1823 MSI_KD_Fehler 1;
BA_ "GenSigAutoGenDsp" SG_ 1823 MSI_KD_Fehler 1;
BA_ "GenSigFuncType" SG_ 1428 NI2_Checksum 4;
BA_ "GenSigSendType" SG_ 1428 NI2_Checksum 0;
BA_ "GenSigAutoGenSnd" SG_ 1428 NI2_Checksum 1;
BA_ "GenSigAutoGenDsp" SG_ 1428 NI2_Checksum 1;
BA_ "GenSigFuncType" SG_ 1428 NI2_Zaehler 1;
BA_ "GenSigSendType" SG_ 1428 NI2_Zaehler 0;
BA_ "GenSigAutoGenSnd" SG_ 1428 NI2_Zaehler 1;
BA_ "GenSigAutoGenDsp" SG_ 1428 NI2_Zaehler 1;
BA_ "GenSigSendType" SG_ 1428 NI2_Hoehenflag 0;
BA_ "GenSigAutoGenSnd" SG_ 1428 NI2_Hoehenflag 1;
BA_ "GenSigAutoGenDsp" SG_ 1428 NI2_Hoehenflag 1;
BA_ "Fehlerwert" SG_ 1428 NI2_Hoehe_VL 255;
BA_ "GenSigAutoGenSnd" SG_ 1428 NI2_Hoehe_VL 1;
BA_ "GenSigAutoGenDsp" SG_ 1428 NI2_Hoehe_VL 1;
BA_ "Fehlerwert" SG_ 1428 NI2_Hoehe_VL_Roh 255;
BA_ "GenSigStartValue" SG_ 1428 NI2_Hoehe_VL_Roh 254;
BA_ "GenSigAutoGenSnd" SG_ 1428 NI2_Hoehe_VL_Roh 1;
BA_ "GenSigAutoGenDsp" SG_ 1428 NI2_Hoehe_VL_Roh 1;
BA_ "Fehlerwert" SG_ 1428 NI2_Hoehe_VR 255;
BA_ "GenSigAutoGenSnd" SG_ 1428 NI2_Hoehe_VR 1;
BA_ "GenSigAutoGenDsp" SG_ 1428 NI2_Hoehe_VR 1;
BA_ "Fehlerwert" SG_ 1428 NI2_Hoehe_VR_Roh 255;
BA_ "GenSigStartValue" SG_ 1428 NI2_Hoehe_VR_Roh 254;
BA_ "GenSigAutoGenSnd" SG_ 1428 NI2_Hoehe_VR_Roh 1;
BA_ "GenSigAutoGenDsp" SG_ 1428 NI2_Hoehe_VR_Roh 1;
BA_ "Fehlerwert" SG_ 1428 NI2_Hoehe_HL 255;
BA_ "GenSigAutoGenSnd" SG_ 1428 NI2_Hoehe_HL 1;
BA_ "GenSigAutoGenDsp" SG_ 1428 NI2_Hoehe_HL 1;
BA_ "Fehlerwert" SG_ 1428 NI2_Hoehe_HL_Roh 255;
BA_ "GenSigStartValue" SG_ 1428 NI2_Hoehe_HL_Roh 254;
BA_ "GenSigAutoGenSnd" SG_ 1428 NI2_Hoehe_HL_Roh 1;
BA_ "GenSigAutoGenDsp" SG_ 1428 NI2_Hoehe_HL_Roh 1;
BA_ "Fehlerwert" SG_ 1428 NI2_Hoehe_HR 255;
BA_ "GenSigAutoGenSnd" SG_ 1428 NI2_Hoehe_HR 1;
BA_ "GenSigAutoGenDsp" SG_ 1428 NI2_Hoehe_HR 1;
BA_ "Fehlerwert" SG_ 1428 NI2_Hoehe_HR_Roh 255;
BA_ "GenSigStartValue" SG_ 1428 NI2_Hoehe_HR_Roh 254;
BA_ "GenSigAutoGenSnd" SG_ 1428 NI2_Hoehe_HR_Roh 1;
BA_ "GenSigAutoGenDsp" SG_ 1428 NI2_Hoehe_HR_Roh 1;
BA_ "Fehlerwert" SG_ 1428 NI2_AufbBeschl_VL 255;
BA_ "GenSigAutoGenSnd" SG_ 1428 NI2_AufbBeschl_VL 1;
BA_ "GenSigAutoGenDsp" SG_ 1428 NI2_AufbBeschl_VL 1;
BA_ "Fehlerwert" SG_ 1428 NI2_AufbBeschl_VR 255;
BA_ "GenSigAutoGenSnd" SG_ 1428 NI2_AufbBeschl_VR 1;
BA_ "GenSigAutoGenDsp" SG_ 1428 NI2_AufbBeschl_VR 1;
BA_ "GenSigSwitchedByIgnition" SG_ 1349 PA3_System_codierung 0;
BA_ "GenSigSendType" SG_ 1349 PA3_System_codierung 3;
BA_ "GenSigAutoGenSnd" SG_ 1349 PA3_System_codierung 1;
BA_ "GenSigAutoGenDsp" SG_ 1349 PA3_System_codierung 1;
BA_ "GenSigSwitchedByIgnition" SG_ 1349 PA3_Anlage_defekt 0;
BA_ "GenSigSendType" SG_ 1349 PA3_Anlage_defekt 3;
BA_ "GenSigAutoGenSnd" SG_ 1349 PA3_Anlage_defekt 1;
BA_ "GenSigAutoGenDsp" SG_ 1349 PA3_Anlage_defekt 1;
BA_ "GenSigSwitchedByIgnition" SG_ 1349 PA3_Taster_aktiviert 0;
BA_ "GenSigSendType" SG_ 1349 PA3_Taster_aktiviert 3;
BA_ "GenSigAutoGenSnd" SG_ 1349 PA3_Taster_aktiviert 1;
BA_ "GenSigAutoGenDsp" SG_ 1349 PA3_Taster_aktiviert 1;
BA_ "GenSigSwitchedByIgnition" SG_ 1349 PA3_Rueckwaertsgang_aktiv 0;
BA_ "GenSigSendType" SG_ 1349 PA3_Rueckwaertsgang_aktiv 3;
BA_ "GenSigAutoGenSnd" SG_ 1349 PA3_Rueckwaertsgang_aktiv 1;
BA_ "GenSigAutoGenDsp" SG_ 1349 PA3_Rueckwaertsgang_aktiv 1;
BA_ "GenSigSwitchedByIgnition" SG_ 1349 PA3_Geschwindigkeit_aus 0;
BA_ "GenSigSendType" SG_ 1349 PA3_Geschwindigkeit_aus 3;
BA_ "GenSigAutoGenSnd" SG_ 1349 PA3_Geschwindigkeit_aus 1;
BA_ "GenSigAutoGenDsp" SG_ 1349 PA3_Geschwindigkeit_aus 1;
BA_ "GenSigSwitchedByIgnition" SG_ 1349 PA3_Tongeber_v_defekt 0;
BA_ "GenSigSendType" SG_ 1349 PA3_Tongeber_v_defekt 3;
BA_ "GenSigAutoGenSnd" SG_ 1349 PA3_Tongeber_v_defekt 1;
BA_ "GenSigAutoGenDsp" SG_ 1349 PA3_Tongeber_v_defekt 1;
BA_ "GenSigSwitchedByIgnition" SG_ 1349 PA3_Tongeber_h_defekt 0;
BA_ "GenSigSendType" SG_ 1349 PA3_Tongeber_h_defekt 3;
BA_ "GenSigAutoGenSnd" SG_ 1349 PA3_Tongeber_h_defekt 1;
BA_ "GenSigAutoGenDsp" SG_ 1349 PA3_Tongeber_h_defekt 1;
BA_ "GenSigSwitchedByIgnition" SG_ 1349 PA3_Audioabsenkung_Anforderung 0;
BA_ "GenSigSendType" SG_ 1349 PA3_Audioabsenkung_Anforderung 3;
BA_ "GenSigAutoGenSnd" SG_ 1349 PA3_Audioabsenkung_Anforderung 1;
BA_ "GenSigAutoGenDsp" SG_ 1349 PA3_Audioabsenkung_Anforderung 1;
BA_ "GenSigSwitchedByIgnition" SG_ 1349 PA3_Eis_aus 0;
BA_ "GenSigSendType" SG_ 1349 PA3_Eis_aus 3;
BA_ "GenSigAutoGenSnd" SG_ 1349 PA3_Eis_aus 1;
BA_ "GenSigAutoGenDsp" SG_ 1349 PA3_Eis_aus 1;
BA_ "GenSigSwitchedByIgnition" SG_ 1349 PA3_Schlechtweg_aus 0;
BA_ "GenSigSendType" SG_ 1349 PA3_Schlechtweg_aus 3;
BA_ "GenSigAutoGenSnd" SG_ 1349 PA3_Schlechtweg_aus 1;
BA_ "GenSigAutoGenDsp" SG_ 1349 PA3_Schlechtweg_aus 1;
BA_ "GenSigSwitchedByIgnition" SG_ 1349 PA3_KD_Fehler 0;
BA_ "GenSigSendType" SG_ 1349 PA3_KD_Fehler 3;
BA_ "GenSigAutoGenSnd" SG_ 1349 PA3_KD_Fehler 1;
BA_ "GenSigAutoGenDsp" SG_ 1349 PA3_KD_Fehler 1;
BA_ "GenSigSwitchedByIgnition" SG_ 1349 PA3_Sensor_hll_defekt 0;
BA_ "GenSigSendType" SG_ 1349 PA3_Sensor_hll_defekt 3;
BA_ "GenSigAutoGenSnd" SG_ 1349 PA3_Sensor_hll_defekt 1;
BA_ "GenSigAutoGenDsp" SG_ 1349 PA3_Sensor_hll_defekt 1;
BA_ "GenSigSwitchedByIgnition" SG_ 1349 PA3_Sensor_hlm_defekt 0;
BA_ "GenSigSendType" SG_ 1349 PA3_Sensor_hlm_defekt 3;
BA_ "GenSigAutoGenSnd" SG_ 1349 PA3_Sensor_hlm_defekt 1;
BA_ "GenSigAutoGenDsp" SG_ 1349 PA3_Sensor_hlm_defekt 1;
BA_ "GenSigSwitchedByIgnition" SG_ 1349 PA3_Sensor_hrm_defekt 0;
BA_ "GenSigSendType" SG_ 1349 PA3_Sensor_hrm_defekt 3;
BA_ "GenSigAutoGenSnd" SG_ 1349 PA3_Sensor_hrm_defekt 1;
BA_ "GenSigAutoGenDsp" SG_ 1349 PA3_Sensor_hrm_defekt 1;
BA_ "GenSigSwitchedByIgnition" SG_ 1349 PA3_Sensor_hrr_defekt 0;
BA_ "GenSigSendType" SG_ 1349 PA3_Sensor_hrr_defekt 3;
BA_ "GenSigAutoGenSnd" SG_ 1349 PA3_Sensor_hrr_defekt 1;
BA_ "GenSigAutoGenDsp" SG_ 1349 PA3_Sensor_hrr_defekt 1;
BA_ "GenSigSwitchedByIgnition" SG_ 1349 PA3_Sensor_vll_defekt 0;
BA_ "GenSigSendType" SG_ 1349 PA3_Sensor_vll_defekt 3;
BA_ "GenSigAutoGenSnd" SG_ 1349 PA3_Sensor_vll_defekt 1;
BA_ "GenSigAutoGenDsp" SG_ 1349 PA3_Sensor_vll_defekt 1;
BA_ "GenSigSwitchedByIgnition" SG_ 1349 PA3_Sensor_vlm_defekt 0;
BA_ "GenSigSendType" SG_ 1349 PA3_Sensor_vlm_defekt 3;
BA_ "GenSigAutoGenSnd" SG_ 1349 PA3_Sensor_vlm_defekt 1;
BA_ "GenSigAutoGenDsp" SG_ 1349 PA3_Sensor_vlm_defekt 1;
BA_ "GenSigSwitchedByIgnition" SG_ 1349 PA3_Sensor_vrm_defekt 0;
BA_ "GenSigSendType" SG_ 1349 PA3_Sensor_vrm_defekt 3;
BA_ "GenSigAutoGenSnd" SG_ 1349 PA3_Sensor_vrm_defekt 1;
BA_ "GenSigAutoGenDsp" SG_ 1349 PA3_Sensor_vrm_defekt 1;
BA_ "GenSigSwitchedByIgnition" SG_ 1349 PA3_Sensor_vrr_defekt 0;
BA_ "GenSigSendType" SG_ 1349 PA3_Sensor_vrr_defekt 3;
BA_ "GenSigAutoGenSnd" SG_ 1349 PA3_Sensor_vrr_defekt 1;
BA_ "GenSigAutoGenDsp" SG_ 1349 PA3_Sensor_vrr_defekt 1;
BA_ "GenSigSwitchedByIgnition" SG_ 1349 PA3_Bereit 0;
BA_ "GenSigSendType" SG_ 1349 PA3_Bereit 3;
BA_ "GenSigAutoGenSnd" SG_ 1349 PA3_Bereit 1;
BA_ "GenSigAutoGenDsp" SG_ 1349 PA3_Bereit 1;
BA_ "GenSigSwitchedByIgnition" SG_ 1349 PA3_Bereich_vo 0;
BA_ "GenSigSendType" SG_ 1349 PA3_Bereich_vo 3;
BA_ "GenSigAutoGenSnd" SG_ 1349 PA3_Bereich_vo 1;
BA_ "GenSigAutoGenDsp" SG_ 1349 PA3_Bereich_vo 1;
BA_ "GenSigSwitchedByIgnition" SG_ 1349 PA3_Bereich_hi 0;
BA_ "GenSigSendType" SG_ 1349 PA3_Bereich_hi 3;
BA_ "GenSigAutoGenSnd" SG_ 1349 PA3_Bereich_hi 1;
BA_ "GenSigAutoGenDsp" SG_ 1349 PA3_Bereich_hi 1;
BA_ "GenSigSwitchedByIgnition" SG_ 1349 PA3_Akust_aus 0;
BA_ "GenSigSendType" SG_ 1349 PA3_Akust_aus 3;
BA_ "GenSigAutoGenSnd" SG_ 1349 PA3_Akust_aus 1;
BA_ "GenSigAutoGenDsp" SG_ 1349 PA3_Akust_aus 1;
BA_ "GenSigSwitchedByIgnition" SG_ 1349 PA3_Aufbau_erk 0;
BA_ "GenSigSendType" SG_ 1349 PA3_Aufbau_erk 3;
BA_ "GenSigAutoGenSnd" SG_ 1349 PA3_Aufbau_erk 1;
BA_ "GenSigAutoGenDsp" SG_ 1349 PA3_Aufbau_erk 1;
BA_ "GenSigStartValue" SG_ 1355 PA5_VL_Abstand 255;
BA_ "GenSigSendType" SG_ 1355 PA5_VL_Abstand 5;
BA_ "GenSigInactiveValue" SG_ 1355 PA5_VL_Abstand 255;
BA_ "GenSigAutoGenSnd" SG_ 1355 PA5_VL_Abstand 1;
BA_ "GenSigAutoGenDsp" SG_ 1355 PA5_VL_Abstand 1;
BA_ "GenSigStartValue" SG_ 1355 PA5_VR_Abstand 255;
BA_ "GenSigSendType" SG_ 1355 PA5_VR_Abstand 5;
BA_ "GenSigInactiveValue" SG_ 1355 PA5_VR_Abstand 255;
BA_ "GenSigAutoGenSnd" SG_ 1355 PA5_VR_Abstand 1;
BA_ "GenSigAutoGenDsp" SG_ 1355 PA5_VR_Abstand 1;
BA_ "GenSigStartValue" SG_ 1355 PA5_HL_Abstand 255;
BA_ "GenSigSendType" SG_ 1355 PA5_HL_Abstand 5;
BA_ "GenSigInactiveValue" SG_ 1355 PA5_HL_Abstand 255;
BA_ "GenSigAutoGenSnd" SG_ 1355 PA5_HL_Abstand 1;
BA_ "GenSigAutoGenDsp" SG_ 1355 PA5_HL_Abstand 1;
BA_ "GenSigStartValue" SG_ 1355 PA5_HR_Abstand 255;
BA_ "GenSigSendType" SG_ 1355 PA5_HR_Abstand 5;
BA_ "GenSigInactiveValue" SG_ 1355 PA5_HR_Abstand 255;
BA_ "GenSigAutoGenSnd" SG_ 1355 PA5_HR_Abstand 1;
BA_ "GenSigAutoGenDsp" SG_ 1355 PA5_HR_Abstand 1;
BA_ "GenSigStartValue" SG_ 1355 PA5_VML_Abstand 255;
BA_ "GenSigSendType" SG_ 1355 PA5_VML_Abstand 5;
BA_ "GenSigInactiveValue" SG_ 1355 PA5_VML_Abstand 255;
BA_ "GenSigAutoGenSnd" SG_ 1355 PA5_VML_Abstand 1;
BA_ "GenSigAutoGenDsp" SG_ 1355 PA5_VML_Abstand 1;
BA_ "GenSigStartValue" SG_ 1355 PA5_VMR_Abstand 255;
BA_ "GenSigSendType" SG_ 1355 PA5_VMR_Abstand 5;
BA_ "GenSigInactiveValue" SG_ 1355 PA5_VMR_Abstand 255;
BA_ "GenSigAutoGenSnd" SG_ 1355 PA5_VMR_Abstand 1;
BA_ "GenSigAutoGenDsp" SG_ 1355 PA5_VMR_Abstand 1;
BA_ "GenSigStartValue" SG_ 1355 PA5_HML_Abstand 255;
BA_ "GenSigSendType" SG_ 1355 PA5_HML_Abstand 5;
BA_ "GenSigInactiveValue" SG_ 1355 PA5_HML_Abstand 255;
BA_ "GenSigAutoGenSnd" SG_ 1355 PA5_HML_Abstand 1;
BA_ "GenSigAutoGenDsp" SG_ 1355 PA5_HML_Abstand 1;
BA_ "GenSigStartValue" SG_ 1355 PA5_HMR_Abstand 255;
BA_ "GenSigSendType" SG_ 1355 PA5_HMR_Abstand 5;
BA_ "GenSigInactiveValue" SG_ 1355 PA5_HMR_Abstand 255;
BA_ "GenSigAutoGenSnd" SG_ 1355 PA5_HMR_Abstand 1;
BA_ "GenSigAutoGenDsp" SG_ 1355 PA5_HMR_Abstand 1;
BA_ "GenSigSendType" SG_ 980 PL1_Checksumme 0;
BA_ "GenSigAutoGenSnd" SG_ 980 PL1_Checksumme 1;
BA_ "GenSigAutoGenDsp" SG_ 980 PL1_Checksumme 1;
BA_ "GenSigFuncType" SG_ 980 PL1_Zaehler 1;
BA_ "GenSigSendType" SG_ 980 PL1_Zaehler 0;
BA_ "GenSigAutoGenSnd" SG_ 980 PL1_Zaehler 1;
BA_ "GenSigAutoGenDsp" SG_ 980 PL1_Zaehler 1;
BA_ "GenSigSendType" SG_ 980 PL1_Stat_PLA_EPS 0;
BA_ "GenSigAutoGenSnd" SG_ 980 PL1_Stat_PLA_EPS 1;
BA_ "GenSigAutoGenDsp" SG_ 980 PL1_Stat_PLA_EPS 1;
BA_ "GenSigSendType" SG_ 980 PL1_LW_Soll 0;
BA_ "GenSigAutoGenSnd" SG_ 980 PL1_LW_Soll 1;
BA_ "GenSigAutoGenDsp" SG_ 980 PL1_LW_Soll 1;
BA_ "GenSigSendType" SG_ 980 PL1_LW_Soll_Sign 0;
BA_ "GenSigAutoGenSnd" SG_ 980 PL1_LW_Soll_Sign 1;
BA_ "GenSigAutoGenDsp" SG_ 980 PL1_LW_Soll_Sign 1;
BA_ "GenSigSendType" SG_ 980 PL1_Stat_PLA_ESP 0;
BA_ "Fehlerwert" SG_ 980 PL1_Bremsmoment 8191;
BA_ "GenSigSendType" SG_ 980 PL1_Bremsmoment 0;
BA_ "GenSigSendType" SG_ 1494 PLS_Anf_Anz 0;
BA_ "GenSigAutoGenSnd" SG_ 1494 PLS_Anf_Anz 1;
BA_ "GenSigAutoGenDsp" SG_ 1494 PLS_Anf_Anz 1;
BA_ "GenSigSendType" SG_ 1494 PLS_Akustik1 0;
BA_ "GenSigAutoGenSnd" SG_ 1494 PLS_Akustik1 1;
BA_ "GenSigAutoGenDsp" SG_ 1494 PLS_Akustik1 1;
BA_ "GenSigSendType" SG_ 1494 PLS_PL_Exist 0;
BA_ "GenSigAutoGenSnd" SG_ 1494 PLS_PL_Exist 1;
BA_ "GenSigAutoGenDsp" SG_ 1494 PLS_PL_Exist 1;
BA_ "GenSigSendType" SG_ 1494 PLS_Akustik2 0;
BA_ "GenSigAutoGenSnd" SG_ 1494 PLS_Akustik2 1;
BA_ "GenSigAutoGenDsp" SG_ 1494 PLS_Akustik2 1;
BA_ "GenSigSendType" SG_ 1494 PLS_Mehrzg_Aktiv 0;
BA_ "GenSigAutoGenSnd" SG_ 1494 PLS_Mehrzg_Aktiv 1;
BA_ "GenSigAutoGenDsp" SG_ 1494 PLS_Mehrzg_Aktiv 1;
BA_ "GenSigSendType" SG_ 1494 PLS_Pos_OK 0;
BA_ "GenSigAutoGenSnd" SG_ 1494 PLS_Pos_OK 1;
BA_ "GenSigAutoGenDsp" SG_ 1494 PLS_Pos_OK 1;
BA_ "GenSigSendType" SG_ 1494 PLS_PL_Seite 0;
BA_ "GenSigAutoGenSnd" SG_ 1494 PLS_PL_Seite 1;
BA_ "GenSigAutoGenDsp" SG_ 1494 PLS_PL_Seite 1;
BA_ "GenSigSendType" SG_ 1494 PLS_Lenk_Aktiv_Hinweis 0;
BA_ "GenSigAutoGenSnd" SG_ 1494 PLS_Lenk_Aktiv_Hinweis 1;
BA_ "GenSigAutoGenDsp" SG_ 1494 PLS_Lenk_Aktiv_Hinweis 1;
BA_ "GenSigSendType" SG_ 1494 PLS_Meldungen 0;
BA_ "GenSigAutoGenSnd" SG_ 1494 PLS_Meldungen 1;
BA_ "GenSigAutoGenDsp" SG_ 1494 PLS_Meldungen 1;
BA_ "GenSigSendType" SG_ 1494 PLS_Fahrtrichtg_Mehrzg 0;
BA_ "GenSigAutoGenSnd" SG_ 1494 PLS_Fahrtrichtg_Mehrzg 1;
BA_ "GenSigAutoGenDsp" SG_ 1494 PLS_Fahrtrichtg_Mehrzg 1;
BA_ "GenSigSendType" SG_ 1494 PLS_Text_Multiplexer 0;
BA_ "GenSigAutoGenSnd" SG_ 1494 PLS_Text_Multiplexer 1;
BA_ "GenSigAutoGenDsp" SG_ 1494 PLS_Text_Multiplexer 1;
BA_ "GenSigSendType" SG_ 1494 PLS_Schwellpfeil_rel 0;
BA_ "GenSigSendType" SG_ 1494 PLS_Anf_Anz_Schwellpfeil 0;
BA_ "GenSigSendType" SG_ 1494 PLS_Laengs_Querluecke 0;
BA_ "GenSigSendType" SG_ 1494 PLS_Standby 0;
BA_ "GenSigSendType" SG_ 1494 PLS_Bremssymbol 0;
BA_ "GenSigSendType" SG_ 1494 PLS_Kurze_Luecke 0;
BA_ "GenSigSendType" SG_ 1494 PLS_Schwellpfeil_abs 0;
BA_ "GenSigSendType" SG_ 1494 PLS_Akustik 0;
BA_ "GenSigSendType" SG_ 1494 PLS_Ausparken_Aktiv 0;
BA_ "GenSigSendType" SG_ 1494 PLS_Bremsleuchte 0;
BA_ "GenSigSendType" SG_ 1494 PLS_Texte 0;
BA_ "GenSigAutoGenSnd" SG_ 1494 PLS_Texte 1;
BA_ "GenSigAutoGenDsp" SG_ 1494 PLS_Texte 1;
BA_ "Fehlerwert" SG_ 714 QS2_Ist_Wert 255;
BA_ "GenSigSendType" SG_ 714 QS2_Ist_Wert 0;
BA_ "GenSigAutoGenSnd" SG_ 714 QS2_Ist_Wert 1;
BA_ "GenSigAutoGenDsp" SG_ 714 QS2_Ist_Wert 1;
BA_ "Fehlerwert" SG_ 714 QS2_Soll_Wert 255;
BA_ "GenSigSendType" SG_ 714 QS2_Soll_Wert 0;
BA_ "GenSigAutoGenSnd" SG_ 714 QS2_Soll_Wert 1;
BA_ "GenSigAutoGenDsp" SG_ 714 QS2_Soll_Wert 1;
BA_ "GenSigSendType" SG_ 714 QS2_Status_VAQ 0;
BA_ "GenSigAutoGenSnd" SG_ 714 QS2_Status_VAQ 1;
BA_ "GenSigAutoGenDsp" SG_ 714 QS2_Status_VAQ 1;
BA_ "GenSigSendType" SG_ 714 QS2_Gleichlauf 0;
BA_ "GenSigAutoGenSnd" SG_ 714 QS2_Gleichlauf 1;
BA_ "GenSigAutoGenDsp" SG_ 714 QS2_Gleichlauf 1;
BA_ "Fehlerwert" SG_ 714 QS2_KD_Fehler 1;
BA_ "GenSigSendType" SG_ 714 QS2_KD_Fehler 0;
BA_ "GenSigAutoGenSnd" SG_ 714 QS2_KD_Fehler 1;
BA_ "GenSigAutoGenDsp" SG_ 714 QS2_KD_Fehler 1;
BA_ "GenSigSwitchedByIgnition" SG_ 1437 RSF_Tastencode_1 0;
BA_ "GenSigSendType" SG_ 1437 RSF_Tastencode_1 6;
BA_ "GenSigSwitchedByIgnition" SG_ 1437 RSF_Tastencode_2 0;
BA_ "GenSigSendType" SG_ 1437 RSF_Tastencode_2 6;
BA_ "GenSigSwitchedByIgnition" SG_ 1437 RSF_Tastencode_Maske 0;
BA_ "GenSigSendType" SG_ 1437 RSF_Tastencode_Maske 6;
BA_ "GenSigSwitchedByIgnition" SG_ 16 MSG1_WFS_RND 0;
BA_ "GenSigSendType" SG_ 16 MSG1_WFS_RND 3;
BA_ "GenSigAutoGenSnd" SG_ 16 MSG1_WFS_RND 1;
BA_ "GenSigAutoGenDsp" SG_ 16 MSG1_WFS_RND 1;
BA_ "GenSigSwitchedByIgnition" SG_ 16 MSG1_WFS_SIG_E 0;
BA_ "GenSigSendType" SG_ 16 MSG1_WFS_SIG_E 3;
BA_ "GenSigAutoGenSnd" SG_ 16 MSG1_WFS_SIG_E 1;
BA_ "GenSigAutoGenDsp" SG_ 16 MSG1_WFS_SIG_E 1;
BA_ "GenSigSwitchedByIgnition" SG_ 16 MSG1_WFS_P_Klasse 0;
BA_ "GenSigSendType" SG_ 16 MSG1_WFS_P_Klasse 3;
BA_ "GenSigSwitchedByIgnition" SG_ 20 MSG2_WFS_RND 0;
BA_ "GenSigSendType" SG_ 20 MSG2_WFS_RND 3;
BA_ "GenSigAutoGenSnd" SG_ 20 MSG2_WFS_RND 1;
BA_ "GenSigAutoGenDsp" SG_ 20 MSG2_WFS_RND 1;
BA_ "GenSigSwitchedByIgnition" SG_ 20 MSG2_WFS_SIG_E 0;
BA_ "GenSigSendType" SG_ 20 MSG2_WFS_SIG_E 3;
BA_ "GenSigAutoGenSnd" SG_ 20 MSG2_WFS_SIG_E 1;
BA_ "GenSigAutoGenDsp" SG_ 20 MSG2_WFS_SIG_E 1;
BA_ "GenSigSwitchedByIgnition" SG_ 20 MSG2_WFS_P_Klasse 0;
BA_ "GenSigSendType" SG_ 20 MSG2_WFS_P_Klasse 3;
BA_ "GenSigSwitchedByIgnition" SG_ 22 MSG3_WFS_RND 0;
BA_ "GenSigSendType" SG_ 22 MSG3_WFS_RND 3;
BA_ "GenSigAutoGenSnd" SG_ 22 MSG3_WFS_RND 1;
BA_ "GenSigAutoGenDsp" SG_ 22 MSG3_WFS_RND 1;
BA_ "GenSigSwitchedByIgnition" SG_ 22 MSG3_WFS_SIG_E 0;
BA_ "GenSigSendType" SG_ 22 MSG3_WFS_SIG_E 3;
BA_ "GenSigAutoGenSnd" SG_ 22 MSG3_WFS_SIG_E 1;
BA_ "GenSigAutoGenDsp" SG_ 22 MSG3_WFS_SIG_E 1;
BA_ "GenSigSwitchedByIgnition" SG_ 22 MSG3_WFS_P_Klasse 0;
BA_ "GenSigSendType" SG_ 22 MSG3_WFS_P_Klasse 3;
BA_ "GenSigSwitchedByIgnition" SG_ 24 MSG4_WFS_RND 0;
BA_ "GenSigSendType" SG_ 24 MSG4_WFS_RND 3;
BA_ "GenSigAutoGenSnd" SG_ 24 MSG4_WFS_RND 1;
BA_ "GenSigAutoGenDsp" SG_ 24 MSG4_WFS_RND 1;
BA_ "GenSigSwitchedByIgnition" SG_ 24 MSG4_WFS_SIG_E 0;
BA_ "GenSigSendType" SG_ 24 MSG4_WFS_SIG_E 3;
BA_ "GenSigAutoGenSnd" SG_ 24 MSG4_WFS_SIG_E 1;
BA_ "GenSigAutoGenDsp" SG_ 24 MSG4_WFS_SIG_E 1;
BA_ "GenSigSwitchedByIgnition" SG_ 24 MSG4_WFS_P_Klasse 0;
BA_ "GenSigSendType" SG_ 24 MSG4_WFS_P_Klasse 3;
BA_ "GenSigSwitchedByIgnition" SG_ 1500 VL1_Motor_SG 0;
BA_ "GenSigSendType" SG_ 1500 VL1_Motor_SG 0;
BA_ "GenSigAutoGenSnd" SG_ 1500 VL1_Motor_SG 1;
BA_ "GenSigAutoGenDsp" SG_ 1500 VL1_Motor_SG 1;
BA_ "GenSigSwitchedByIgnition" SG_ 1500 VL1_Getr_SG 0;
BA_ "GenSigSendType" SG_ 1500 VL1_Getr_SG 0;
BA_ "GenSigAutoGenSnd" SG_ 1500 VL1_Getr_SG 1;
BA_ "GenSigAutoGenDsp" SG_ 1500 VL1_Getr_SG 1;
BA_ "GenSigSwitchedByIgnition" SG_ 1500 VL1_ABS 0;
BA_ "GenSigSendType" SG_ 1500 VL1_ABS 0;
BA_ "GenSigAutoGenSnd" SG_ 1500 VL1_ABS 1;
BA_ "GenSigAutoGenDsp" SG_ 1500 VL1_ABS 1;
BA_ "GenSigSwitchedByIgnition" SG_ 1500 VL1_Kombi 0;
BA_ "GenSigSendType" SG_ 1500 VL1_Kombi 0;
BA_ "GenSigAutoGenSnd" SG_ 1500 VL1_Kombi 1;
BA_ "GenSigAutoGenDsp" SG_ 1500 VL1_Kombi 1;
BA_ "GenSigSwitchedByIgnition" SG_ 1500 VL1_LSM 0;
BA_ "GenSigSendType" SG_ 1500 VL1_LSM 0;
BA_ "GenSigAutoGenSnd" SG_ 1500 VL1_LSM 1;
BA_ "GenSigAutoGenDsp" SG_ 1500 VL1_LSM 1;
BA_ "GenSigSwitchedByIgnition" SG_ 1500 VL1_Airbag 0;
BA_ "GenSigSendType" SG_ 1500 VL1_Airbag 0;
BA_ "GenSigAutoGenSnd" SG_ 1500 VL1_Airbag 1;
BA_ "GenSigAutoGenDsp" SG_ 1500 VL1_Airbag 1;
BA_ "GenSigSwitchedByIgnition" SG_ 1500 VL1_Lenkhilfe 0;
BA_ "GenSigSendType" SG_ 1500 VL1_Lenkhilfe 0;
BA_ "GenSigAutoGenSnd" SG_ 1500 VL1_Lenkhilfe 1;
BA_ "GenSigAutoGenDsp" SG_ 1500 VL1_Lenkhilfe 1;
BA_ "GenSigSwitchedByIgnition" SG_ 1500 VL1_dyn_LWR 0;
BA_ "GenSigSendType" SG_ 1500 VL1_dyn_LWR 0;
BA_ "GenSigAutoGenSnd" SG_ 1500 VL1_dyn_LWR 1;
BA_ "GenSigAutoGenDsp" SG_ 1500 VL1_dyn_LWR 1;
BA_ "GenSigSwitchedByIgnition" SG_ 1500 VL1_res_08 0;
BA_ "GenSigSendType" SG_ 1500 VL1_res_08 0;
BA_ "GenSigAutoGenSnd" SG_ 1500 VL1_res_08 1;
BA_ "GenSigAutoGenDsp" SG_ 1500 VL1_res_08 1;
BA_ "GenSigSwitchedByIgnition" SG_ 1500 VL1_Allrad 0;
BA_ "GenSigSendType" SG_ 1500 VL1_Allrad 0;
BA_ "GenSigAutoGenSnd" SG_ 1500 VL1_Allrad 1;
BA_ "GenSigAutoGenDsp" SG_ 1500 VL1_Allrad 1;
BA_ "GenSigSwitchedByIgnition" SG_ 1500 VL1_ADR 0;
BA_ "GenSigSendType" SG_ 1500 VL1_ADR 0;
BA_ "GenSigAutoGenSnd" SG_ 1500 VL1_ADR 1;
BA_ "GenSigAutoGenDsp" SG_ 1500 VL1_ADR 1;
BA_ "GenSigSwitchedByIgnition" SG_ 1500 VL1_ADR_getrennt 0;
BA_ "GenSigSendType" SG_ 1500 VL1_ADR_getrennt 0;
BA_ "GenSigAutoGenSnd" SG_ 1500 VL1_ADR_getrennt 1;
BA_ "GenSigAutoGenDsp" SG_ 1500 VL1_ADR_getrennt 1;
BA_ "GenSigSwitchedByIgnition" SG_ 1500 VL1_EPB 0;
BA_ "GenSigSendType" SG_ 1500 VL1_EPB 0;
BA_ "GenSigAutoGenSnd" SG_ 1500 VL1_EPB 1;
BA_ "GenSigAutoGenDsp" SG_ 1500 VL1_EPB 1;
BA_ "GenSigSwitchedByIgnition" SG_ 1500 VL1_res_13 0;
BA_ "GenSigSendType" SG_ 1500 VL1_res_13 0;
BA_ "GenSigAutoGenSnd" SG_ 1500 VL1_res_13 1;
BA_ "GenSigAutoGenDsp" SG_ 1500 VL1_res_13 1;
BA_ "GenSigSwitchedByIgnition" SG_ 1500 VL1_Daempfer 0;
BA_ "GenSigSendType" SG_ 1500 VL1_Daempfer 0;
BA_ "GenSigAutoGenSnd" SG_ 1500 VL1_Daempfer 1;
BA_ "GenSigAutoGenDsp" SG_ 1500 VL1_Daempfer 1;
BA_ "GenSigSwitchedByIgnition" SG_ 1500 VL1_Quersperre 0;
BA_ "GenSigSendType" SG_ 1500 VL1_Quersperre 0;
BA_ "GenSigAutoGenSnd" SG_ 1500 VL1_Quersperre 1;
BA_ "GenSigAutoGenDsp" SG_ 1500 VL1_Quersperre 1;
BA_ "GenSigSwitchedByIgnition" SG_ 1500 VL1_MotorSlave 0;
BA_ "GenSigSendType" SG_ 1500 VL1_MotorSlave 0;
BA_ "GenSigAutoGenSnd" SG_ 1500 VL1_MotorSlave 1;
BA_ "GenSigAutoGenDsp" SG_ 1500 VL1_MotorSlave 1;
BA_ "GenSigSwitchedByIgnition" SG_ 1500 VL1_SWA 0;
BA_ "GenSigSendType" SG_ 1500 VL1_SWA 0;
BA_ "GenSigAutoGenSnd" SG_ 1500 VL1_SWA 1;
BA_ "GenSigAutoGenDsp" SG_ 1500 VL1_SWA 1;
BA_ "GenSigSwitchedByIgnition" SG_ 1500 VL1_HCA 0;
BA_ "GenSigSendType" SG_ 1500 VL1_HCA 0;
BA_ "GenSigAutoGenSnd" SG_ 1500 VL1_HCA 1;
BA_ "GenSigAutoGenDsp" SG_ 1500 VL1_HCA 1;
BA_ "GenSigSwitchedByIgnition" SG_ 1500 VL1_RKA_Plus 0;
BA_ "GenSigSendType" SG_ 1500 VL1_RKA_Plus 0;
BA_ "GenSigAutoGenSnd" SG_ 1500 VL1_RKA_Plus 1;
BA_ "GenSigAutoGenDsp" SG_ 1500 VL1_RKA_Plus 1;
BA_ "GenSigSwitchedByIgnition" SG_ 1500 VL1_PLA 0;
BA_ "GenSigSendType" SG_ 1500 VL1_PLA 0;
BA_ "GenSigAutoGenSnd" SG_ 1500 VL1_PLA 1;
BA_ "GenSigAutoGenDsp" SG_ 1500 VL1_PLA 1;
BA_ "GenSigSwitchedByIgnition" SG_ 1500 VL1_WFS_KBI 0;
BA_ "GenSigSendType" SG_ 1500 VL1_WFS_KBI 0;
BA_ "GenSigAutoGenSnd" SG_ 1500 VL1_WFS_KBI 1;
BA_ "GenSigAutoGenDsp" SG_ 1500 VL1_WFS_KBI 1;
BA_ "GenSigSwitchedByIgnition" SG_ 1500 VL1_Kombi_KBI 0;
BA_ "GenSigSendType" SG_ 1500 VL1_Kombi_KBI 0;
BA_ "GenSigAutoGenSnd" SG_ 1500 VL1_Kombi_KBI 1;
BA_ "GenSigAutoGenDsp" SG_ 1500 VL1_Kombi_KBI 1;
BA_ "GenSigSwitchedByIgnition" SG_ 1500 VL1_Soll_eq_Ist 0;
BA_ "GenSigSendType" SG_ 1500 VL1_Soll_eq_Ist 0;
BA_ "GenSigAutoGenSnd" SG_ 1500 VL1_Soll_eq_Ist 1;
BA_ "GenSigAutoGenDsp" SG_ 1500 VL1_Soll_eq_Ist 1;
BA_ "GenSigSwitchedByIgnition" SG_ 1500 VL1_BSG_Komf 0;
BA_ "GenSigSendType" SG_ 1500 VL1_BSG_Komf 0;
BA_ "GenSigAutoGenSnd" SG_ 1500 VL1_BSG_Komf 1;
BA_ "GenSigAutoGenDsp" SG_ 1500 VL1_BSG_Komf 1;
BA_ "GenSigSwitchedByIgnition" SG_ 1500 VL1_ZKE 0;
BA_ "GenSigSendType" SG_ 1500 VL1_ZKE 0;
BA_ "GenSigAutoGenSnd" SG_ 1500 VL1_ZKE 1;
BA_ "GenSigAutoGenDsp" SG_ 1500 VL1_ZKE 1;
BA_ "GenSigSwitchedByIgnition" SG_ 1500 VL1_TSG_FT 0;
BA_ "GenSigSendType" SG_ 1500 VL1_TSG_FT 0;
BA_ "GenSigAutoGenSnd" SG_ 1500 VL1_TSG_FT 1;
BA_ "GenSigAutoGenDsp" SG_ 1500 VL1_TSG_FT 1;
BA_ "GenSigSwitchedByIgnition" SG_ 1500 VL1_TSG_BT 0;
BA_ "GenSigSendType" SG_ 1500 VL1_TSG_BT 0;
BA_ "GenSigAutoGenSnd" SG_ 1500 VL1_TSG_BT 1;
BA_ "GenSigAutoGenDsp" SG_ 1500 VL1_TSG_BT 1;
BA_ "GenSigSwitchedByIgnition" SG_ 1500 VL1_TSG_HL 0;
BA_ "GenSigSendType" SG_ 1500 VL1_TSG_HL 0;
BA_ "GenSigAutoGenSnd" SG_ 1500 VL1_TSG_HL 1;
BA_ "GenSigAutoGenDsp" SG_ 1500 VL1_TSG_HL 1;
BA_ "GenSigSwitchedByIgnition" SG_ 1500 VL1_TSG_HR 0;
BA_ "GenSigSendType" SG_ 1500 VL1_TSG_HR 0;
BA_ "GenSigAutoGenSnd" SG_ 1500 VL1_TSG_HR 1;
BA_ "GenSigAutoGenDsp" SG_ 1500 VL1_TSG_HR 1;
BA_ "GenSigSwitchedByIgnition" SG_ 1500 VL1_Memory 0;
BA_ "GenSigSendType" SG_ 1500 VL1_Memory 0;
BA_ "GenSigAutoGenSnd" SG_ 1500 VL1_Memory 1;
BA_ "GenSigAutoGenDsp" SG_ 1500 VL1_Memory 1;
BA_ "GenSigSwitchedByIgnition" SG_ 1500 VL1_Dachmodul_K 0;
BA_ "GenSigSendType" SG_ 1500 VL1_Dachmodul_K 0;
BA_ "GenSigAutoGenSnd" SG_ 1500 VL1_Dachmodul_K 1;
BA_ "GenSigAutoGenDsp" SG_ 1500 VL1_Dachmodul_K 1;
BA_ "GenSigSwitchedByIgnition" SG_ 1500 VL1_Zentralelektrik_II 0;
BA_ "GenSigSendType" SG_ 1500 VL1_Zentralelektrik_II 0;
BA_ "GenSigAutoGenSnd" SG_ 1500 VL1_Zentralelektrik_II 1;
BA_ "GenSigAutoGenDsp" SG_ 1500 VL1_Zentralelektrik_II 1;
BA_ "GenSigSwitchedByIgnition" SG_ 1500 VL1_RDK 0;
BA_ "GenSigSendType" SG_ 1500 VL1_RDK 0;
BA_ "GenSigAutoGenSnd" SG_ 1500 VL1_RDK 1;
BA_ "GenSigAutoGenDsp" SG_ 1500 VL1_RDK 1;
BA_ "GenSigSwitchedByIgnition" SG_ 1500 VL1_Lenksaeule 0;
BA_ "GenSigSendType" SG_ 1500 VL1_Lenksaeule 0;
BA_ "GenSigAutoGenSnd" SG_ 1500 VL1_Lenksaeule 1;
BA_ "GenSigAutoGenDsp" SG_ 1500 VL1_Lenksaeule 1;
BA_ "GenSigSwitchedByIgnition" SG_ 1500 VL1_Gateway 0;
BA_ "GenSigSendType" SG_ 1500 VL1_Gateway 0;
BA_ "GenSigAutoGenSnd" SG_ 1500 VL1_Gateway 1;
BA_ "GenSigAutoGenDsp" SG_ 1500 VL1_Gateway 1;
BA_ "GenSigSwitchedByIgnition" SG_ 1500 VL1_Clima_Komf 0;
BA_ "GenSigSendType" SG_ 1500 VL1_Clima_Komf 0;
BA_ "GenSigAutoGenSnd" SG_ 1500 VL1_Clima_Komf 1;
BA_ "GenSigAutoGenDsp" SG_ 1500 VL1_Clima_Komf 1;
BA_ "GenSigSwitchedByIgnition" SG_ 1500 VL1_Einparkhilfe 0;
BA_ "GenSigSendType" SG_ 1500 VL1_Einparkhilfe 0;
BA_ "GenSigAutoGenSnd" SG_ 1500 VL1_Einparkhilfe 1;
BA_ "GenSigAutoGenDsp" SG_ 1500 VL1_Einparkhilfe 1;
BA_ "GenSigSwitchedByIgnition" SG_ 1500 VL1_PTC_Heizung 0;
BA_ "GenSigSendType" SG_ 1500 VL1_PTC_Heizung 0;
BA_ "GenSigAutoGenSnd" SG_ 1500 VL1_PTC_Heizung 1;
BA_ "GenSigAutoGenDsp" SG_ 1500 VL1_PTC_Heizung 1;
BA_ "GenSigSwitchedByIgnition" SG_ 1500 VL1_Standheiz 0;
BA_ "GenSigSendType" SG_ 1500 VL1_Standheiz 0;
BA_ "GenSigAutoGenSnd" SG_ 1500 VL1_Standheiz 1;
BA_ "GenSigAutoGenDsp" SG_ 1500 VL1_Standheiz 1;
BA_ "GenSigSwitchedByIgnition" SG_ 1500 VL1_Verdeck 0;
BA_ "GenSigSendType" SG_ 1500 VL1_Verdeck 0;
BA_ "GenSigAutoGenSnd" SG_ 1500 VL1_Verdeck 1;
BA_ "GenSigAutoGenDsp" SG_ 1500 VL1_Verdeck 1;
BA_ "GenSigSwitchedByIgnition" SG_ 1500 VL1_RSE_I 0;
BA_ "GenSigSendType" SG_ 1500 VL1_RSE_I 0;
BA_ "GenSigAutoGenSnd" SG_ 1500 VL1_RSE_I 1;
BA_ "GenSigAutoGenDsp" SG_ 1500 VL1_RSE_I 1;
BA_ "GenSigSwitchedByIgnition" SG_ 1500 VL1_res_42 0;
BA_ "GenSigSendType" SG_ 1500 VL1_res_42 0;
BA_ "GenSigAutoGenSnd" SG_ 1500 VL1_res_42 1;
BA_ "GenSigAutoGenDsp" SG_ 1500 VL1_res_42 1;
BA_ "GenSigSwitchedByIgnition" SG_ 1500 VL1_MDI_I 0;
BA_ "GenSigSendType" SG_ 1500 VL1_MDI_I 0;
BA_ "GenSigAutoGenSnd" SG_ 1500 VL1_MDI_I 1;
BA_ "GenSigAutoGenDsp" SG_ 1500 VL1_MDI_I 1;
BA_ "GenSigSwitchedByIgnition" SG_ 1500 VL1_Anhaenger 0;
BA_ "GenSigSendType" SG_ 1500 VL1_Anhaenger 0;
BA_ "GenSigAutoGenSnd" SG_ 1500 VL1_Anhaenger 1;
BA_ "GenSigAutoGenDsp" SG_ 1500 VL1_Anhaenger 1;
BA_ "GenSigSwitchedByIgnition" SG_ 1500 VL1_Memory_BF 0;
BA_ "GenSigSendType" SG_ 1500 VL1_Memory_BF 0;
BA_ "GenSigAutoGenSnd" SG_ 1500 VL1_Memory_BF 1;
BA_ "GenSigAutoGenDsp" SG_ 1500 VL1_Memory_BF 1;
BA_ "GenSigSwitchedByIgnition" SG_ 1500 VL1_Easy_Entry_VF 0;
BA_ "GenSigSendType" SG_ 1500 VL1_Easy_Entry_VF 0;
BA_ "GenSigAutoGenSnd" SG_ 1500 VL1_Easy_Entry_VF 1;
BA_ "GenSigAutoGenDsp" SG_ 1500 VL1_Easy_Entry_VF 1;
BA_ "GenSigSwitchedByIgnition" SG_ 1500 VL1_Easy_Entry_VB 0;
BA_ "GenSigSendType" SG_ 1500 VL1_Easy_Entry_VB 0;
BA_ "GenSigAutoGenSnd" SG_ 1500 VL1_Easy_Entry_VB 1;
BA_ "GenSigAutoGenDsp" SG_ 1500 VL1_Easy_Entry_VB 1;
BA_ "GenSigSwitchedByIgnition" SG_ 1500 VL1_Heckdeckel 0;
BA_ "GenSigSendType" SG_ 1500 VL1_Heckdeckel 0;
BA_ "GenSigAutoGenSnd" SG_ 1500 VL1_Heckdeckel 1;
BA_ "GenSigAutoGenDsp" SG_ 1500 VL1_Heckdeckel 1;
BA_ "GenSigSwitchedByIgnition" SG_ 1500 VL1_Rearview 0;
BA_ "GenSigSendType" SG_ 1500 VL1_Rearview 0;
BA_ "GenSigAutoGenSnd" SG_ 1500 VL1_Rearview 1;
BA_ "GenSigAutoGenDsp" SG_ 1500 VL1_Rearview 1;
BA_ "GenSigSwitchedByIgnition" SG_ 1500 VL1_Sonderfzg_SG 0;
BA_ "GenSigSendType" SG_ 1500 VL1_Sonderfzg_SG 0;
BA_ "GenSigAutoGenSnd" SG_ 1500 VL1_Sonderfzg_SG 1;
BA_ "GenSigAutoGenDsp" SG_ 1500 VL1_Sonderfzg_SG 1;
BA_ "GenSigSwitchedByIgnition" SG_ 1500 VL1_Tastenmodul 0;
BA_ "GenSigSendType" SG_ 1500 VL1_Tastenmodul 0;
BA_ "GenSigAutoGenSnd" SG_ 1500 VL1_Tastenmodul 1;
BA_ "GenSigAutoGenDsp" SG_ 1500 VL1_Tastenmodul 1;
BA_ "GenSigSwitchedByIgnition" SG_ 1500 VL1_Kompass 0;
BA_ "GenSigSendType" SG_ 1500 VL1_Kompass 0;
BA_ "GenSigAutoGenSnd" SG_ 1500 VL1_Kompass 1;
BA_ "GenSigAutoGenDsp" SG_ 1500 VL1_Kompass 1;
BA_ "GenSigSwitchedByIgnition" SG_ 1500 VL1_WFS_K 0;
BA_ "GenSigSendType" SG_ 1500 VL1_WFS_K 0;
BA_ "GenSigAutoGenSnd" SG_ 1500 VL1_WFS_K 1;
BA_ "GenSigAutoGenDsp" SG_ 1500 VL1_WFS_K 1;
BA_ "GenSigSwitchedByIgnition" SG_ 1500 VL1_GSM_Pager 0;
BA_ "GenSigSendType" SG_ 1500 VL1_GSM_Pager 0;
BA_ "GenSigAutoGenSnd" SG_ 1500 VL1_GSM_Pager 1;
BA_ "GenSigAutoGenDsp" SG_ 1500 VL1_GSM_Pager 1;
BA_ "GenSigSwitchedByIgnition" SG_ 1500 VL1_InfoElektronik 0;
BA_ "GenSigSendType" SG_ 1500 VL1_InfoElektronik 0;
BA_ "GenSigAutoGenSnd" SG_ 1500 VL1_InfoElektronik 1;
BA_ "GenSigAutoGenDsp" SG_ 1500 VL1_InfoElektronik 1;
BA_ "GenSigSwitchedByIgnition" SG_ 1500 VL1_DSP 0;
BA_ "GenSigSendType" SG_ 1500 VL1_DSP 0;
BA_ "GenSigAutoGenSnd" SG_ 1500 VL1_DSP 1;
BA_ "GenSigAutoGenDsp" SG_ 1500 VL1_DSP 1;
BA_ "GenSigSwitchedByIgnition" SG_ 1500 VL1_DAB 0;
BA_ "GenSigSendType" SG_ 1500 VL1_DAB 0;
BA_ "GenSigAutoGenSnd" SG_ 1500 VL1_DAB 1;
BA_ "GenSigAutoGenDsp" SG_ 1500 VL1_DAB 1;
BA_ "GenSigSwitchedByIgnition" SG_ 1500 VL1_Telematik 0;
BA_ "GenSigSendType" SG_ 1500 VL1_Telematik 0;
BA_ "GenSigAutoGenSnd" SG_ 1500 VL1_Telematik 1;
BA_ "GenSigAutoGenDsp" SG_ 1500 VL1_Telematik 1;
BA_ "GenSigSwitchedByIgnition" SG_ 1500 VL1_Navigation 0;
BA_ "GenSigSendType" SG_ 1500 VL1_Navigation 0;
BA_ "GenSigAutoGenSnd" SG_ 1500 VL1_Navigation 1;
BA_ "GenSigAutoGenDsp" SG_ 1500 VL1_Navigation 1;
BA_ "GenSigSwitchedByIgnition" SG_ 1500 VL1_TV_Tuner 0;
BA_ "GenSigSendType" SG_ 1500 VL1_TV_Tuner 0;
BA_ "GenSigAutoGenSnd" SG_ 1500 VL1_TV_Tuner 1;
BA_ "GenSigAutoGenDsp" SG_ 1500 VL1_TV_Tuner 1;
BA_ "GenSigSwitchedByIgnition" SG_ 1500 VL1_Neigungsmodul_I 0;
BA_ "GenSigSendType" SG_ 1500 VL1_Neigungsmodul_I 0;
BA_ "GenSigAutoGenSnd" SG_ 1500 VL1_Neigungsmodul_I 1;
BA_ "GenSigAutoGenDsp" SG_ 1500 VL1_Neigungsmodul_I 1;
BA_ "GenSigSwitchedByIgnition" SG_ 1500 VL1_Radio 0;
BA_ "GenSigSendType" SG_ 1500 VL1_Radio 0;
BA_ "GenSigAutoGenSnd" SG_ 1500 VL1_Radio 1;
BA_ "GenSigAutoGenDsp" SG_ 1500 VL1_Radio 1;
BA_ "GenSigSwitchedByIgnition" SG_ 1500 VL1_Telefon 0;
BA_ "GenSigSendType" SG_ 1500 VL1_Telefon 0;
BA_ "GenSigAutoGenSnd" SG_ 1500 VL1_Telefon 1;
BA_ "GenSigAutoGenDsp" SG_ 1500 VL1_Telefon 1;
BA_ "GenSigSwitchedByIgnition" SG_ 1488 SY1_CAN_extern 0;
BA_ "GenSigSendType" SG_ 1488 SY1_CAN_extern 0;
BA_ "GenSigAutoGenSnd" SG_ 1488 SY1_CAN_extern 1;
BA_ "GenSigAutoGenDsp" SG_ 1488 SY1_CAN_extern 1;
BA_ "GenSigSwitchedByIgnition" SG_ 1488 SY1_Diag_Ant 0;
BA_ "GenSigSendType" SG_ 1488 SY1_Diag_Ant 0;
BA_ "GenSigAutoGenSnd" SG_ 1488 SY1_Diag_Ant 1;
BA_ "GenSigAutoGenDsp" SG_ 1488 SY1_Diag_Ant 1;
BA_ "GenSigSwitchedByIgnition" SG_ 1488 SY1_Sleep_Komf 0;
BA_ "GenSigSendType" SG_ 1488 SY1_Sleep_Komf 0;
BA_ "GenSigAutoGenSnd" SG_ 1488 SY1_Sleep_Komf 1;
BA_ "GenSigAutoGenDsp" SG_ 1488 SY1_Sleep_Komf 1;
BA_ "GenSigSwitchedByIgnition" SG_ 1488 SY1_Diag_Komf 0;
BA_ "GenSigSendType" SG_ 1488 SY1_Diag_Komf 0;
BA_ "GenSigAutoGenSnd" SG_ 1488 SY1_Diag_Komf 1;
BA_ "GenSigAutoGenDsp" SG_ 1488 SY1_Diag_Komf 1;
BA_ "GenSigSwitchedByIgnition" SG_ 1488 SY1_Sleep_Info 0;
BA_ "GenSigSendType" SG_ 1488 SY1_Sleep_Info 0;
BA_ "GenSigAutoGenSnd" SG_ 1488 SY1_Sleep_Info 1;
BA_ "GenSigAutoGenDsp" SG_ 1488 SY1_Sleep_Info 1;
BA_ "GenSigSwitchedByIgnition" SG_ 1488 SY1_Diag_Info 0;
BA_ "GenSigSendType" SG_ 1488 SY1_Diag_Info 0;
BA_ "GenSigAutoGenSnd" SG_ 1488 SY1_Diag_Info 1;
BA_ "GenSigAutoGenDsp" SG_ 1488 SY1_Diag_Info 1;
BA_ "GenSigSwitchedByIgnition" SG_ 1488 SY1_CAN_Info 0;
BA_ "GenSigFuncType" SG_ 1488 SY1_CAN_Info 8;
BA_ "GenSigSendType" SG_ 1488 SY1_CAN_Info 0;
BA_ "GenSigAutoGenSnd" SG_ 1488 SY1_CAN_Info 1;
BA_ "GenSigAutoGenDsp" SG_ 1488 SY1_CAN_Info 1;
BA_ "GenSigSwitchedByIgnition" SG_ 1488 SY1_Verbauinfo 0;
BA_ "GenSigSendType" SG_ 1488 SY1_Verbauinfo 0;
BA_ "GenSigAutoGenSnd" SG_ 1488 SY1_Verbauinfo 1;
BA_ "GenSigAutoGenDsp" SG_ 1488 SY1_Verbauinfo 1;
BA_ "GenSigSwitchedByIgnition" SG_ 1488 SY1_Fzg_Klasse 0;
BA_ "GenSigSendType" SG_ 1488 SY1_Fzg_Klasse 0;
BA_ "GenSigAutoGenSnd" SG_ 1488 SY1_Fzg_Klasse 1;
BA_ "GenSigAutoGenDsp" SG_ 1488 SY1_Fzg_Klasse 1;
BA_ "GenSigSwitchedByIgnition" SG_ 1488 SY1_Fzg_Marke 0;
BA_ "GenSigSendType" SG_ 1488 SY1_Fzg_Marke 0;
BA_ "GenSigAutoGenSnd" SG_ 1488 SY1_Fzg_Marke 1;
BA_ "GenSigAutoGenDsp" SG_ 1488 SY1_Fzg_Marke 1;
BA_ "GenSigSwitchedByIgnition" SG_ 1488 SY1_Fzg_Derivat 0;
BA_ "GenSigFuncType" SG_ 1488 SY1_Fzg_Derivat 8;
BA_ "GenSigSendType" SG_ 1488 SY1_Fzg_Derivat 0;
BA_ "GenSigAutoGenSnd" SG_ 1488 SY1_Fzg_Derivat 1;
BA_ "GenSigAutoGenDsp" SG_ 1488 SY1_Fzg_Derivat 1;
BA_ "GenSigSwitchedByIgnition" SG_ 1488 SY1_Fzg_Gen 0;
BA_ "GenSigSendType" SG_ 1488 SY1_Fzg_Gen 0;
BA_ "GenSigAutoGenSnd" SG_ 1488 SY1_Fzg_Gen 1;
BA_ "GenSigAutoGenDsp" SG_ 1488 SY1_Fzg_Gen 1;
BA_ "GenSigSwitchedByIgnition" SG_ 1488 SY1_Fzg_Index 0;
BA_ "GenSigStartValue" SG_ 1488 SY1_Fzg_Index 15;
BA_ "GenSigSendType" SG_ 1488 SY1_Fzg_Index 0;
BA_ "GenSigAutoGenSnd" SG_ 1488 SY1_Fzg_Index 1;
BA_ "GenSigAutoGenDsp" SG_ 1488 SY1_Fzg_Index 1;
BA_ "GenSigSwitchedByIgnition" SG_ 1488 SY1_Lenker 0;
BA_ "GenSigSendType" SG_ 1488 SY1_Lenker 0;
BA_ "GenSigAutoGenSnd" SG_ 1488 SY1_Lenker 1;
BA_ "GenSigAutoGenDsp" SG_ 1488 SY1_Lenker 1;
BA_ "GenSigSwitchedByIgnition" SG_ 1488 SY1_Tueren 0;
BA_ "GenSigSendType" SG_ 1488 SY1_Tueren 0;
BA_ "GenSigAutoGenSnd" SG_ 1488 SY1_Tueren 1;
BA_ "GenSigAutoGenDsp" SG_ 1488 SY1_Tueren 1;
BA_ "GenSigSwitchedByIgnition" SG_ 1488 SY1_Transportmode 0;
BA_ "GenSigSendType" SG_ 1488 SY1_Transportmode 0;
BA_ "GenSigAutoGenSnd" SG_ 1488 SY1_Transportmode 1;
BA_ "GenSigAutoGenDsp" SG_ 1488 SY1_Transportmode 1;
BA_ "GenSigSwitchedByIgnition" SG_ 1488 SY1_Fehlereintr 0;
BA_ "GenSigSendType" SG_ 1488 SY1_Fehlereintr 0;
BA_ "GenSigAutoGenSnd" SG_ 1488 SY1_Fehlereintr 1;
BA_ "GenSigAutoGenDsp" SG_ 1488 SY1_Fehlereintr 1;
BA_ "GenSigSwitchedByIgnition" SG_ 1488 SY1_Komf_NV 0;
BA_ "GenSigStartValue" SG_ 1488 SY1_Komf_NV 8;
BA_ "GenSigSendType" SG_ 1488 SY1_Komf_NV 0;
BA_ "GenSigAutoGenSnd" SG_ 1488 SY1_Komf_NV 1;
BA_ "GenSigAutoGenDsp" SG_ 1488 SY1_Komf_NV 1;
BA_ "GenSigSwitchedByIgnition" SG_ 1488 SY1_Komf_HV 0;
BA_ "GenSigStartValue" SG_ 1488 SY1_Komf_HV 3;
BA_ "GenSigSendType" SG_ 1488 SY1_Komf_HV 0;
BA_ "GenSigAutoGenSnd" SG_ 1488 SY1_Komf_HV 1;
BA_ "GenSigAutoGenDsp" SG_ 1488 SY1_Komf_HV 1;
BA_ "GenSigSwitchedByIgnition" SG_ 1488 SY1_Ant_NV 0;
BA_ "GenSigStartValue" SG_ 1488 SY1_Ant_NV 7;
BA_ "GenSigSendType" SG_ 1488 SY1_Ant_NV 0;
BA_ "GenSigAutoGenSnd" SG_ 1488 SY1_Ant_NV 1;
BA_ "GenSigAutoGenDsp" SG_ 1488 SY1_Ant_NV 1;
BA_ "GenSigSwitchedByIgnition" SG_ 1488 SY1_Ant_HV 0;
BA_ "GenSigStartValue" SG_ 1488 SY1_Ant_HV 5;
BA_ "GenSigSendType" SG_ 1488 SY1_Ant_HV 0;
BA_ "GenSigAutoGenSnd" SG_ 1488 SY1_Ant_HV 1;
BA_ "GenSigAutoGenDsp" SG_ 1488 SY1_Ant_HV 1;
BA_ "GenSigSwitchedByIgnition" SG_ 1488 SY1_Relais_FAS_Zweig 0;
BA_ "GenSigSendType" SG_ 1488 SY1_Relais_FAS_Zweig 3;
BA_ "GenSigAutoGenSnd" SG_ 1488 SY1_Relais_FAS_Zweig 1;
BA_ "GenSigAutoGenDsp" SG_ 1488 SY1_Relais_FAS_Zweig 1;
BA_ "GenSigSwitchedByIgnition" SG_ 1488 SY1_ELV_Lock_Supply 0;
BA_ "GenSigSendType" SG_ 1488 SY1_ELV_Lock_Supply 3;
BA_ "GenSigAutoGenSnd" SG_ 1488 SY1_ELV_Lock_Supply 1;
BA_ "GenSigAutoGenDsp" SG_ 1488 SY1_ELV_Lock_Supply 1;
BA_ "GenSigSwitchedByIgnition" SG_ 1488 SY1_QRS_Messmodus 0;
BA_ "GenSigSendType" SG_ 1488 SY1_QRS_Messmodus 3;
BA_ "GenSigAutoGenSnd" SG_ 1488 SY1_QRS_Messmodus 1;
BA_ "GenSigAutoGenDsp" SG_ 1488 SY1_QRS_Messmodus 1;
BA_ "GenSigSwitchedByIgnition" SG_ 1488 SY1_NWDF_gueltig 0;
BA_ "GenSigStartValue" SG_ 1488 SY1_NWDF_gueltig 1;
BA_ "GenSigSendType" SG_ 1488 SY1_NWDF_gueltig 0;
BA_ "GenSigAutoGenSnd" SG_ 1488 SY1_NWDF_gueltig 1;
BA_ "GenSigAutoGenDsp" SG_ 1488 SY1_NWDF_gueltig 1;
BA_ "GenSigSwitchedByIgnition" SG_ 1488 SY1_NWDF 0;
BA_ "GenSigSendType" SG_ 1488 SY1_NWDF 3;
BA_ "GenSigAutoGenSnd" SG_ 1488 SY1_NWDF 1;
BA_ "GenSigAutoGenDsp" SG_ 1488 SY1_NWDF 1;
BA_ "GenSigSwitchedByIgnition" SG_ 1488 SY1_Notbrems_Status 0;
BA_ "GenSigSendType" SG_ 1488 SY1_Notbrems_Status 3;
BA_ "GenSigAutoGenSnd" SG_ 1488 SY1_Notbrems_Status 1;
BA_ "GenSigAutoGenDsp" SG_ 1488 SY1_Notbrems_Status 1;
BA_ "GenSigSwitchedByIgnition" SG_ 1225 Tele_Data_BMS 0;
BA_ "GenSigSendType" SG_ 1225 Tele_Data_BMS 0;
BA_REL_ "GenSigTimeoutTime" BU_SG_REL_ Getriebe_DQ SG_ 1160 MO6_SollM_Getr 500;
BA_REL_ "GenSigTimeoutTime" BU_SG_REL_ Getriebe_DQ_Hyb SG_ 1160 MO6_SollM_Getr 500;
BA_REL_ "GenSigTimeoutTime" BU_SG_REL_ Getriebe_Sele SG_ 1160 MO6_SollM_Getr 500;
BA_REL_ "GenSigTimeoutTime" BU_SG_REL_ Getriebe_AG6 SG_ 1160 MO6_Ist_Moment 500;
BA_REL_ "GenSigTimeoutTime" BU_SG_REL_ Getriebe_DQ SG_ 1160 MO6_Ist_Moment 500;
BA_REL_ "GenSigTimeoutTime" BU_SG_REL_ Getriebe_DQ_Hyb SG_ 1160 MO6_Ist_Moment 500;
BA_REL_ "GenSigTimeoutTime" BU_SG_REL_ Getriebe_Sele SG_ 1160 MO6_Ist_Moment 500;
BA_REL_ "GenSigTimeoutTime" BU_SG_REL_ Getriebe_DQ SG_ 1160 MO6_Hoeheninfo 500;
BA_REL_ "GenSigTimeoutTime" BU_SG_REL_ Getriebe_DQ_Hyb SG_ 1160 MO6_Hoeheninfo 500;
BA_REL_ "GenSigTimeoutTime" BU_SG_REL_ Getriebe_AG6 SG_ 1160 MO6_GRA_Soll 500;
BA_REL_ "GenSigTimeoutTime" BU_SG_REL_ Getriebe_DQ SG_ 1160 MO6_GRA_Soll 500;
BA_REL_ "GenSigTimeoutTime" BU_SG_REL_ Getriebe_DQ_Hyb SG_ 1160 MO6_GRA_Soll 500;
BA_REL_ "GenSigTimeoutTime" BU_SG_REL_ Getriebe_DQ SG_ 1160 MO6_MomIntGeEing 500;
BA_REL_ "GenSigTimeoutTime" BU_SG_REL_ Getriebe_DQ_Hyb SG_ 1160 MO6_MomIntGeEing 500;
BA_REL_ "GenSigTimeoutTime" BU_SG_REL_ BMS_Hybrid SG_ 1160 MO6_FF_Mux00 500;
BA_REL_ "GenSigTimeoutTime" BU_SG_REL_ Getriebe_DQ SG_ 1160 MO6_FF_Mux00 500;
BA_REL_ "GenSigTimeoutTime" BU_SG_REL_ Getriebe_DQ_Hyb SG_ 1160 MO6_FF_Mux00 500;
BA_REL_ "GenSigTimeoutTime" BU_SG_REL_ Getriebe_Sele SG_ 1160 MO6_FF_Mux00 500;
BA_REL_ "GenSigTimeoutTime" BU_SG_REL_ LEH_Hybrid SG_ 1160 MO6_FF_Mux00 500;
BA_REL_ "GenSigTimeoutTime" BU_SG_REL_ BMS_Hybrid SG_ 1160 MO6_FF_Mux01 500;
BA_REL_ "GenSigTimeoutTime" BU_SG_REL_ Getriebe_DQ SG_ 1160 MO6_FF_Mux01 500;
BA_REL_ "GenSigTimeoutTime" BU_SG_REL_ Getriebe_DQ_Hyb SG_ 1160 MO6_FF_Mux01 500;
BA_REL_ "GenSigTimeoutTime" BU_SG_REL_ Getriebe_Sele SG_ 1160 MO6_FF_Mux01 500;
BA_REL_ "GenSigTimeoutTime" BU_SG_REL_ LEH_Hybrid SG_ 1160 MO6_FF_Mux01 500;
BA_REL_ "GenSigTimeoutTime" BU_SG_REL_ BMS_Hybrid SG_ 1160 MO6_FF_Mux02 500;
BA_REL_ "GenSigTimeoutTime" BU_SG_REL_ Getriebe_DQ SG_ 1160 MO6_FF_Mux02 500;
BA_REL_ "GenSigTimeoutTime" BU_SG_REL_ Getriebe_DQ_Hyb SG_ 1160 MO6_FF_Mux02 500;
BA_REL_ "GenSigTimeoutTime" BU_SG_REL_ Getriebe_Sele SG_ 1160 MO6_FF_Mux02 500;
BA_REL_ "GenSigTimeoutTime" BU_SG_REL_ LEH_Hybrid SG_ 1160 MO6_FF_Mux02 500;
BA_REL_ "GenSigTimeoutTime" BU_SG_REL_ BMS_Hybrid SG_ 1160 MO6_FF_Mux03 500;
BA_REL_ "GenSigTimeoutTime" BU_SG_REL_ Getriebe_DQ SG_ 1160 MO6_FF_Mux03 500;
BA_REL_ "GenSigTimeoutTime" BU_SG_REL_ Getriebe_DQ_Hyb SG_ 1160 MO6_FF_Mux03 500;
BA_REL_ "GenSigTimeoutTime" BU_SG_REL_ Getriebe_Sele SG_ 1160 MO6_FF_Mux03 500;
BA_REL_ "GenSigTimeoutTime" BU_SG_REL_ LEH_Hybrid SG_ 1160 MO6_FF_Mux03 500;
BA_REL_ "GenSigTimeoutTime" BU_SG_REL_ BMS_Hybrid SG_ 1160 MO6_FF_Mux04 500;
BA_REL_ "GenSigTimeoutTime" BU_SG_REL_ Getriebe_DQ SG_ 1160 MO6_FF_Mux04 500;
BA_REL_ "GenSigTimeoutTime" BU_SG_REL_ Getriebe_DQ_Hyb SG_ 1160 MO6_FF_Mux04 500;
BA_REL_ "GenSigTimeoutTime" BU_SG_REL_ Getriebe_Sele SG_ 1160 MO6_FF_Mux04 500;
BA_REL_ "GenSigTimeoutTime" BU_SG_REL_ LEH_Hybrid SG_ 1160 MO6_FF_Mux04 500;
BA_REL_ "GenSigTimeoutTime" BU_SG_REL_ Getriebe_DQ SG_ 1160 MO6_Freigabe_GRA 500;
BA_REL_ "GenSigTimeoutTime" BU_SG_REL_ Getriebe_DQ_Hyb SG_ 1160 MO6_Freigabe_GRA 500;
BA_REL_ "GenSigTimeoutTime" BU_SG_REL_ Getriebe_AG6 SG_ 1160 MO6_RegPartikel 500;
BA_REL_ "GenSigTimeoutTime" BU_SG_REL_ Getriebe_DQ SG_ 1160 MO6_RegPartikel 500;
BA_REL_ "GenSigTimeoutTime" BU_SG_REL_ Getriebe_DQ_Hyb SG_ 1160 MO6_RegPartikel 500;
BA_REL_ "GenSigTimeoutTime" BU_SG_REL_ BMS_Hybrid SG_ 1160 MO6_Zaehler 500;
BA_REL_ "GenSigTimeoutTime" BU_SG_REL_ Getriebe_DQ SG_ 1160 MO6_Zaehler 500;
BA_REL_ "GenSigTimeoutTime" BU_SG_REL_ Getriebe_DQ_Hyb SG_ 1160 MO6_Zaehler 500;
BA_REL_ "GenSigTimeoutTime" BU_SG_REL_ LEH_Hybrid SG_ 1160 MO6_Zaehler 500;
BA_REL_ "GenSigTimeoutTime" BU_SG_REL_ Getriebe_DQ SG_ 1416 MO7_Sta_VBegr 500;
BA_REL_ "GenSigTimeoutTime" BU_SG_REL_ Getriebe_DQ_Hyb SG_ 1416 MO7_Sta_VBegr 500;
BA_REL_ "GenSigTimeoutTime" BU_SG_REL_ Gateway_PQ35 SG_ 1416 MO7_Fehlereintr 500;
BA_REL_ "GenSigTimeoutTime" BU_SG_REL_ Getriebe_DQ SG_ 1416 MO7_StaOeltemp 500;
BA_REL_ "GenSigTimeoutTime" BU_SG_REL_ Getriebe_DQ_Hyb SG_ 1416 MO7_StaOeltemp 500;
BA_REL_ "GenSigTimeoutTime" BU_SG_REL_ Bremse_MK60EC SG_ 1416 MO7_Hoeheninfo 500;
BA_REL_ "GenSigTimeoutTime" BU_SG_REL_ Bremse_MK70MABS SG_ 1416 MO7_Hoeheninfo 500;
BA_REL_ "GenSigTimeoutTime" BU_SG_REL_ Bremse_TRW_EBC450M SG_ 1416 MO7_Hoeheninfo 500;
BA_REL_ "GenSigTimeoutTime" BU_SG_REL_ Bremse_TRW_ESP SG_ 1416 MO7_Hoeheninfo 500;
BA_REL_ "GenSigTimeoutTime" BU_SG_REL_ Getriebe_DQ SG_ 1416 MO7_Hoeheninfo 500;
BA_REL_ "GenSigTimeoutTime" BU_SG_REL_ Getriebe_DQ_Hyb SG_ 1416 MO7_Hoeheninfo 500;
BA_REL_ "GenSigTimeoutTime" BU_SG_REL_ Getriebe_Sele SG_ 1416 MO7_Hoeheninfo 500;
BA_REL_ "GenSigTimeoutTime" BU_SG_REL_ Gateway_PQ35 SG_ 1416 MO7_SleepInd 500;
BA_REL_ "GenSigTimeoutTime" BU_SG_REL_ Gateway_PQ35 SG_ 1416 MO7_Gen_ein 500;
BA_REL_ "GenSigTimeoutTime" BU_SG_REL_ Getriebe_DQ SG_ 1416 MO7_Oeltemp 500;
BA_REL_ "GenSigTimeoutTime" BU_SG_REL_ Getriebe_DQ_Hyb SG_ 1416 MO7_Oeltemp 500;
BA_REL_ "GenSigTimeoutTime" BU_SG_REL_ Getriebe_Sele SG_ 1416 MO7_Oeltemp 500;
BA_REL_ "GenSigTimeoutTime" BU_SG_REL_ Magne_Ride SG_ 1162 MO8_Checksumme 500;
BA_REL_ "GenSigTimeoutTime" BU_SG_REL_ Getriebe_Sele SG_ 1162 MO8_Sportschalter 500;
BA_REL_ "GenSigTimeoutTime" BU_SG_REL_ Magne_Ride SG_ 1162 MO8_Sportschalter 500;
BA_REL_ "GenSigTimeoutTime" BU_SG_REL_ Getriebe_Sele SG_ 1162 MO8_LampeDZBegr 500;
BA_REL_ "GenSigTimeoutTime" BU_SG_REL_ Getriebe_Sele SG_ 1162 MO8_Avus_Motorschutz 500;
BA_REL_ "GenSigTimeoutTime" BU_SG_REL_ Magne_Ride SG_ 1162 MO8_Zaehler 500;
BA_REL_ "GenSigTimeoutTime" BU_SG_REL_ Bremse_MK60EC SG_ 644 MOB_Checksum 500;
BA_REL_ "GenSigTimeoutTime" BU_SG_REL_ Bremse_TRW_EBC450M SG_ 644 MOB_Checksum 500;
BA_REL_ "GenSigTimeoutTime" BU_SG_REL_ Bremse_TRW_ESP SG_ 644 MOB_Checksum 500;
BA_REL_ "GenSigTimeoutTime" BU_SG_REL_ Bremse_MK60EC SG_ 644 MOB_Zaehler 500;
BA_REL_ "GenSigTimeoutTime" BU_SG_REL_ Bremse_TRW_EBC450M SG_ 644 MOB_Zaehler 500;
BA_REL_ "GenSigTimeoutTime" BU_SG_REL_ Bremse_TRW_ESP SG_ 644 MOB_Zaehler 500;
BA_REL_ "GenSigTimeoutTime" BU_SG_REL_ Bremse_MK60EC SG_ 644 MOB_Standby 500;
BA_REL_ "GenSigTimeoutTime" BU_SG_REL_ Bremse_TRW_EBC450M SG_ 644 MOB_Standby 500;
BA_REL_ "GenSigTimeoutTime" BU_SG_REL_ Bremse_TRW_ESP SG_ 644 MOB_Standby 500;
BA_REL_ "GenSigTimeoutTime" BU_SG_REL_ Bremse_TRW_EBC450M SG_ 644 MOB_Anhaltewunsch 500;
BA_REL_ "GenSigTimeoutTime" BU_SG_REL_ Bremse_TRW_ESP SG_ 644 MOB_Anhaltewunsch 500;
BA_REL_ "GenSigTimeoutTime" BU_SG_REL_ Getriebe_DQ SG_ 644 MOB_Anhaltewunsch 500;
BA_REL_ "GenSigTimeoutTime" BU_SG_REL_ Bremse_MK60EC SG_ 644 MOB_Freigabe 500;
BA_REL_ "GenSigTimeoutTime" BU_SG_REL_ Bremse_TRW_EBC450M SG_ 644 MOB_Freigabe 500;
BA_REL_ "GenSigTimeoutTime" BU_SG_REL_ Bremse_TRW_ESP SG_ 644 MOB_Freigabe 500;
BA_REL_ "GenSigTimeoutTime" BU_SG_REL_ Bremse_TRW_EBC450M SG_ 644 MOB_Bremsstgr 500;
BA_REL_ "GenSigTimeoutTime" BU_SG_REL_ Bremse_TRW_ESP SG_ 644 MOB_Bremsstgr 500;
BA_REL_ "GenSigTimeoutTime" BU_SG_REL_ Bremse_MK60EC SG_ 644 MOB_Bremsmom 500;
BA_REL_ "GenSigTimeoutTime" BU_SG_REL_ Bremse_TRW_EBC450M SG_ 1408 MFN_Zaehler 5000;
BA_REL_ "GenSigTimeoutTime" BU_SG_REL_ Bremse_TRW_ESP SG_ 1408 MFN_Zaehler 5000;
BA_REL_ "GenSigTimeoutTime" BU_SG_REL_ EPB_TRW SG_ 1408 MFN_Zaehler 5000;
BA_REL_ "GenSigTimeoutTime" BU_SG_REL_ EPB_TRW_VW411CS SG_ 1408 MFN_Zaehler 5000;
BA_REL_ "GenSigTimeoutTime" BU_SG_REL_ Gateway_PQ35 SG_ 1408 MFN_Zaehler 5000;
BA_REL_ "GenSigTimeoutTime" BU_SG_REL_ Bremse_TRW_EBC450M SG_ 1408 MFN_Zaehler_ 5000;
BA_REL_ "GenSigTimeoutTime" BU_SG_REL_ Bremse_TRW_ESP SG_ 1408 MFN_Zaehler_ 5000;
BA_REL_ "GenSigTimeoutTime" BU_SG_REL_ EPB_TRW SG_ 1408 MFN_Zaehler_ 5000;
BA_REL_ "GenSigTimeoutTime" BU_SG_REL_ EPB_TRW_VW411CS SG_ 1408 MFN_Zaehler_ 5000;
BA_REL_ "GenSigTimeoutTime" BU_SG_REL_ BMS_Hybrid SG_ 1408 MFN_Drive_Cycle 5000;
BA_REL_ "GenSigTimeoutTime" BU_SG_REL_ Getriebe_AG6 SG_ 1408 MFN_Drive_Cycle 5000;
BA_REL_ "GenSigTimeoutTime" BU_SG_REL_ Getriebe_DQ SG_ 1408 MFN_Drive_Cycle 5000;
BA_REL_ "GenSigTimeoutTime" BU_SG_REL_ Getriebe_DQ_Hyb SG_ 1408 MFN_Drive_Cycle 5000;
BA_REL_ "GenSigTimeoutTime" BU_SG_REL_ Getriebe_Sele SG_ 1408 MFN_Drive_Cycle 5000;
BA_REL_ "GenSigTimeoutTime" BU_SG_REL_ LEH_Hybrid SG_ 1408 MFN_Drive_Cycle 5000;
BA_REL_ "GenSigTimeoutTime" BU_SG_REL_ BMS_Hybrid SG_ 1408 MFN_Warmup_Cycle 5000;
BA_REL_ "GenSigTimeoutTime" BU_SG_REL_ Bremse_TRW_ESP SG_ 1408 MFN_Warmup_Cycle 5000;
BA_REL_ "GenSigTimeoutTime" BU_SG_REL_ Gateway_PQ35 SG_ 1408 MFN_Warmup_Cycle 5000;
BA_REL_ "GenSigTimeoutTime" BU_SG_REL_ Getriebe_AG6 SG_ 1408 MFN_Warmup_Cycle 5000;
BA_REL_ "GenSigTimeoutTime" BU_SG_REL_ Getriebe_DQ SG_ 1408 MFN_Warmup_Cycle 5000;
BA_REL_ "GenSigTimeoutTime" BU_SG_REL_ Getriebe_DQ_Hyb SG_ 1408 MFN_Warmup_Cycle 5000;
BA_REL_ "GenSigTimeoutTime" BU_SG_REL_ Getriebe_Sele SG_ 1408 MFN_Warmup_Cycle 5000;
BA_REL_ "GenSigTimeoutTime" BU_SG_REL_ LEH_Hybrid SG_ 1408 MFN_Warmup_Cycle 5000;
BA_REL_ "GenSigTimeoutTime" BU_SG_REL_ BMS_Hybrid SG_ 1408 MFN_NormedTrip 5000;
BA_REL_ "GenSigTimeoutTime" BU_SG_REL_ Getriebe_AG6 SG_ 1408 MFN_NormedTrip 5000;
BA_REL_ "GenSigTimeoutTime" BU_SG_REL_ Getriebe_DQ SG_ 1408 MFN_NormedTrip 5000;
BA_REL_ "GenSigTimeoutTime" BU_SG_REL_ Getriebe_DQ_Hyb SG_ 1408 MFN_NormedTrip 5000;
BA_REL_ "GenSigTimeoutTime" BU_SG_REL_ Getriebe_Sele SG_ 1408 MFN_NormedTrip 5000;
BA_REL_ "GenSigTimeoutTime" BU_SG_REL_ LEH_Hybrid SG_ 1408 MFN_NormedTrip 5000;
BA_REL_ "GenSigTimeoutTime" BU_SG_REL_ Bremse_TRW_EBC450M SG_ 1408 MFN_Verbrenn_Typ 5000;
BA_REL_ "GenSigTimeoutTime" BU_SG_REL_ Bremse_TRW_ESP SG_ 1408 MFN_Verbrenn_Typ 5000;
BA_REL_ "GenSigTimeoutTime" BU_SG_REL_ EPB_TRW SG_ 1408 MFN_Verbrenn_Typ 5000;
BA_REL_ "GenSigTimeoutTime" BU_SG_REL_ EPB_TRW_VW411CS SG_ 1408 MFN_Verbrenn_Typ 5000;
BA_REL_ "GenSigTimeoutTime" BU_SG_REL_ Gateway_PQ35 SG_ 1408 MFN_Verbrenn_Typ 5000;
BA_REL_ "GenSigTimeoutTime" BU_SG_REL_ Getriebe_DQ SG_ 1408 MFN_Verbrenn_Typ 5000;
BA_REL_ "GenSigTimeoutTime" BU_SG_REL_ Getriebe_DQ_Hyb SG_ 1408 MFN_Verbrenn_Typ 5000;
BA_REL_ "GenSigTimeoutTime" BU_SG_REL_ Bremse_TRW_EBC450M SG_ 1408 MFN_Motorleistung 5000;
BA_REL_ "GenSigTimeoutTime" BU_SG_REL_ Bremse_TRW_ESP SG_ 1408 MFN_Motorleistung 5000;
BA_REL_ "GenSigTimeoutTime" BU_SG_REL_ EPB_TRW SG_ 1408 MFN_Motorleistung 5000;
BA_REL_ "GenSigTimeoutTime" BU_SG_REL_ Bremse_TRW_EBC450M SG_ 1408 MFN_Motorleistung_ 5000;
BA_REL_ "GenSigTimeoutTime" BU_SG_REL_ Bremse_TRW_ESP SG_ 1408 MFN_Motorleistung_ 5000;
BA_REL_ "GenSigTimeoutTime" BU_SG_REL_ EPB_TRW SG_ 1408 MFN_Motorleistung_ 5000;
BA_REL_ "GenSigTimeoutTime" BU_SG_REL_ EPB_TRW SG_ 1408 MFN_Zylinder 5000;
BA_REL_ "GenSigTimeoutTime" BU_SG_REL_ EPB_TRW SG_ 1408 MFN_Zylinder_ 5000;
BA_REL_ "GenSigTimeoutTime" BU_SG_REL_ Bremse_TRW_EBC450M SG_ 1408 MFN_Hubraum 5000;
BA_REL_ "GenSigTimeoutTime" BU_SG_REL_ Bremse_TRW_ESP SG_ 1408 MFN_Hubraum 5000;
BA_REL_ "GenSigTimeoutTime" BU_SG_REL_ EPB_TRW SG_ 1408 MFN_Hubraum 5000;
BA_REL_ "GenSigTimeoutTime" BU_SG_REL_ Gateway_PQ35 SG_ 1408 MFN_Hubraum 5000;
BA_REL_ "GenSigTimeoutTime" BU_SG_REL_ Bremse_TRW_EBC450M SG_ 1408 MFN_Hubraum_ 5000;
BA_REL_ "GenSigTimeoutTime" BU_SG_REL_ Bremse_TRW_ESP SG_ 1408 MFN_Hubraum_ 5000;
BA_REL_ "GenSigTimeoutTime" BU_SG_REL_ EPB_TRW SG_ 1408 MFN_Hubraum_ 5000;
BA_REL_ "GenSigTimeoutTime" BU_SG_REL_ Gateway_PQ35 SG_ 1408 MFN_Hubraum_ 5000;
BA_REL_ "GenSigTimeoutTime" BU_SG_REL_ Bremse_TRW_EBC450M SG_ 1408 MFN_Ansaugsys 5000;
BA_REL_ "GenSigTimeoutTime" BU_SG_REL_ Bremse_TRW_ESP SG_ 1408 MFN_Ansaugsys 5000;
BA_REL_ "GenSigTimeoutTime" BU_SG_REL_ Bremse_TRW_EBC450M SG_ 1408 MFN_Ansaugsys_ 5000;
BA_REL_ "GenSigTimeoutTime" BU_SG_REL_ Bremse_TRW_ESP SG_ 1408 MFN_Ansaugsys_ 5000;
BA_REL_ "GenSigTimeoutTime" BU_SG_REL_ Getriebe_DQ_Hyb SG_ 1154 MH1_VM_Mom_oE 500;
BA_REL_ "GenSigTimeoutTime" BU_SG_REL_ Getriebe_DQ_Hyb SG_ 1154 MH1_IstStatusK0 500;
BA_REL_ "GenSigTimeoutTime" BU_SG_REL_ Getriebe_DQ_Hyb SG_ 1154 MH1_Startmodus_PQ35 500;
BA_REL_ "GenSigTimeoutTime" BU_SG_REL_ Getriebe_DQ_Hyb SG_ 1154 MH1_VM_aktiv 500;
BA_REL_ "GenSigTimeoutTime" BU_SG_REL_ Getriebe_DQ_Hyb SG_ 1154 MH1_Zielzustand_Hybrid 500;
BA_REL_ "GenSigTimeoutTime" BU_SG_REL_ Getriebe_DQ_Hyb SG_ 1154 MH1_Schaltverh 500;
BA_REL_ "GenSigTimeoutTime" BU_SG_REL_ Getriebe_DQ_Hyb SG_ 1154 MH1_VerlParam_Msum 500;
BA_REL_ "GenSigTimeoutTime" BU_SG_REL_ Getriebe_DQ_Hyb SG_ 1154 MH1_MomVerlauf_EM 500;
BA_REL_ "GenSigTimeoutTime" BU_SG_REL_ Getriebe_DQ_Hyb SG_ 1154 MH1_E_Faktor 500;
BA_REL_ "GenSigTimeoutTime" BU_SG_REL_ Getriebe_DQ_Hyb SG_ 1154 MH1_Drehzahl_VM 500;
BA_REL_ "GenSigTimeoutTime" BU_SG_REL_ Getriebe_DQ_Hyb SG_ 1154 MH1_LowSpeedModus 500;
BA_REL_ "GenSigTimeoutTime" BU_SG_REL_ Getriebe_DQ_Hyb SG_ 1154 MH1_ACCGRA_aktiv 500;
BA_REL_ "GenSigTimeoutTime" BU_SG_REL_ Getriebe_DQ_Hyb SG_ 1154 MH1_Bremspedalwert 500;
BA_REL_ "GenSigTimeoutTime" BU_SG_REL_ Gateway_PQ35 SG_ 1823 MSI_KD_Fehler 1000;
BA_REL_ "GenSigTimeoutTime" BU_SG_REL_ AFS SG_ 1428 NI2_Checksum 500;
BA_REL_ "GenSigTimeoutTime" BU_SG_REL_ LWR SG_ 1428 NI2_Checksum 500;
BA_REL_ "GenSigTimeoutTime" BU_SG_REL_ AFS SG_ 1428 NI2_Zaehler 500;
BA_REL_ "GenSigTimeoutTime" BU_SG_REL_ LWR SG_ 1428 NI2_Zaehler 500;
BA_REL_ "GenSigTimeoutTime" BU_SG_REL_ AFS SG_ 1428 NI2_Hoehenflag 500;
BA_REL_ "GenSigTimeoutTime" BU_SG_REL_ AFS SG_ 1428 NI2_Hoehe_VL 500;
BA_REL_ "GenSigTimeoutTime" BU_SG_REL_ LWR SG_ 1428 NI2_Hoehe_VL 500;
BA_REL_ "GenSigTimeoutTime" BU_SG_REL_ AFS SG_ 1428 NI2_Hoehe_VL_Roh 500;
BA_REL_ "GenSigTimeoutTime" BU_SG_REL_ AFS SG_ 1428 NI2_Hoehe_VR 500;
BA_REL_ "GenSigTimeoutTime" BU_SG_REL_ LWR SG_ 1428 NI2_Hoehe_VR 500;
BA_REL_ "GenSigTimeoutTime" BU_SG_REL_ AFS SG_ 1428 NI2_Hoehe_VR_Roh 500;
BA_REL_ "GenSigTimeoutTime" BU_SG_REL_ AFS SG_ 1428 NI2_Hoehe_HL 500;
BA_REL_ "GenSigTimeoutTime" BU_SG_REL_ LWR SG_ 1428 NI2_Hoehe_HL 500;
BA_REL_ "GenSigTimeoutTime" BU_SG_REL_ AFS SG_ 1428 NI2_Hoehe_HL_Roh 500;
BA_REL_ "GenSigTimeoutTime" BU_SG_REL_ AFS SG_ 1428 NI2_Hoehe_HR 500;
BA_REL_ "GenSigTimeoutTime" BU_SG_REL_ LWR SG_ 1428 NI2_Hoehe_HR 500;
BA_REL_ "GenSigTimeoutTime" BU_SG_REL_ AFS SG_ 1428 NI2_Hoehe_HR_Roh 500;
BA_REL_ "GenSigTimeoutTime" BU_SG_REL_ AFS SG_ 1428 NI2_AufbBeschl_VL 500;
BA_REL_ "GenSigTimeoutTime" BU_SG_REL_ AFS SG_ 1428 NI2_AufbBeschl_VR 500;
BA_REL_ "GenSigTimeoutTime" BU_SG_REL_ Getriebe_DQ SG_ 980 PL1_Checksumme 500;
BA_REL_ "GenSigTimeoutTime" BU_SG_REL_ Getriebe_DQ_Hyb SG_ 980 PL1_Checksumme 500;
BA_REL_ "GenSigTimeoutTime" BU_SG_REL_ LH_EPS_APA SG_ 980 PL1_Checksumme 500;
BA_REL_ "GenSigTimeoutTime" BU_SG_REL_ LH_EPS_ZF_2G SG_ 980 PL1_Checksumme 500;
BA_REL_ "GenSigTimeoutTime" BU_SG_REL_ LH_EPS_ZF_3G SG_ 980 PL1_Checksumme 500;
BA_REL_ "GenSigTimeoutTime" BU_SG_REL_ Bremse_TRW_EBC450M SG_ 980 PL1_Zaehler 500;
BA_REL_ "GenSigTimeoutTime" BU_SG_REL_ Getriebe_DQ SG_ 980 PL1_Zaehler 500;
BA_REL_ "GenSigTimeoutTime" BU_SG_REL_ Getriebe_DQ_Hyb SG_ 980 PL1_Zaehler 500;
BA_REL_ "GenSigTimeoutTime" BU_SG_REL_ LH_EPS_APA SG_ 980 PL1_Zaehler 500;
BA_REL_ "GenSigTimeoutTime" BU_SG_REL_ LH_EPS_ZF_2G SG_ 980 PL1_Zaehler 500;
BA_REL_ "GenSigTimeoutTime" BU_SG_REL_ LH_EPS_ZF_3G SG_ 980 PL1_Zaehler 500;
BA_REL_ "GenSigTimeoutTime" BU_SG_REL_ LH_EPS_APA SG_ 980 PL1_Stat_PLA_EPS 500;
BA_REL_ "GenSigTimeoutTime" BU_SG_REL_ LH_EPS_ZF_2G SG_ 980 PL1_Stat_PLA_EPS 500;
BA_REL_ "GenSigTimeoutTime" BU_SG_REL_ LH_EPS_ZF_3G SG_ 980 PL1_Stat_PLA_EPS 500;
BA_REL_ "GenSigTimeoutTime" BU_SG_REL_ LH_EPS_APA SG_ 980 PL1_LW_Soll 500;
BA_REL_ "GenSigTimeoutTime" BU_SG_REL_ LH_EPS_ZF_2G SG_ 980 PL1_LW_Soll 500;
BA_REL_ "GenSigTimeoutTime" BU_SG_REL_ LH_EPS_ZF_3G SG_ 980 PL1_LW_Soll 500;
BA_REL_ "GenSigTimeoutTime" BU_SG_REL_ LH_EPS_APA SG_ 980 PL1_LW_Soll_Sign 500;
BA_REL_ "GenSigTimeoutTime" BU_SG_REL_ LH_EPS_ZF_2G SG_ 980 PL1_LW_Soll_Sign 500;
BA_REL_ "GenSigTimeoutTime" BU_SG_REL_ LH_EPS_ZF_3G SG_ 980 PL1_LW_Soll_Sign 500;
BA_REL_ "GenSigTimeoutTime" BU_SG_REL_ Bremse_MK60EC SG_ 980 PL1_Stat_PLA_ESP 500;
BA_REL_ "GenSigTimeoutTime" BU_SG_REL_ Bremse_TRW_EBC450M SG_ 980 PL1_Stat_PLA_ESP 500;
BA_REL_ "GenSigTimeoutTime" BU_SG_REL_ Bremse_TRW_ESP SG_ 980 PL1_Stat_PLA_ESP 500;
BA_REL_ "GenSigTimeoutTime" BU_SG_REL_ Bremse_MK60EC SG_ 980 PL1_Bremsmoment 500;
BA_REL_ "GenSigTimeoutTime" BU_SG_REL_ Bremse_TRW_EBC450M SG_ 980 PL1_Bremsmoment 500;
BA_REL_ "GenSigTimeoutTime" BU_SG_REL_ Bremse_TRW_ESP SG_ 980 PL1_Bremsmoment 500;
BA_REL_ "GenSigTimeoutTime" BU_SG_REL_ Getriebe_DQ SG_ 980 PL1_Bremsmoment 500;
BA_REL_ "GenSigTimeoutTime" BU_SG_REL_ Getriebe_DQ_Hyb SG_ 980 PL1_Bremsmoment 500;
BA_REL_ "GenSigTimeoutTime" BU_SG_REL_ Bremse_MK60EC SG_ 1494 PLS_Bremsleuchte 1000;
BA_REL_ "GenSigTimeoutTime" BU_SG_REL_ Bremse_TRW_ESP SG_ 1494 PLS_Bremsleuchte 1000;
BA_REL_ "GenSigTimeoutTime" BU_SG_REL_ Bremse_MK60EC SG_ 714 QS2_Ist_Wert 500;
BA_REL_ "GenSigTimeoutTime" BU_SG_REL_ Bremse_MK60EC SG_ 714 QS2_Soll_Wert 500;
BA_REL_ "GenSigTimeoutTime" BU_SG_REL_ Bremse_MK60EC SG_ 714 QS2_Status_VAQ 500;
BA_REL_ "GenSigTimeoutTime" BU_SG_REL_ Bremse_MK60EC SG_ 714 QS2_Gleichlauf 500;
BA_REL_ "GenSigTimeoutTime" BU_SG_REL_ Gateway_PQ35 SG_ 714 QS2_KD_Fehler 500;
BA_REL_ "GenSigTimeoutTime" BU_SG_REL_ Bremse_TRW_EBC450M SG_ 1500 VL1_Motor_SG 1000;
BA_REL_ "GenSigTimeoutTime" BU_SG_REL_ Bremse_TRW_ESP SG_ 1500 VL1_Motor_SG 1000;
BA_REL_ "GenSigTimeoutTime" BU_SG_REL_ Bremse_TRW_EBC450M SG_ 1500 VL1_Getr_SG 1000;
BA_REL_ "GenSigTimeoutTime" BU_SG_REL_ Bremse_TRW_ESP SG_ 1500 VL1_Getr_SG 1000;
BA_REL_ "GenSigTimeoutTime" BU_SG_REL_ Motor_Hybrid SG_ 1500 VL1_ABS 1000;
BA_REL_ "GenSigTimeoutTime" BU_SG_REL_ Motor_Otto SG_ 1500 VL1_ABS 1000;
BA_REL_ "GenSigTimeoutTime" BU_SG_REL_ Bremse_TRW_EBC450M SG_ 1500 VL1_LSM 1000;
BA_REL_ "GenSigTimeoutTime" BU_SG_REL_ Bremse_TRW_ESP SG_ 1500 VL1_LSM 1000;
BA_REL_ "GenSigTimeoutTime" BU_SG_REL_ Motor_Hybrid SG_ 1500 VL1_LSM 1000;
BA_REL_ "GenSigTimeoutTime" BU_SG_REL_ Motor_Otto SG_ 1500 VL1_LSM 1000;
BA_REL_ "GenSigTimeoutTime" BU_SG_REL_ Bremse_TRW_EBC450M SG_ 1500 VL1_Airbag 1000;
BA_REL_ "GenSigTimeoutTime" BU_SG_REL_ Bremse_TRW_ESP SG_ 1500 VL1_Airbag 1000;
BA_REL_ "GenSigTimeoutTime" BU_SG_REL_ Motor_Hybrid SG_ 1500 VL1_Airbag 1000;
BA_REL_ "GenSigTimeoutTime" BU_SG_REL_ Motor_Otto SG_ 1500 VL1_Airbag 1000;
BA_REL_ "GenSigTimeoutTime" BU_SG_REL_ Bremse_MK60EC SG_ 1500 VL1_Lenkhilfe 1000;
BA_REL_ "GenSigTimeoutTime" BU_SG_REL_ Bremse_MK60EC SG_ 1500 VL1_Allrad 1000;
BA_REL_ "GenSigTimeoutTime" BU_SG_REL_ Bremse_MK70MABS SG_ 1500 VL1_Allrad 1000;
BA_REL_ "GenSigTimeoutTime" BU_SG_REL_ Bremse_TRW_EBC450M SG_ 1500 VL1_Allrad 1000;
BA_REL_ "GenSigTimeoutTime" BU_SG_REL_ Bremse_TRW_ESP SG_ 1500 VL1_Allrad 1000;
BA_REL_ "GenSigTimeoutTime" BU_SG_REL_ Bremse_MK60EC SG_ 1500 VL1_ADR 1000;
BA_REL_ "GenSigTimeoutTime" BU_SG_REL_ Bremse_TRW_EBC450M SG_ 1500 VL1_ADR 1000;
BA_REL_ "GenSigTimeoutTime" BU_SG_REL_ Bremse_TRW_ESP SG_ 1500 VL1_ADR 1000;
BA_REL_ "GenSigTimeoutTime" BU_SG_REL_ HCA SG_ 1500 VL1_HCA 1000;
BA_REL_ "GenSigTimeoutTime" BU_SG_REL_ Bremse_MK60EC SG_ 1500 VL1_Soll_eq_Ist 1000;
BA_REL_ "GenSigTimeoutTime" BU_SG_REL_ Motor_Hybrid SG_ 1500 VL1_Soll_eq_Ist 1000;
BA_REL_ "GenSigTimeoutTime" BU_SG_REL_ Motor_Otto SG_ 1500 VL1_Soll_eq_Ist 1000;
BA_REL_ "GenSigTimeoutTime" BU_SG_REL_ Motor_Hybrid SG_ 1500 VL1_BSG_Komf 1000;
BA_REL_ "GenSigTimeoutTime" BU_SG_REL_ Motor_Otto SG_ 1500 VL1_BSG_Komf 1000;
BA_REL_ "GenSigTimeoutTime" BU_SG_REL_ Motor_Hybrid SG_ 1500 VL1_Lenksaeule 1000;
BA_REL_ "GenSigTimeoutTime" BU_SG_REL_ Motor_Otto SG_ 1500 VL1_Lenksaeule 1000;
BA_REL_ "GenSigTimeoutTime" BU_SG_REL_ Motor_Hybrid SG_ 1500 VL1_Gateway 1000;
BA_REL_ "GenSigTimeoutTime" BU_SG_REL_ Motor_Otto SG_ 1500 VL1_Gateway 1000;
BA_REL_ "GenSigTimeoutTime" BU_SG_REL_ Motor_Diesel SG_ 1500 VL1_Clima_Komf 1000;
BA_REL_ "GenSigTimeoutTime" BU_SG_REL_ Motor_Hybrid SG_ 1500 VL1_Clima_Komf 1000;
BA_REL_ "GenSigTimeoutTime" BU_SG_REL_ Motor_Otto SG_ 1500 VL1_Clima_Komf 1000;
BA_REL_ "GenSigTimeoutTime" BU_SG_REL_ Bremse_TRW_EBC450M SG_ 1500 VL1_Anhaenger 1000;
BA_REL_ "GenSigTimeoutTime" BU_SG_REL_ Bremse_TRW_ESP SG_ 1500 VL1_Anhaenger 1000;
BA_REL_ "GenSigTimeoutTime" BU_SG_REL_ Motor_Diesel SG_ 1488 SY1_Verbauinfo 1000;
BA_REL_ "GenSigTimeoutTime" BU_SG_REL_ Bremse_TRW_EBC450M SG_ 1488 SY1_Lenker 1000;
BA_REL_ "GenSigTimeoutTime" BU_SG_REL_ Bremse_TRW_ESP SG_ 1488 SY1_Lenker 1000;
BA_REL_ "GenSigTimeoutTime" BU_SG_REL_ Motor_Diesel SG_ 1488 SY1_Lenker 1000;
BA_REL_ "GenSigTimeoutTime" BU_SG_REL_ Daempfer SG_ 1488 SY1_Transportmode 1000;
BA_REL_ "GenSigTimeoutTime" BU_SG_REL_ Motor_Diesel SG_ 1488 SY1_Transportmode 1000;
BA_REL_ "GenSigTimeoutTime" BU_SG_REL_ Motor_Hybrid SG_ 1488 SY1_Transportmode 1000;
BA_REL_ "GenSigTimeoutTime" BU_SG_REL_ Motor_Otto SG_ 1488 SY1_Transportmode 1000;
BA_REL_ "GenSigTimeoutTime" BU_SG_REL_ Bremse_TRW_EBC450M SG_ 1488 SY1_Relais_FAS_Zweig 1000;
BA_REL_ "GenSigTimeoutTime" BU_SG_REL_ Bremse_TRW_ESP SG_ 1488 SY1_Relais_FAS_Zweig 1000;
BA_REL_ "GenSigTimeoutTime" BU_SG_REL_ HCA SG_ 1488 SY1_Relais_FAS_Zweig 1000;
BA_REL_ "GenSigTimeoutTime" BU_SG_REL_ Motor_Diesel SG_ 1488 SY1_QRS_Messmodus 1000;
BA_REL_ "GenSigTimeoutTime" BU_SG_REL_ Motor_Hybrid SG_ 1488 SY1_QRS_Messmodus 1000;
BA_REL_ "GenSigTimeoutTime" BU_SG_REL_ Motor_Otto SG_ 1488 SY1_QRS_Messmodus 1000;
BA_REL_ "GenSigTimeoutTime" BU_SG_REL_ AFS SG_ 1488 SY1_NWDF_gueltig 1000;
BA_REL_ "GenSigTimeoutTime" BU_SG_REL_ FLA SG_ 1488 SY1_NWDF_gueltig 1000;
BA_REL_ "GenSigTimeoutTime" BU_SG_REL_ LWR SG_ 1488 SY1_NWDF_gueltig 1000;
BA_REL_ "GenSigTimeoutTime" BU_SG_REL_ AFS SG_ 1488 SY1_NWDF 1000;
BA_REL_ "GenSigTimeoutTime" BU_SG_REL_ FLA SG_ 1488 SY1_NWDF 1000;
BA_REL_ "GenSigTimeoutTime" BU_SG_REL_ LWR SG_ 1488 SY1_NWDF 1000;
VAL_ 1160 MO6_SollM_Getr 255 "Fehler" ;
VAL_ 1160 MO6_Ist_Moment 255 "Fehler" ;
VAL_ 1160 MO6_Hoeheninfo 255 "Fehler" ;
VAL_ 1160 MO6_GRA_Soll 254 "GRA_aus" 255 "nicht_erlaubt" ;
VAL_ 1160 MO6_MomIntGeEing 0 "Integral_bis_Limit_gefuellt" 255 "volle_Verfuegbarkeit_akt_vorh" ;
VAL_ 1160 MO6_FF_Mux05 255 "nicht_genutzt" ;
VAL_ 1160 MO6_FF_Mux06 255 "nicht_genutzt" ;
VAL_ 1160 MO6_FF_Mux07 255 "nicht_genutzt" ;
VAL_ 1160 MO6_FF_Mux08 255 "nicht_genutzt" ;
VAL_ 1160 MO6_FF_Mux09 255 "nicht_genutzt" ;
VAL_ 1160 MO6_FF_Mux10 255 "nicht_genutzt" ;
VAL_ 1160 MO6_FF_Mux11 255 "nicht_genutzt" ;
VAL_ 1160 MO6_FF_Mux12 255 "nicht_genutzt" ;
VAL_ 1160 MO6_FF_Mux13 255 "nicht_genutzt" ;
VAL_ 1160 MO6_FF_Mux14 255 "nicht_genutzt" ;
VAL_ 1160 MO6_FF_Mux15 255 "nicht_genutzt" ;
VAL_ 1160 MO6_Freigabe_GRA 0 "nicht_freigegeben" 1 "freigegeben" ;
VAL_ 1160 MO6_Schutz_Toel 0 "keine_Anforderung" 1 "Schaltanforderung" ;
VAL_ 1160 MO6_Luftpfad_akt 0 "keinEingriff_od_nur_ueb_Zundpfad" 1 "Eingriff_ueber_Luftpfad" ;
VAL_ 1160 MO6_RegPartikel 0 "keine_Beeinflussung" 1 "Beeinflussung" ;
VAL_ 1416 MO7_LL_Solldz 0 "keine_Anf_einer_erhoehten_LL_DZ" 1 "LLDZ_hat_Wert_1_Stufe_erreicht" ;
VAL_ 1416 MO7_Fehler_VBegr 0 "V_Begrenzung_nicht_moeglich" 1 "V_Begrenzung_moeglich" ;
VAL_ 1416 MO7_Sta_VBegr 0 "inaktiv" 1 "aktiv" ;
VAL_ 1416 MO7_Fehlereintr 0 "kein_Fehlerspeichereintrag" 1 "Fehlerspeichereintrag" ;
VAL_ 1416 MO7_StaOeltemp 0 "iO" 1 "n_iO" ;
VAL_ 1416 MO7_Sta_PTC 0 "PTC_100_Prozent_aktiv" 1 "PTC_66_Prozent_aktiv" 3 "PTC_33_Prozent_aktiv" 7 "PTC_aus" ;
VAL_ 1416 MO7_DFM 255 "Fehler" ;
VAL_ 1416 MO7_Hoeheninfo 255 "Fehler" ;
VAL_ 1416 MO7_Gradient_Dz 127 "ist_groessergleich_127_min" ;
VAL_ 1416 MO7_GradientVorz 0 "positives_Vorzeichen" 1 "negatives_Vorzeichen" ;
VAL_ 1416 MO7_Ladedruckneu 255 "Fehler" ;
VAL_ 1416 MO7_PTC_bereit 0 "kein_3stuf_PTC_verbaut" ;
VAL_ 1416 MO7_Mot_weckfaehig 0 "kein_Wecken_ACAN" 1 "Wecken_ACAN_gef" ;
VAL_ 1416 MO7_Zus_Kuehl 0 "nein" 1 "ja" ;
VAL_ 1416 MO7_SleepInd 0 "CAN_wird_benoetigt" 1 "Sleep_bereit" ;
VAL_ 1416 MO7_RueckLLDz 0 "keine_Anf_einer_erhoehten_LL_DZ" 1 "LLDZ_hat_Wert_2_Stufe_erreicht" ;
VAL_ 1416 MO7_Lastabwurf 0 "Stufe_0" 1 "Stufe_1" 2 "Stufe_2" 3 "Stufe_3" ;
VAL_ 1416 MO7_Gen_ein 0 "Generator_aus" 1 "Generator_ein" ;
VAL_ 1416 MO7_Lastabw_Heiz 0 "Hochleistungsheizsys_deaktiviert" 1 "Hochleistungsheizsys_aktivierbar" ;
VAL_ 1416 MO7_StaGluehk 15 "Fehler" ;
VAL_ 1416 MO7_Oeltemp 0 "nicht_verbaut" 1 "Init" 255 "Fehler" ;
VAL_ 1162 MO8_AnzeigeDZ 4095 "Fehler" ;
VAL_ 1162 WBA_Effizienzmodus 0 "nicht_im_Effizienz_Modus" 1 "Effizienz_Modus" ;
VAL_ 1162 MO8_SGT_Soundakt 0 "kein_Stellgliedtest" 1 "Anf_des_Stellgliedtests" ;
VAL_ 1162 MO8_Spoiler_ausf 0 "Spoiler_nicht_ausfahren" 1 "Spoiler_ausfahren" ;
VAL_ 1162 MO8_Sportschalter 0 "Sportschalter_nicht_aktiv" 1 "Sportschalter_aktiv" ;
VAL_ 1162 MO8_LampeDZBegr 0 "Lampe_aus" 1 "Lampe_ein" ;
VAL_ 1162 MO8_Enable_Oeldr_Motor 0 "Oeldruckausw_Kombi" 1 "Oeldruckausw_Motor" ;
VAL_ 1162 MO8_Oeldr_Warn_Motor 0 "Lampe_aus" 1 "Lampe_ein" ;
VAL_ 1162 MO8_Avus_Motorschutz 0 "keine_Warnung" 1 "DZwarnung_1" 2 "DZwarnung_2" 3 "DZwarnung_3" ;
VAL_ 1162 MO_Schaltempf_verfbar 0 "nicht_verfuegbar" 1 "verfuegbar" ;
VAL_ 1162 MO_Istgang 0 "kein_Gang_eingelegt" 1 "Gang_1" 2 "Gang_2" 3 "Gang_3" 4 "Gang_4" 5 "Gang_5" 6 "Gang_6" 7 "Gang_7" 8 "Gang_8" 9 "Gang_9" ;
VAL_ 1162 MO_Sollgang 0 "keine_Empfehlung" 1 "Gang_1" 2 "Gang_2" 3 "Gang_3" 4 "Gang_4" 5 "Gang_5" 6 "Gang_6" 7 "Gang_7" 8 "Gang_8" 9 "Gang_9" ;
VAL_ 644 MOB_Standby 0 "Bremse_in_0_Stellung" 1 "Bremse_in_Vorhaltposition_bringe" ;
VAL_ 644 MOB_Anhaltewunsch 0 "kein_Haltewunsch" 1 "Fzg_haelt_an" ;
VAL_ 644 MOB_Freigabe 0 "Bremsanf_nicht_freigegeb" 1 "Bremsanf_freigegeben" ;
VAL_ 644 MOB_Bremsmom 8191 "Fehler" ;
VAL_ 1800 MC1_Anz_Betrieb 0 "Benzinbetrieb" 1 "Gasbetrieb" ;
VAL_ 1800 MC1_Schalter 0 "Benzin_od_Schalter_nicht_verb" 1 "Gasbetrieb" ;
VAL_ 1800 MC1_akt_Betrieb 0 "Benzinbetrieb" 1 "Gasbetrieb" ;
VAL_ 1800 MC1_CNG_LPG 0 "CNG" 1 "LPG" ;
VAL_ 1800 MO_LPG_Tankstopp 0 "kein_Tankstopp" 1 "Tankstopp_erkannt" ;
VAL_ 1800 MO_Erdgasqualitaet 0 "Anzeige_in_MFA_nicht_auswaehlbar" 1 "Anzeige_waehrend_QualAdaption_nach_Betankung_oder_Fehler" 2 "Qualitaet_100Proz" 3 "Qualitaet_90Proz" 4 "Qualitaet_80Proz" 5 "Qualitaet_70Proz" 6 "nicht_definiert" 7 "nicht_definiert" ;
VAL_ 1800 MC1_Fuellungsgrad 255 "Fehler" ;
VAL_ 1800 MC1_Ueb_Verbr 0 "kein_Ueberlauf" 1 "mind_1_Ueberlauf" ;
VAL_ 1800 MO_AnzeigeGasbetrieb 0 "keine_Textmeldung" 1 "Umschaltung_Gasbetrieb" 2 "Gasbetrieb" 3 "Umschaltung_Benzinbetrieb" 4 "Benzinbetrieb" 5 "Umschaltung_nicht_moeglich" 6 "Gasbetrieb_nicht_moeglich" 7 "Benzintank_leer" ;
VAL_ 1408 MFN_Drive_Cycle 0 "nicht_erkannt" 1 "erkannt" ;
VAL_ 1408 MFN_Warmup_Cycle 0 "nicht_erkannt" 1 "erkannt" ;
VAL_ 1408 MFN_NormedTrip 0 "nicht_erkannt" 1 "erkannt" ;
VAL_ 1408 MFN_Verbrenn_Typ 0 "Diesel" 1 "Otto" ;
VAL_ 1408 MFN_Russindex 65535 "Fehler" ;
VAL_ 1408 MFN_Verschl 65535 "Fehler" ;
VAL_ 1408 MFN_Russindex_ 65535 "Fehler" ;
VAL_ 1408 MFN_Verschl_ 65535 "Fehler" ;
VAL_ 1408 MFN_KurzzeitMW 0 "kein_Wert" 255 "Fehler" ;
VAL_ 1408 MFN_Fuell_Erk 0 "deaktiviert" 1 "aktiviert" ;
VAL_ 1408 MFN_Oelwarnung 0 "keine_Warnung" 1 "Warnung" ;
VAL_ 1408 MFN_Sensorwarn 0 "keine_Warnung" 1 "Warnung" ;
VAL_ 1408 MFN_Anz_Mittel 0 "Fehler" ;
VAL_ 1408 MFN_Str_Mittel 0 "Fehler" ;
VAL_ 1408 MFN_Ansaugsys 0 "Turbo" 1 "Sauger" ;
VAL_ 1408 MFN_Ansaugsys_ 0 "Turbo" 1 "Sauger" ;
VAL_ 1154 MH1_VM_Mom_oE 255 "Fehler" ;
VAL_ 1154 MH1_IstStatusK0 0 "auf" 1 "Uebergang" 2 "zu" 3 "Fehler" ;
VAL_ 1154 MH1_Startmodus_PQ35 0 "Impulsstart" 1 "Direktstart" ;
VAL_ 1154 MH1_VM_aktiv 0 "VM_nicht_aktiv" 1 "VM_aktiv" ;
VAL_ 1154 MH1_Zielzustand_Hybrid 0 "Init" 1 "LL_VM" 2 "hyb_Fahren" 3 "EM_Fahren" 4 "Fahrbereit_EM" 5 "Fahrbereit_VM" 7 "Fehler" ;
VAL_ 1154 MH1_Schaltverh 0 "keine_Schaltverh" 1 "Schaltverhinderung" ;
VAL_ 1154 MH1_VerlParam_Msum 0 "max_Rekup_Mom" 1 "KnickDZ_Rekup_Kurve" 2 "max_EM_Moment" 3 "KnickDZ_EM_Kurve" ;
VAL_ 1154 MH1_E_Faktor 0 "VM_Kennfeld" 1 "plus1" 2 "plus2" 3 "plus3" 4 "plus4" 5 "plus5" 6 "plus6" 7 "plus7" 8 "minus8" 9 "minus7" 10 "minus6" 11 "minus5" 12 "minus4" 13 "minus3" 14 "minus2" 15 "minus1" ;
VAL_ 1154 MH1_Drehzahl_VM 65280 "Fehler" ;
VAL_ 1154 MH1_max_ind_VM_Mom 255 "Fehler" ;
VAL_ 1154 MH1_Startmodus_PL71 0 "Drag_Start" 1 "slipstart_comf" 2 "slipstart_trq" 3 "slipstart_pwr" 4 "anger_comf" 5 "anger_trq" 6 "anger_pwr" 7 "Impulsstart" ;
VAL_ 1154 MH1_LowSpeedModus 0 "LowSpeed_mit_LL_DZ" 1 "LowSpeed_ohne_LL_DZ" ;
VAL_ 1154 MH1_ACCGRA_aktiv 0 "GRAACC_nicht_aktiv" 1 "GRAACC_aktiv" ;
VAL_ 1154 MH1_QB_Bremspedalwert 0 "gueltiger_Wert" 1 "Ersatz_Init_oder_Fehlerwert" ;
VAL_ 1154 MH1_Bremspedalwert 255 "Fehler" ;
VAL_ 1823 MSI_KD_Fehler 0 "kein_Fehlerspeichereintrag" 1 "Fehlerspeichereintrag" ;
VAL_ 1428 NI2_Hoehenflag 0 "kalibrierte_Hoehenwerte" 1 "Rohwerte" ;
VAL_ 1428 NI2_Hoehe_VL 254 "nicht_initialisiert" 255 "Fehler" ;
VAL_ 1428 NI2_Hoehe_VL_Roh 251 "notdef" 252 "" 253 "notdef" 254 "nicht_initialisiert" 255 "Fehler" ;
VAL_ 1428 NI2_Hoehe_VR 254 "nicht_initialisiert" 255 "Fehler" ;
VAL_ 1428 NI2_Hoehe_VR_Roh 251 "notdef" 252 "notdef" 253 "notdef" 254 "nicht_initialisiert" 255 "Fehler" ;
VAL_ 1428 NI2_Hoehe_HL 254 "nicht_initialisiert" 255 "Fehler" ;
VAL_ 1428 NI2_Hoehe_HL_Roh 251 "notdef" 252 "notdef" 253 "notdef" 254 "nicht_initialisiert" 255 "Fehler" ;
VAL_ 1428 NI2_Hoehe_HR 254 "nicht_initialisiert" 255 "Fehler" ;
VAL_ 1428 NI2_Hoehe_HR_Roh 251 "notdef" 252 "notdef" 253 "notdef" 254 "nicht_initialisiert" 255 "Fehler" ;
VAL_ 1428 NI2_AufbBeschl_VL 254 "notdef" 255 "Fehler" ;
VAL_ 1428 NI2_AufbBeschl_VR 254 "notdef" 255 "Fehler" ;
VAL_ 1349 PA3_KD_Fehler 0 "kein_Fehlerspeichereintrag" 1 "Fehlerspeichereintrag" ;
VAL_ 1355 PA5_VL_Abstand 255 "kein_Hindernis" ;
VAL_ 1355 PA5_VR_Abstand 255 "kein_Hindernis" ;
VAL_ 1355 PA5_HL_Abstand 255 "kein_Hindernis" ;
VAL_ 1355 PA5_HR_Abstand 255 "kein_Hindernis" ;
VAL_ 1355 PA5_VML_Abstand 255 "kein_Hindernis" ;
VAL_ 1355 PA5_VMR_Abstand 255 "kein_Hindernis" ;
VAL_ 1355 PA5_HML_Abstand 255 "kein_Hindernis" ;
VAL_ 1355 PA5_HMR_Abstand 255 "kein_Hindernis" ;
VAL_ 980 PL1_LW_Soll_Sign 0 "positives_Vorzeichen" 1 "negatives_Vorzeichen" ;
VAL_ 980 PL1_Stat_PLA_ESP 4 "PLA_ESP_aktivierbar" 6 "PLA_ESP_Bremse_aktiv" 8 "PLA_ESP_funktionsbereit" 9 "PLA_ESP_Neustart" 10 "PLA_ESP_Abbruch" ;
VAL_ 980 PL1_Bremsmoment 8191 "Fehler" ;
VAL_ 1494 PLS_Anf_Anz 0 "keine_Anforderung" 1 "Anzeige_Anforderung" ;
VAL_ 1494 PLS_Akustik1 0 "keine_Akustik" 1 "Akustik" ;
VAL_ 1494 PLS_PL_Exist 0 "keine_Parkluecke" 1 "Parkluecke" ;
VAL_ 1494 PLS_Akustik2 0 "keine_Akustik" 1 "Akustik" ;
VAL_ 1494 PLS_Mehrzg_Aktiv 0 "nicht_aktiv" 1 "aktiv" ;
VAL_ 1494 PLS_Pos_OK 0 "Pos_NOK" 1 "Pos_OK" ;
VAL_ 1494 PLS_PL_Seite 0 "rechts" 1 "links" ;
VAL_ 1494 PLS_Lenk_Aktiv_Hinweis 0 "keine_Info" 1 "Lenkeingriff_aktiv" ;
VAL_ 1494 PLS_Meldungen 0 "kein_Text" ;
VAL_ 1494 PLS_Fahrtrichtg_Mehrzg 0 "Vorwaerts" 1 "Rueckwaerts" ;
VAL_ 1494 PLS_Text_Multiplexer 0 "Init_keine_Anzeige" 1 "Textmeldungen_aus_1" 2 "Textmeldungen_aus_2" 3 "Textmeldungen_aus_3" ;
VAL_ 1494 PLS_Schwellpfeil_rel 0 "kein_Segment_leer" 1 "1_Segment" 2 "2_Segmente" 3 "3_Segmente" 4 "4_Segmente" 5 "5_Segmente" 6 "6_Segmente" 7 "7_Segmente" 8 "8_Segmente" 9 "9_Segmente" 10 "10_Segmente" 11 "11_Segmente" 12 "12_Segmente" 13 "13_Segmente" 14 "14_Segmente" 15 "15_Segmente_voll" ;
VAL_ 1494 PLS_Anf_Anz_Schwellpfeil 0 "Anzeige_Schwellpfeil_aus" 1 "Anzeige_Schwellpfeil_ein" ;
VAL_ 1494 PLS_Laengs_Querluecke 0 "Laengsluecke" 1 "Querluecke" ;
VAL_ 1494 PLS_Standby 0 "keine_Anzeige" 1 "Anzeige_des_Standby_Symbols" ;
VAL_ 1494 PLS_Bremssymbol 0 "keine_Anzeige" 1 "Anzeige_Bremssymbol" ;
VAL_ 1494 PLS_Kurze_Luecke 0 "keine_Kurze_Luecke" 1 "Kurze_Luecke" ;
VAL_ 1494 PLS_Schwellpfeil_abs 0 "3_Segmente__voll" 1 "2_Segmente" 2 "1_Segment" 3 "kein_Segment" ;
VAL_ 1494 PLS_Akustik 0 "keine_Akustik" 1 "Akustik_1" 2 "Akustik_2" 3 "Akustik_3" ;
VAL_ 1494 PLS_Ausparken_Aktiv 0 "Ausparken_nicht_aktiv" 1 "Ausparkfunktion_aktiv" ;
VAL_ 1494 PLS_Bremsleuchte 0 "Bremsleuchte_aus" 1 "Bremsleuchte_ein" ;
VAL_ 1494 PLS_Texte 0 "keine_Meldung" 1 "Park Assist deaktiviert (Funktion ohne vorherigem Lenkeingriff regulär beendet)" 2 "Park Assist deaktiviert, Geschwindigkeit zu hoch" 3 "Park Assist deaktiviert, Eingriff ASR ohne aktiviertem Lenkeingriff" 4 "Park Assist deaktiviert, ASR ausgeschaltet" 5 "Park Assist deaktiviert, Anhänger vorhanden ohne aktiviertem Lenkeingriff" 6 "Park Assist deaktiviert, Zeitlimit überschritten" 7 "Park Assist deaktiviert, Systemstörung ohne aktiviertem Lenkeingriff" 8 "Park Assist deaktiviert, defekt ohne aktiviertem Lenkeingriff" 9 "Stillstandszeit nicht ausreichend" 10 "Geschwindigkeit zu niedrig" 11 "Blinker setzen und Rückwärtsgang einlegen (Ausparkfunktion)" 12 "Automatisches Ausparken nicht möglich, Lücke zu klein" 13 "Geschwindigkeit zu hoch (bei aktivem Lenkeingriff)" 14 "Park Assist beendet. Geschwindigkeit zu hoch." 15 "Park Assist deaktiviert, Lenkung übernehmen!" 16 "Park Assist deaktiviert, Anhänger (bei aktiviertem Lenkeingriff)" 17 "Park Assist deaktiviert, ASR ausgeschaltet, Lenkung übernehmen (bei aktiviertem Lenkeingriff)" 18 "Park Assist deaktiviert, Zeitlimit überschritten Lenkung übernehmen (bei aktiviertem Lenkeingriff)" 19 "Lenkeingriff deaktiviert, Lenkung übernehmen" 20 "Park Assist deaktiviert, Lenkung übernehmen, Parkvorgang manuell beenden (wenn Fzg. noch schräg steht)" 21 "Park Assist deaktiviert, Geschwindigkeit zu hoch, Lenkung übernehmen (bei aktiviertem Lenkeingriff ohne Bremseingriff)" 22 "Park Assist deaktiviert, Eingriff ASR, Lenkung übernehmen" 23 "Park Assist deaktiviert, Systemstörung (bei aktiviertem Lenkeingriff)" 24 "Park Assist deaktiviert, defekt, (bei aktiviertem Lenkeingriff)" 25 "Bitte Lenkung übernehmen und Fahrt fortsetzen (Ausparken beendet)" 26 "Automatisches Ausparken nicht möglich, Lücke zu klein (bei aktivem Lenkeingriff)" 27 "Park Assist: Bremseingriff! Geschwindigkeit zu hoch (bei aktiviertem Lenkeingriff mit Bremseingriff)" 28 "Hindernis erkannt, bitte Bremse betätigen" 29 "Achtung! Bremse öffnet" 30 "Achtung! Seitliches Hindernis! (Flankenschutz)" 31 "Park Assist beendet. Lenkung übernehmen." 32 "Dauertonbereich verändert, besondere Vorsicht geboten" ;
VAL_ 714 QS2_Ist_Wert 255 "Fehler" ;
VAL_ 714 QS2_Soll_Wert 255 "Fehler" ;
VAL_ 714 QS2_Status_VAQ 0 "Init" 1 "Fehler_auf" 2 "Kom_gestoert" 3 "norm_ohne_ESP_Eing" 4 "norm_mit_ESP_Eing" 5 "norm_Abschaltung" 6 "Fehler_zu" ;
VAL_ 714 QS2_Gleichlauf 0 "Schlupf" 1 "Gleichlauf" ;
VAL_ 714 QS2_KD_Fehler 0 "kein_Fehlerspeichereintrag" 1 "Fehlerspeichereintrag" ;
VAL_ 1500 VL1_Motor_SG 0 "kein_Sollverbau" 1 "Sollverbau" ;
VAL_ 1500 VL1_Getr_SG 0 "kein_Sollverbau" 1 "Sollverbau" ;
VAL_ 1500 VL1_ABS 0 "kein_Sollverbau" 1 "Sollverbau" ;
VAL_ 1500 VL1_Kombi 0 "kein_Sollverbau" 1 "Sollverbau" ;
VAL_ 1500 VL1_LSM 0 "kein_Sollverbau" 1 "Sollverbau" ;
VAL_ 1500 VL1_Airbag 0 "kein_Sollverbau" 1 "Sollverbau" ;
VAL_ 1500 VL1_Lenkhilfe 0 "kein_Sollverbau" 1 "Sollverbau" ;
VAL_ 1500 VL1_dyn_LWR 0 "kein_Sollverbau" 1 "Sollverbau" ;
VAL_ 1500 VL1_res_08 0 "kein_Sollverbau" 1 "Sollverbau" ;
VAL_ 1500 VL1_Allrad 0 "kein_Sollverbau" 1 "Sollverbau" ;
VAL_ 1500 VL1_ADR 0 "kein_Sollverbau" 1 "Sollverbau" ;
VAL_ 1500 VL1_ADR_getrennt 0 "ADR_angeschlossen" 1 "ADR_getrennt" ;
VAL_ 1500 VL1_EPB 0 "kein_Sollverbau" 1 "Sollverbau" ;
VAL_ 1500 VL1_res_13 0 "kein_Sollverbau" 1 "Sollverbau" ;
VAL_ 1500 VL1_Daempfer 0 "kein_Sollverbau" 1 "Sollverbau" ;
VAL_ 1500 VL1_Quersperre 0 "kein_Sollverbau" 1 "Sollverbau" ;
VAL_ 1500 VL1_MotorSlave 0 "kein_Sollverbau" 1 "Sollverbau" ;
VAL_ 1500 VL1_SWA 0 "kein_Sollverbau" 1 "Sollverbau" ;
VAL_ 1500 VL1_HCA 0 "kein_Sollverbau" 1 "Sollverbau" ;
VAL_ 1500 VL1_RKA_Plus 0 "kein_Sollverbau" 1 "Sollverbau" ;
VAL_ 1500 VL1_PLA 0 "kein_Sollverbau" 1 "Sollverbau" ;
VAL_ 1500 VL1_WFS_KBI 0 "kein_Sollverbau" 1 "Sollverbau" ;
VAL_ 1500 VL1_Kombi_KBI 0 "kein_Sollverbau" 1 "Sollverbau" ;
VAL_ 1500 VL1_Soll_eq_Ist 0 "Sollverbau_ungleich_Istverbau" 1 "Sollverbau_gleich_Istverbau" ;
VAL_ 1500 VL1_BSG_Komf 0 "kein_Sollverbau" 1 "Sollverbau" ;
VAL_ 1500 VL1_ZKE 0 "kein_Sollverbau" 1 "Sollverbau" ;
VAL_ 1500 VL1_TSG_FT 0 "kein_Sollverbau" 1 "Sollverbau" ;
VAL_ 1500 VL1_TSG_BT 0 "kein_Sollverbau" 1 "Sollverbau" ;
VAL_ 1500 VL1_TSG_HL 0 "kein_Sollverbau" 1 "Sollverbau" ;
VAL_ 1500 VL1_TSG_HR 0 "kein_Sollverbau" 1 "Sollverbau" ;
VAL_ 1500 VL1_Memory 0 "kein_Sollverbau" 1 "Sollverbau" ;
VAL_ 1500 VL1_Dachmodul_K 0 "kein_Sollverbau" 1 "Sollverbau" ;
VAL_ 1500 VL1_Zentralelektrik_II 0 "kein_Sollverbau" 1 "Sollverbau" ;
VAL_ 1500 VL1_RDK 0 "kein_Sollverbau" 1 "Sollverbau" ;
VAL_ 1500 VL1_Lenksaeule 0 "kein_Sollverbau" 1 "Sollverbau" ;
VAL_ 1500 VL1_Gateway 0 "kein_Sollverbau" 1 "Sollverbau" ;
VAL_ 1500 VL1_Clima_Komf 0 "kein_Sollverbau" 1 "Sollverbau" ;
VAL_ 1500 VL1_Einparkhilfe 0 "kein_Sollverbau" 1 "Sollverbau" ;
VAL_ 1500 VL1_PTC_Heizung 0 "kein_Sollverbau" 1 "Sollverbau" ;
VAL_ 1500 VL1_Standheiz 0 "kein_Sollverbau" 1 "Sollverbau" ;
VAL_ 1500 VL1_Verdeck 0 "kein_Sollverbau" 1 "Sollverbau" ;
VAL_ 1500 VL1_RSE_I 0 "kein_Sollverbau" 1 "Sollverbau" ;
VAL_ 1500 VL1_res_42 0 "kein_Sollverbau" 1 "Sollverbau" ;
VAL_ 1500 VL1_MDI_I 0 "kein_Sollverbau" 1 "Sollverbau" ;
VAL_ 1500 VL1_Anhaenger 0 "kein_Sollverbau" 1 "Sollverbau" ;
VAL_ 1500 VL1_Memory_BF 0 "kein_Sollverbau" 1 "Sollverbau" ;
VAL_ 1500 VL1_Easy_Entry_VF 0 "kein_Sollverbau" 1 "Sollverbau" ;
VAL_ 1500 VL1_Easy_Entry_VB 0 "kein_Sollverbau" 1 "Sollverbau" ;
VAL_ 1500 VL1_Heckdeckel 0 "kein_Sollverbau" 1 "Sollverbau" ;
VAL_ 1500 VL1_Rearview 0 "kein_Sollverbau" 1 "Sollverbau" ;
VAL_ 1500 VL1_Sonderfzg_SG 0 "kein_Sollverbau" 1 "Sollverbau" ;
VAL_ 1500 VL1_Tastenmodul 0 "kein_Sollverbau" 1 "Sollverbau" ;
VAL_ 1500 VL1_Kompass 0 "kein_Sollverbau" 1 "Sollverbau" ;
VAL_ 1500 VL1_WFS_K 0 "kein_Sollverbau" 1 "Sollverbau" ;
VAL_ 1500 VL1_GSM_Pager 0 "kein_Sollverbau" 1 "Sollverbau" ;
VAL_ 1500 VL1_InfoElektronik 0 "kein_Sollverbau" 1 "Sollverbau" ;
VAL_ 1500 VL1_DSP 0 "kein_Sollverbau" 1 "Sollverbau" ;
VAL_ 1500 VL1_DAB 0 "kein_Sollverbau" 1 "Sollverbau" ;
VAL_ 1500 VL1_Telematik 0 "kein_Sollverbau" 1 "Sollverbau" ;
VAL_ 1500 VL1_Navigation 0 "kein_Sollverbau" 1 "Sollverbau" ;
VAL_ 1500 VL1_TV_Tuner 0 "kein_Sollverbau" 1 "Sollverbau" ;
VAL_ 1500 VL1_Neigungsmodul_I 0 "kein_Sollverbau" 1 "Sollverbau" ;
VAL_ 1500 VL1_Radio 0 "kein_Sollverbau" 1 "Sollverbau" ;
VAL_ 1500 VL1_Telefon 0 "kein_Sollverbau" 1 "Sollverbau" ;
VAL_ 1488 SY1_CAN_extern 0 "CANextern_getrennt" 1 "CANextern_zugeschaltet" ;
VAL_ 1488 SY1_Diag_Ant 0 "zZt_keine_Antrieb_Diagnose" 1 "CAN_Antrieb_in_Diagnose" ;
VAL_ 1488 SY1_Sleep_Komf 0 "keine_Busruhe" 1 "Busruhe" ;
VAL_ 1488 SY1_Diag_Komf 0 "zZt_keine_Komfort_Diagnose" 1 "Diagnoseanf_im_CAN_Komf_erkannt" ;
VAL_ 1488 SY1_Sleep_Info 0 "keine_Busruhe" 1 "Busruhe" ;
VAL_ 1488 SY1_Diag_Info 0 "zZt_keine_Infotainement_Diagnose" 1 "Diagnoseanf_im_CAN_Infot_erkannt" ;
VAL_ 1488 SY1_CAN_Info 0 "nicht_verbaut" 1 "verbaut" ;
VAL_ 1488 SY1_Verbauinfo 0 "ungueltig" 1 "gueltig" ;
VAL_ 1488 SY1_Fzg_Klasse 0 "A000_Klasse" 1 "A00_Klasse" 2 "A0_Klasse" 3 "A_Klasse" 4 "B_Klasse" 5 "C_Klasse" 6 "D_Klasse" 7 "T_Klasse" 8 "LT_Klasse" 9 "L_Klasse" ;
VAL_ 1488 SY1_Fzg_Marke 0 "VW_Volkswagen" 1 "AU_Audi" 2 "SE_Seat" 3 "SK_Skoda" 4 "VN_VWNutzfzg" 5 "Bugatti" 6 "Lamborghini" 7 "Bentley" 8 "RollsRoyce" 14 "Ford" 15 "Porsche" ;
VAL_ 1488 SY1_Fzg_Derivat 0 "Kurzheck_Multivan" 1 "Stufenheck_Nutz" 2 "Variant" 3 "Fliessheck" 4 "Coupe_Sportwagen" 5 "Cabrio_Roadstar_Spider" 6 "Offroad" 7 "CityVan_PickUp" 8 "MPV" 9 "Sonstige" 15 "nicht_bekannt" ;
VAL_ 1488 SY1_Fzg_Index 0 "kurzer_Radstand" 1 "langer_Radstand" 2 "geaenderte_Front_Heck" 3 "Syncro" 4 "Hochmotorisierung" 5 "offene_Aufbauten" 6 "geschlossene_Aufbauten" 7 "Flachdach" 8 "Hochdach" 9 "Sonstige" 15 "nicht_bekannt" ;
VAL_ 1488 SY1_Lenker 0 "Linkslenker" 1 "Rechtslenker" ;
VAL_ 1488 SY1_Tueren 0 "Kleiner_vier_Tueren" 1 "Vier_Tueren_oder_mehr" ;
VAL_ 1488 SY1_Transportmode 0 "nicht_aktiv" 1 "aktiv" ;
VAL_ 1488 SY1_Fehlereintr 0 "kein_Fehlerspeichereintrag" 1 "Fehlerspeichereintrag" ;
VAL_ 1488 SY1_Relais_FAS_Zweig 0 "Relais_geschlossen" 1 "Relais_planmaessig_geoeffnet" 2 "Relais_im_Fehlerfall_geoeffnet" 3 "reserviert" ;
VAL_ 1488 SY1_ELV_Lock_Supply 0 "keine_Freigabe" 1 "Freigabe" ;
VAL_ 1488 SY1_QRS_Messmodus 0 "QRS_aus" 1 "QRS_ein" ;
VAL_ 1488 SY1_NWDF_gueltig 0 "NWDF_Fkt_nicht_unterstuetzt" 1 "NWDF_Fkt_unterstuetzt" ;
VAL_ 1488 SY1_NWDF 0 "Ueberwachung_nicht_freigegeben" 1 "Ueberwachung_freigegeben" ;
VAL_ 1488 SY1_Notbrems_Status 0 "keine_Notbremsung" 1 "Notbremssituation" ;
